VERSION ""

NS_ :

BS_:

BU_: TestTool_HS BCP_HS ECM_HS TCM_HS CGM_HS BCM_HS EBCM_OBD_HS ACCM_HS EBCM_HS TCCM_HS SAS_HS ICCM_OBD_HS ICCM_HS EPS_HS EPB_HS HMIM_HS ONSTAR_HS

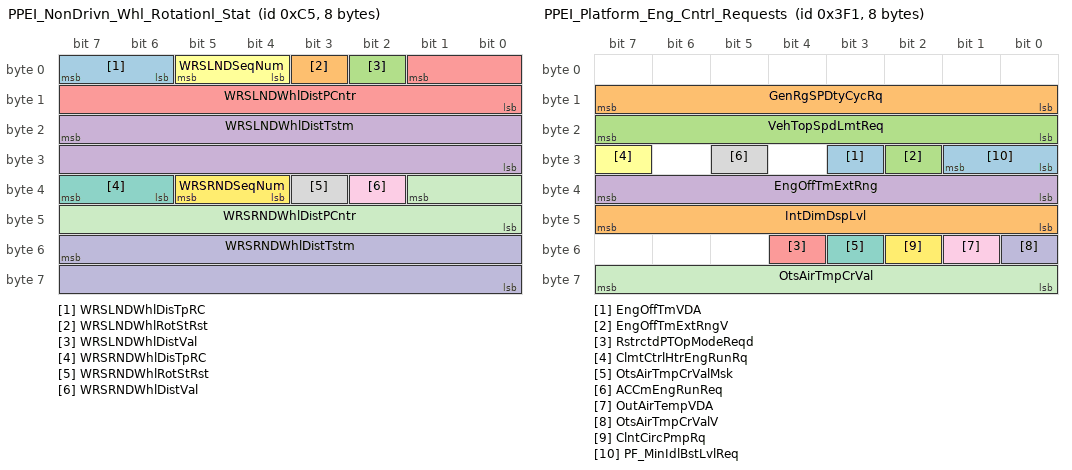
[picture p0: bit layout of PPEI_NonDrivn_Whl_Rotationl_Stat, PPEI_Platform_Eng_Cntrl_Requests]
BO_ 197 PPEI_NonDrivn_Whl_Rotationl_Stat: 8 EBCM_HS
 SG_ WRSLNDWhlDisTpRC : 7|2@0+ (1,0) [0|3] "counts"  CGM_HS,ICCM_OBD_HS,ICCM_HS,HMIM_HS,EPS_HS,BCP_HS,ONSTAR_HS,EPB_HS,TCCM_HS,BCM_HS,TCM_HS,ECM_HS
 SG_ WRSLNDWhlRotStRst : 3|1@0+ (1,0) [0|1] ""  CGM_HS,ICCM_OBD_HS,ICCM_HS,HMIM_HS,EPS_HS,BCP_HS,ONSTAR_HS,EPB_HS,TCCM_HS,BCM_HS,TCM_HS,ECM_HS
 SG_ WRSLNDWhlDistVal : 2|1@0+ (1,0) [0|1] ""  CGM_HS,ICCM_OBD_HS,ICCM_HS,HMIM_HS,EPS_HS,BCP_HS,ONSTAR_HS,EPB_HS,TCCM_HS,BCM_HS,TCM_HS,ECM_HS
 SG_ WRSLNDWhlDistTstm : 23|16@0+ (1,0) [0|65535] "counts"  CGM_HS,ICCM_OBD_HS,ICCM_HS,HMIM_HS,EPS_HS,BCP_HS,ONSTAR_HS,EPB_HS,TCCM_HS,BCM_HS,TCM_HS,ECM_HS
 SG_ WRSLNDWhlDistPCntr : 1|10@0+ (1,0) [0|1023] "counts"  CGM_HS,ICCM_OBD_HS,ICCM_HS,HMIM_HS,EPS_HS,BCP_HS,ONSTAR_HS,EPB_HS,TCCM_HS,BCM_HS,TCM_HS,ECM_HS
 SG_ WRSLNDSeqNum : 5|2@0+ (1,0) [0|3] "counts"  CGM_HS,ICCM_OBD_HS,ICCM_HS,HMIM_HS,EPS_HS,BCP_HS,ONSTAR_HS,EPB_HS,TCCM_HS,BCM_HS,TCM_HS,ECM_HS
 SG_ WRSRNDWhlDisTpRC : 39|2@0+ (1,0) [0|3] "counts"  CGM_HS,ICCM_OBD_HS,ICCM_HS,HMIM_HS,EPS_HS,BCP_HS,ONSTAR_HS,EPB_HS,TCCM_HS,BCM_HS,TCM_HS,ECM_HS
 SG_ WRSRNDWhlRotStRst : 35|1@0+ (1,0) [0|1] ""  CGM_HS,ICCM_OBD_HS,ICCM_HS,HMIM_HS,EPS_HS,BCP_HS,ONSTAR_HS,EPB_HS,TCCM_HS,BCM_HS,TCM_HS,ECM_HS
 SG_ WRSRNDWhlDistVal : 34|1@0+ (1,0) [0|1] ""  CGM_HS,ICCM_OBD_HS,ICCM_HS,HMIM_HS,EPS_HS,BCP_HS,ONSTAR_HS,EPB_HS,TCCM_HS,BCM_HS,TCM_HS,ECM_HS
 SG_ WRSRNDWhlDistTstm : 55|16@0+ (1,0) [0|65535] "counts"  CGM_HS,ICCM_OBD_HS,ICCM_HS,HMIM_HS,EPS_HS,BCP_HS,ONSTAR_HS,EPB_HS,TCCM_HS,BCM_HS,TCM_HS,ECM_HS
 SG_ WRSRNDWhlDistPCntr : 33|10@0+ (1,0) [0|1023] "counts"  CGM_HS,ICCM_OBD_HS,ICCM_HS,HMIM_HS,EPS_HS,BCP_HS,ONSTAR_HS,EPB_HS,TCCM_HS,BCM_HS,TCM_HS,ECM_HS
 SG_ WRSRNDSeqNum : 37|2@0+ (1,0) [0|3] "counts"  CGM_HS,ICCM_OBD_HS,ICCM_HS,HMIM_HS,EPS_HS,BCP_HS,ONSTAR_HS,EPB_HS,TCCM_HS,BCM_HS,TCM_HS,ECM_HS

BO_ 1009 PPEI_Platform_Eng_Cntrl_Requests: 8 BCM_HS
 SG_ EngOffTmVDA : 27|1@0+ (1,0) [0|1] ""  ICCM_OBD_HS,ICCM_HS,EPS_HS,EBCM_OBD_HS,EPB_HS,TCCM_HS,EBCM_HS
 SG_ IntDimDspLvl : 47|8@0+ (0.392157,0) [0|100.000035] "%"  TCCM_HS
 SG_ EngOffTmExtRngV : 26|1@0+ (1,0) [0|1] ""  ICCM_OBD_HS,ICCM_HS,EPS_HS,EBCM_OBD_HS,EPB_HS,TCCM_HS,EBCM_HS
 SG_ EngOffTmExtRng : 39|8@0+ (4,0) [0|1020] "min"  ICCM_OBD_HS,ICCM_HS,EPS_HS,EBCM_OBD_HS,EPB_HS,TCCM_HS,EBCM_HS
 SG_ RstrctdPTOpModeReqd : 52|1@0+ (1,0) [0|1] ""  ECM_HS
 SG_ ClmtCtrlHtrEngRunRq : 31|1@0+ (1,0) [0|1] ""  ECM_HS
 SG_ OtsAirTmpCrValMsk : 51|1@0+ (1,0) [0|1] ""  ICCM_OBD_HS,ICCM_HS,EPS_HS,ECM_HS
 SG_ ACCmEngRunReq : 29|1@0+ (1,0) [0|1] ""  BCP_HS,ECM_HS
 SG_ OutAirTempVDA : 49|1@0+ (1,0) [0|1] ""  ICCM_OBD_HS,ICCM_HS,ECM_HS
 SG_ OtsAirTmpCrValV : 48|1@0+ (1,0) [0|1] ""  ICCM_OBD_HS,ICCM_HS,EPS_HS,EBCM_OBD_HS,EBCM_HS,ECM_HS
 SG_ OtsAirTmpCrVal : 63|8@0+ (0.5,-40) [-40|87.5] "deg C"  ICCM_OBD_HS,ICCM_HS,EPS_HS,EBCM_OBD_HS,EBCM_HS,ECM_HS
 SG_ ClntCircPmpRq : 50|1@0+ (1,0) [0|1] ""  ECM_HS
 SG_ PF_MinIdlBstLvlReq : 25|2@0+ (1,0) [0|3] ""  ECM_HS
 SG_ GenRgSPDtyCycRq : 15|8@0+ (0.392157,0) [0|100.000035] "%"  ECM_HS
 SG_ VehTopSpdLmtReq : 23|8@0+ (2,0) [0|510] "km / h"  ECM_HS

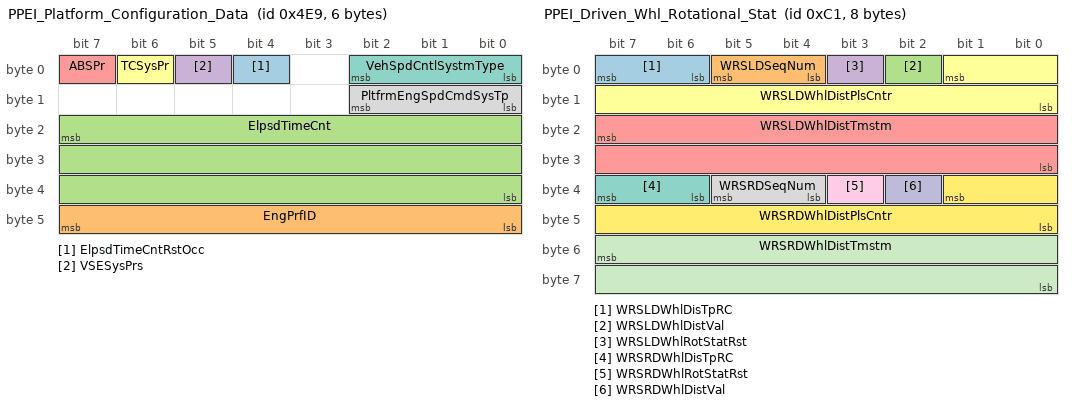
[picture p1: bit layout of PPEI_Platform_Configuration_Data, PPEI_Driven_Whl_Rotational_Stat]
BO_ 1257 PPEI_Platform_Configuration_Data: 6 BCM_HS
 SG_ ElpsdTimeCntRstOcc : 4|1@0+ (1,0) [0|1] "" Vector__XXX
 SG_ EngPrfID : 47|8@0+ (2,0) [0|510] "kW"  ECM_HS
 SG_ ElpsdTimeCnt : 23|24@0+ (1,0) [0|16777215] "min"  ECM_HS
 SG_ VSESysPrs : 5|1@0+ (1,0) [0|1] ""  TCCM_HS,TCM_HS,ECM_HS
 SG_ ABSPr : 7|1@0+ (1,0) [0|1] ""  TCCM_HS,TCM_HS,ECM_HS
 SG_ TCSysPr : 6|1@0+ (1,0) [0|1] ""  TCCM_HS,TCM_HS,ECM_HS
 SG_ VehSpdCntlSystmType : 2|3@0+ (1,0) [0|7] ""  ECM_HS
 SG_ PltfrmEngSpdCmdSysTp : 10|3@0+ (1,0) [0|7] ""  TCM_HS,ECM_HS

BO_ 505 PPEI_PTO_Command_Data: 8 BCM_HS
 SG_ AllNodesVNA_1F9 : 43|1@0+ (1,0) [0|1] ""  CGM_HS,BCM_HS
 SG_ PTOVehTopSpdLimVal : 63|8@0+ (2,0) [0|510] "km / h"  CGM_HS,BCM_HS
 SG_ PTORmtEngStrtReq : 44|1@0+ (1,0) [0|1] ""  CGM_HS,BCM_HS
 SG_ PTOTGRReqdGear : 35|4@0+ (1,0) [0|15] ""  CGM_HS,TCM_HS
 SG_ PTOTGRReqType : 37|2@0+ (1,0) [0|3] ""  CGM_HS,TCM_HS
 SG_ TrnsPTOCltchRelRqd : 38|1@0+ (1,0) [0|1] ""  CGM_HS,TCM_HS
 SG_ AccPdlPwrTkOffOvrAct : 4|1@0+ (1,0) [0|1] ""  CGM_HS,ECM_HS
 SG_ FstIdlMdAct : 47|1@0+ (1,0) [0|1] ""  CGM_HS,BCM_HS,ECM_HS
 SG_ PTOMdAct : 46|1@0+ (1,0) [0|1] ""  CGM_HS,EBCM_OBD_HS,EBCM_HS,ECM_HS
 SG_ PTOEngTrqLmtRchd : 45|1@0+ (1,0) [0|1] ""  CGM_HS,ECM_HS
 SG_ PTOEngTrqLmtValER : 55|8@0+ (8,0) [0|2040] "Nm"  CGM_HS,ECM_HS
 SG_ PltfrmEngSpdCmdMdAct : 3|1@0+ (1,0) [0|1] ""  CGM_HS,EBCM_OBD_HS,TCM_HS,EBCM_HS,ECM_HS
 SG_ PltfrmEngSpdReq : 2|11@0+ (4,0) [0|8188] "rpm"  CGM_HS,EBCM_OBD_HS,TCM_HS,EBCM_HS,ECM_HS
 SG_ PFESpdCmdOnSwAct : 7|1@0+ (1,0) [0|1] ""  CGM_HS,ECM_HS
 SG_ PFESpdCmdDeSwAct : 5|1@0+ (1,0) [0|1] ""  CGM_HS,ECM_HS
 SG_ PFESpdCmdInSwAct : 6|1@0+ (1,0) [0|1] ""  CGM_HS,ECM_HS
 SG_ PFESpdCmdSwDIntg : 21|2@0+ (1,0) [0|3] ""  CGM_HS,ECM_HS
 SG_ PFEngSpdCmdAlvRlgCnt : 23|2@0+ (1,0) [0|3] ""  CGM_HS,EBCM_OBD_HS,TCM_HS,EBCM_HS,ECM_HS
 SG_ PltfrmEngSpdCmdProtVal : 19|12@0+ (1,0) [0|4095] ""  CGM_HS,EBCM_OBD_HS,EBCM_HS,ECM_HS
 SG_ PTORmtEngShtdwnReqd : 39|1@0+ (1,0) [0|1] ""  CGM_HS,BCM_HS,ECM_HS

BO_ 497 PPEI_Platform_General_Status: 8 BCM_HS
 SG_ BkupPwrModeMstrVDA : 7|1@0+ (1,0) [0|1] ""  CGM_HS,HMIM_HS,EBCM_OBD_HS,TCCM_HS,EBCM_HS
 SG_ PrkBrkVDA : 35|1@0+ (1,0) [0|1] ""  CGM_HS,TCCM_HS
 SG_ PrkBrkVDM : 62|1@0+ (1,0) [0|1] ""  CGM_HS
 SG_ BkupPwrModeMstrVDM : 61|1@0+ (1,0) [0|1] ""  CGM_HS
 SG_ ACCompSysVDM : 60|1@0+ (1,0) [0|1] ""  CGM_HS
 SG_ ElvtdIdlCstStReq : 33|2@0+ (1,0) [0|3] ""  CGM_HS,ECM_HS
 SG_ FuelFltLfRstRqd : 56|1@0+ (1,0) [0|1] ""  CGM_HS,TCCM_HS,ECM_HS
 SG_ ACCompSysVDA : 9|1@0+ (1,0) [0|1] ""  CGM_HS,BCP_HS,ECM_HS
 SG_ AirbgVDA : 57|1@0+ (1,0) [0|1] ""  CGM_HS,ICCM_OBD_HS,ICCM_HS,HMIM_HS,BCP_HS,TCCM_HS,ECM_HS
 SG_ SysBkupPwrMdEn : 6|1@0+ (1,0) [0|1] ""  CGM_HS,ICCM_OBD_HS,SAS_HS,ICCM_HS,HMIM_HS,EPS_HS,BCP_HS,EBCM_OBD_HS,EPB_HS,TCCM_HS,TCM_HS,EBCM_HS,ECM_HS
 SG_ SysBkUpPwrMd : 5|2@0+ (1,0) [0|3] ""  CGM_HS,ICCM_OBD_HS,SAS_HS,ICCM_HS,HMIM_HS,EPS_HS,BCP_HS,EBCM_OBD_HS,EPB_HS,TCCM_HS,TCM_HS,EBCM_HS,ECM_HS
 SG_ SysPwrMd : 1|2@0+ (1,0) [0|3] ""  CGM_HS,ICCM_OBD_HS,SAS_HS,ICCM_HS,HMIM_HS,EPS_HS,BCP_HS,EBCM_OBD_HS,EPB_HS,TCCM_HS,TCM_HS,EBCM_HS,ECM_HS
 SG_ TrStLgMdAtv : 34|1@0+ (1,0) [0|1] ""  CGM_HS,ICCM_OBD_HS,SAS_HS,ACCM_HS,ICCM_HS,HMIM_HS,EPS_HS,EBCM_OBD_HS,EPB_HS,TCCM_HS,TCM_HS,EBCM_HS,ECM_HS
 SG_ DispMeasSys : 59|1@0+ (1,0) [0|1] ""  CGM_HS,TCCM_HS,ECM_HS
 SG_ ACCmpsrFldOn : 63|1@0+ (1,0) [0|1] ""  CGM_HS,TCCM_HS,ECM_HS
 SG_ ACCompModReq : 12|2@0+ (1,0) [0|3] ""  CGM_HS,TCCM_HS,ECM_HS
 SG_ ACCompNormLd : 55|8@0+ (0.1,0) [0|25.5] "l/min"  CGM_HS,BCP_HS,TCCM_HS,ECM_HS
 SG_ ACCompNormLdV : 10|1@0+ (1,0) [0|1] ""  CGM_HS,BCP_HS,TCCM_HS,ECM_HS
 SG_ PTORSMstrEngShtReq : 13|1@0+ (1,0) [0|1] ""  CGM_HS,TCCM_HS,ECM_HS
 SG_ EngOilLfRstRq : 37|1@0+ (1,0) [0|1] ""  CGM_HS,TCCM_HS,ECM_HS
 SG_ SIRDpl : 58|1@0+ (1,0) [0|1] ""  CGM_HS,ICCM_OBD_HS,ICCM_HS,HMIM_HS,BCP_HS,TCCM_HS,ECM_HS
 SG_ PTORmStMsEngStRq : 14|1@0+ (1,0) [0|1] ""  CGM_HS,TCCM_HS,TCM_HS,ECM_HS
 SG_ RmVehStrRq : 15|1@0+ (1,0) [0|1] ""  CGM_HS,BCP_HS,TCCM_HS,EPB_HS,ECM_HS
 SG_ ThrtlPrgrsnReq : 39|2@0+ (1,0) [0|3] ""  CGM_HS,TCCM_HS,ECM_HS
 SG_ PrkBrkSwAtv : 36|1@0+ (1,0) [0|1] ""  CGM_HS,ICCM_OBD_HS,ICCM_HS,EBCM_OBD_HS,TCCM_HS,EBCM_HS,ECM_HS
 SG_ PMMAccTrmSt : 2|1@0+ (1,0) [0|1] ""  CGM_HS,TCCM_HS,TCM_HS,ECM_HS
 SG_ PMMRunCrkTrmSt : 3|1@0+ (1,0) [0|1] ""  CGM_HS,TCCM_HS,TCM_HS,ECM_HS
 SG_ ImmblzrPreRelPswdStat : 8|1@0+ (1,0) [0|1] ""  CGM_HS,TCCM_HS,ECM_HS
 SG_ ImmblzrPreRelPswrd : 23|16@0+ (1,0) [0|65535] "passwrd"  CGM_HS,TCCM_HS,ECM_HS

BO_ 969 PPEI_Platform_Immobilizer_Data: 8 BCM_HS
 SG_ ImoInf : 7|64@0+ (1,0) [0|1.84467440737096E+019] ""  ECM_HS

BO_ 1249 PPEI_VIN_Digits_10_to_17: 8 BCM_HS
 SG_ VehIdNmDig10_17 : 7|64@0+ (1,0) [0|1] ""  CGM_HS,EPS_HS,BCP_HS,EBCM_OBD_HS,TCCM_HS,EPB_HS,TCM_HS,EBCM_HS,ECM_HS

BO_ 193 PPEI_Driven_Whl_Rotational_Stat: 8 EBCM_HS
 SG_ WRSLDWhlDisTpRC : 7|2@0+ (1,0) [0|3] "counts"  CGM_HS,ICCM_OBD_HS,ICCM_HS,HMIM_HS,EPS_HS,BCP_HS,ONSTAR_HS,TCCM_HS,EPB_HS,BCM_HS,TCM_HS,ECM_HS
 SG_ WRSLDSeqNum : 5|2@0+ (1,0) [0|3] "counts"  CGM_HS,ICCM_OBD_HS,ICCM_HS,HMIM_HS,EPS_HS,BCP_HS,ONSTAR_HS,TCCM_HS,EPB_HS,BCM_HS,TCM_HS,ECM_HS
 SG_ WRSLDWhlDistVal : 2|1@0+ (1,0) [0|1] ""  CGM_HS,ICCM_OBD_HS,ICCM_HS,HMIM_HS,EPS_HS,BCP_HS,ONSTAR_HS,TCCM_HS,EPB_HS,BCM_HS,TCM_HS,ECM_HS
 SG_ WRSLDWhlRotStatRst : 3|1@0+ (1,0) [0|1] ""  CGM_HS,ICCM_OBD_HS,ICCM_HS,HMIM_HS,EPS_HS,BCP_HS,ONSTAR_HS,TCCM_HS,EPB_HS,BCM_HS,TCM_HS,ECM_HS
 SG_ WRSLDWhlDistTmstm : 23|16@0+ (1,0) [0|65535] "counts"  CGM_HS,ICCM_OBD_HS,ICCM_HS,HMIM_HS,EPS_HS,BCP_HS,ONSTAR_HS,TCCM_HS,EPB_HS,BCM_HS,TCM_HS,ECM_HS
 SG_ WRSLDWhlDistPlsCntr : 1|10@0+ (1,0) [0|1023] "counts"  CGM_HS,ICCM_OBD_HS,ICCM_HS,HMIM_HS,EPS_HS,BCP_HS,ONSTAR_HS,TCCM_HS,EPB_HS,BCM_HS,TCM_HS,ECM_HS
 SG_ WRSRDWhlDisTpRC : 39|2@0+ (1,0) [0|3] "counts"  CGM_HS,ICCM_OBD_HS,ICCM_HS,HMIM_HS,EPS_HS,BCP_HS,ONSTAR_HS,TCCM_HS,EPB_HS,BCM_HS,TCM_HS,ECM_HS
 SG_ WRSRDSeqNum : 37|2@0+ (1,0) [0|3] "counts"  CGM_HS,ICCM_OBD_HS,ICCM_HS,HMIM_HS,EPS_HS,BCP_HS,ONSTAR_HS,TCCM_HS,EPB_HS,BCM_HS,TCM_HS,ECM_HS
 SG_ WRSRDWhlRotStatRst : 35|1@0+ (1,0) [0|1] ""  CGM_HS,ICCM_OBD_HS,ICCM_HS,HMIM_HS,EPS_HS,BCP_HS,ONSTAR_HS,TCCM_HS,EPB_HS,BCM_HS,TCM_HS,ECM_HS
 SG_ WRSRDWhlDistVal : 34|1@0+ (1,0) [0|1] ""  CGM_HS,ICCM_OBD_HS,ICCM_HS,HMIM_HS,EPS_HS,BCP_HS,ONSTAR_HS,TCCM_HS,EPB_HS,BCM_HS,TCM_HS,ECM_HS
 SG_ WRSRDWhlDistTmstm : 55|16@0+ (1,0) [0|65535] "counts"  CGM_HS,ICCM_OBD_HS,ICCM_HS,HMIM_HS,EPS_HS,ONSTAR_HS,BCP_HS,TCCM_HS,EPB_HS,BCM_HS,TCM_HS,ECM_HS
 SG_ WRSRDWhlDistPlsCntr : 33|10@0+ (1,0) [0|1023] "counts"  CGM_HS,ICCM_OBD_HS,ICCM_HS,HMIM_HS,EPS_HS,ONSTAR_HS,BCP_HS,TCCM_HS,EPB_HS,BCM_HS,TCM_HS,ECM_HS

BO_ 481 PPEI_Cruise_Control_Sw_Status: 7 BCM_HS
 SG_ AdptCrsGapSwAct : 23|2@0+ (1,0) [0|3] ""  CGM_HS
 SG_ CrsSecSwStat : 27|4@0+ (1,0) [0|15] ""  CGM_HS,ECM_HS
 SG_ DrvSelMdSw3Sta : 37|1@0+ (1,0) [0|1] ""  CGM_HS,ECM_HS
 SG_ DrvSelMdSw2Sta : 38|1@0+ (1,0) [0|1] ""  CGM_HS,ECM_HS
 SG_ AuxHtrRq : 31|1@0+ (1,0) [0|1] ""  CGM_HS,ECM_HS
 SG_ AuxHtrAtv : 30|1@0+ (1,0) [0|1] ""  CGM_HS,ECM_HS
 SG_ DrvSelMdSwStaARC : 33|2@0+ (1,0) [0|3] ""  CGM_HS,ECM_HS
 SG_ DrvSelMdSw1Sta : 39|1@0+ (1,0) [0|1] ""  CGM_HS,ECM_HS
 SG_ CrsSpdLmtrSwStatPVal : 55|4@0+ (1,0) [0|15] ""  CGM_HS,ECM_HS
 SG_ CrsSpdLmtrSwStatARC : 43|2@0+ (1,0) [0|3] ""  CGM_HS,ECM_HS
 SG_ FuelMdSwActV : 29|1@0+ (1,0) [0|1] ""  CGM_HS,ECM_HS
 SG_ FuelMdSwAct : 28|1@0+ (1,0) [0|1] ""  CGM_HS,ECM_HS
 SG_ CrsSpdLmtrSwStat : 47|4@0+ (1,0) [0|15] ""  CGM_HS,ECM_HS
 SG_ CrsCntrlSwStCanSwAct : 7|1@0+ (1,0) [0|1] ""  CGM_HS,ECM_HS
 SG_ CrsCntrlSwStSwDataIntgty : 1|2@0+ (1,0) [0|3] ""  CGM_HS,ECM_HS
 SG_ CrsCntrlSwStSpdInSwAct : 3|1@0+ (1,0) [0|1] ""  CGM_HS,ECM_HS
 SG_ CrsCntrlSwStSpDcSwAct : 2|1@0+ (1,0) [0|1] ""  CGM_HS,ECM_HS
 SG_ CrsCntrlSwStSetSwAct : 4|1@0+ (1,0) [0|1] ""  CGM_HS,ECM_HS
 SG_ CrsCntrlSwStResSwAct : 5|1@0+ (1,0) [0|1] ""  CGM_HS,ECM_HS
 SG_ CrsCntrlSwStOnSwAct : 6|1@0+ (1,0) [0|1] ""  CGM_HS,ECM_HS
 SG_ CrsCntrlSwStatProtValue : 15|8@0+ (1,0) [0|255] ""  CGM_HS,ECM_HS
 SG_ CrsCntrlSwStAlvRollCnt : 17|2@0+ (1,0) [0|3] ""  CGM_HS,ECM_HS
 SG_ CrsCntCncRq : 18|1@0+ (1,0) [0|1] ""  CGM_HS,ECM_HS
 SG_ CrsSecSwStatPVal : 51|4@0+ (1,0) [0|15] ""  CGM_HS,ECM_HS
 SG_ CrsSecSwStatARC : 41|2@0+ (1,0) [0|3] ""  CGM_HS,ECM_HS

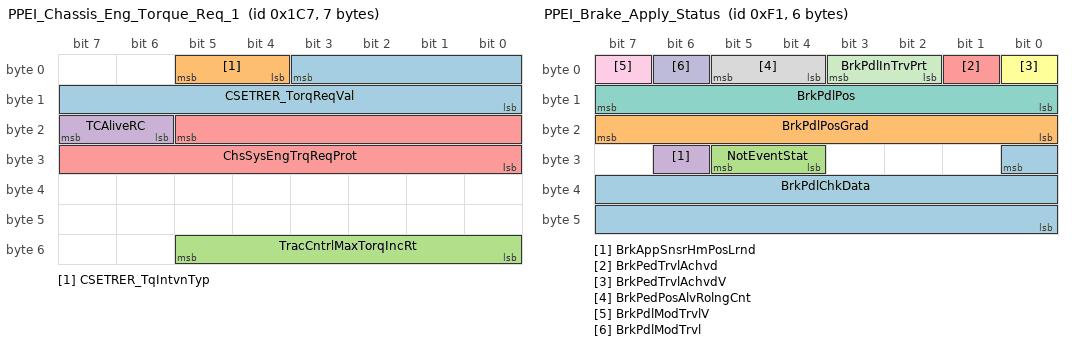
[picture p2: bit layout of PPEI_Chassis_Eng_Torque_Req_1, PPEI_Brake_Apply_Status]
BO_ 455 PPEI_Chassis_Eng_Torque_Req_1: 7 EBCM_HS
 SG_ CSETRER_TorqReqVal : 3|12@0+ (0.5,-848) [-848|1199.5] "Nm"  CGM_HS,ICCM_OBD_HS,ICCM_HS,ECM_HS
 SG_ CSETRER_TqIntvnTyp : 5|2@0+ (1,0) [0|3] ""  CGM_HS,ICCM_OBD_HS,ICCM_HS,ECM_HS
 SG_ TracCntrlMaxTorqIncRt : 53|6@0+ (16,0) [0|1008] "Nm/s"  CGM_HS,ECM_HS
 SG_ TCAliveRC : 23|2@0+ (1,0) [0|3] ""  CGM_HS,ECM_HS
 SG_ ChsSysEngTrqReqProt : 21|14@0+ (1,0) [0|16383] ""  CGM_HS,ECM_HS

BO_ 761 PPEI_Chassis_General_Status_2: 7 EBCM_HS
 SG_ SprTireSt : 10|3@0+ (1,0) [0|7] ""  CGM_HS,ICCM_OBD_HS,ICCM_HS,EPS_HS,TCCM_HS,BCM_HS
 SG_ BrkSysHRBkCtrlAvail : 24|1@0+ (1,0) [0|1] ""  CGM_HS,TCM_HS
 SG_ BrkSysHRBkCtrlStat : 26|2@0+ (1,0) [0|3] ""  CGM_HS,TCM_HS
 SG_ BrkSysHSAAval : 27|1@0+ (1,0) [0|1] ""  CGM_HS,TCM_HS
 SG_ BrkSysHSAStat : 30|3@0+ (1,0) [0|7] ""  CGM_HS,TCM_HS
 SG_ HillDscntCtrlStatPVal : 17|2@0+ (1,0) [0|3] ""  CGM_HS,ECM_HS
 SG_ HillDscntCtrlStatARC : 19|2@0+ (1,0) [0|3] ""  CGM_HS,ECM_HS
 SG_ HillDscntCtrlStat : 21|2@0+ (1,0) [0|3] ""  CGM_HS,ECM_HS
 SG_ AutoBrkFeatInhbtPVal : 49|2@0+ (1,0) [0|3] ""  CGM_HS,ECM_HS
 SG_ AutoBrkFeatInhbtARC : 51|2@0+ (1,0) [0|3] ""  CGM_HS,ECM_HS
 SG_ ABFI_CollPrepSysInhbt : 52|1@0+ (1,0) [0|1] ""  CGM_HS,ECM_HS
 SG_ ABFI_RrVirtlBmprInh : 53|1@0+ (1,0) [0|1] ""  CGM_HS,ECM_HS
 SG_ BrkPdlDrvApplPresV : 12|1@0+ (1,0) [0|1] ""  CGM_HS,ICCM_OBD_HS,ICCM_HS,EPS_HS,BCP_HS,TCCM_HS,TCM_HS,ECM_HS
 SG_ BrkPdlDrvApplPres : 47|8@0+ (75,0) [0|19125] "kPa"  CGM_HS,ICCM_OBD_HS,ICCM_HS,EPS_HS,BCP_HS,TCCM_HS,TCM_HS,ECM_HS
 SG_ AutoBrkPTReqStat : 15|3@0+ (1,0) [0|7] ""  CGM_HS,ECM_HS
 SG_ WhlSpdSnsgDTCIndex : 7|5@0+ (1,0) [0|31] ""  CGM_HS,ECM_HS
 SG_ WhlSpdSnsgDTCStat : 2|3@0+ (1,0) [0|7] ""  CGM_HS,ECM_HS

BO_ 489 PPEI_Chassis_General_Status_1: 8 EBCM_HS
 SG_ VehDynYawRateV : 36|1@0+ (1,0) [0|1] ""  CGM_HS,ICCM_OBD_HS,ICCM_HS,HMIM_HS,EPS_HS,ONSTAR_HS,TCCM_HS,BCM_HS
 SG_ VehDynYawRate : 35|12@0- (0.0625,0) [-128|127.9375] "deg/sec"  CGM_HS,ICCM_OBD_HS,ICCM_HS,HMIM_HS,EPS_HS,ONSTAR_HS,TCCM_HS,BCM_HS
 SG_ BSTGRReqdGear : 19|4@0+ (1,0) [0|15] ""  CGM_HS,TCM_HS
 SG_ BSTGRReqType : 21|2@0+ (1,0) [0|3] ""  CGM_HS,TCM_HS
 SG_ TrnsBrkSysCltchRelRqd : 5|1@0+ (1,0) [0|1] ""  CGM_HS,TCCM_HS,TCM_HS
 SG_ EnhDrvMdSwChUseRq : 53|1@0+ (1,0) [0|1] ""  CGM_HS,ECM_HS
 SG_ DrvIndpntBrkAppAct : 55|1@0+ (1,0) [0|1] ""  CGM_HS,TCM_HS,ECM_HS
 SG_ WhlSlpSt : 52|2@0+ (1,0) [0|3] ""  CGM_HS,TCM_HS,ECM_HS
 SG_ VSELatAccV : 4|1@0+ (1,0) [0|1] ""  CGM_HS,ICCM_OBD_HS,ICCM_HS,EPS_HS,TCCM_HS,EPB_HS,BCM_HS,TCM_HS,ECM_HS
 SG_ VSELatAcc : 3|12@0- (0.015625,0) [-32|31.984375] "m/s^2"  CGM_HS,ICCM_OBD_HS,ICCM_HS,EPS_HS,TCCM_HS,EPB_HS,BCM_HS,TCM_HS,ECM_HS
 SG_ VSEAct : 24|1@0+ (1,0) [0|1] ""  CGM_HS,ICCM_OBD_HS,ICCM_HS,EPS_HS,TCCM_HS,EPB_HS,BCM_HS,ECM_HS
 SG_ VhDynCntlSysSt : 39|3@0+ (1,0) [0|7] ""  CGM_HS,HMIM_HS,EPS_HS,TCCM_HS,EPB_HS,ECM_HS
 SG_ TracCntrlSysDrIntnt : 26|1@0+ (1,0) [0|1] ""  CGM_HS,EPS_HS,ECM_HS
 SG_ TCSysEnbld : 27|1@0+ (1,0) [0|1] ""  CGM_HS,EPS_HS,BCP_HS,TCM_HS,ECM_HS
 SG_ TCSysAtv : 28|1@0+ (1,0) [0|1] ""  CGM_HS,EPS_HS,TCCM_HS,EPB_HS,BCM_HS,TCM_HS,ECM_HS
 SG_ BrkPdlDrvAppPrsDetcdV : 7|1@0+ (1,0) [0|1] ""  CGM_HS,EPS_HS,TCCM_HS,TCM_HS,ECM_HS
 SG_ BrkPdlDrvAppPrsDetcd : 6|1@0+ (1,0) [0|1] ""  CGM_HS,EPS_HS,TCCM_HS,TCM_HS,ECM_HS
 SG_ ACCBrkngAct : 31|1@0+ (1,0) [0|1] ""  CGM_HS,TCM_HS,ECM_HS
 SG_ ABSFld : 29|1@0+ (1,0) [0|1] ""  CGM_HS,ICCM_OBD_HS,ICCM_HS,EPS_HS,EPB_HS,TCM_HS,ECM_HS
 SG_ ABSAtv : 30|1@0+ (1,0) [0|1] ""  CGM_HS,ICCM_OBD_HS,ICCM_HS,EPS_HS,TCCM_HS,EPB_HS,BCM_HS,TCM_HS,ECM_HS
 SG_ IMUDataMsk : 25|1@0+ (1,0) [0|1] ""  CGM_HS,ONSTAR_HS
 SG_ VehDynOvrUndrStr : 49|10@0- (0.5,0) [-256|255.5] "%"  CGM_HS,EPS_HS,TCCM_HS
 SG_ VehDynOvrUndrStrV : 50|1@0+ (1,0) [0|1] ""  CGM_HS,EPS_HS,TCCM_HS

BO_ 381 Antilock_Brake_and_TC_Status_HS: 6 EBCM_HS
 SG_ HillDesCtrlRedVehSpIO : 39|1@0+ (1,0) [0|1] ""  CGM_HS,BCM_HS
 SG_ EBDFailed : 23|1@0+ (1,0) [0|1] ""  CGM_HS,BCM_HS
 SG_ StWhAnVDA : 17|1@0+ (1,0) [0|1] ""  CGM_HS,HMIM_HS,ONSTAR_HS,EPB_HS,BCM_HS
 SG_ TirePrsLowIO : 9|1@0+ (1,0) [0|1] ""  CGM_HS,BCM_HS
 SG_ VaccBoostFailure : 16|1@0+ (1,0) [0|1] ""  CGM_HS,BCM_HS
 SG_ VSESysPrs : 1|1@0+ (1,0) [0|1] ""  CGM_HS,EPB_HS,BCM_HS
 SG_ HalfSysFail : 18|1@0+ (1,0) [0|1] ""  CGM_HS,BCM_HS
 SG_ BksOvht : 8|1@0+ (1,0) [0|1] ""  CGM_HS,BCM_HS
 SG_ TCSysPr : 10|1@0+ (1,0) [0|1] ""  CGM_HS,EPB_HS,BCM_HS
 SG_ ABSPr : 22|1@0+ (1,0) [0|1] ""  CGM_HS,BCP_HS,EPB_HS,BCM_HS
 SG_ TreInfMonSysRstPrfmd : 11|1@0+ (1,0) [0|1] ""  CGM_HS,BCM_HS
 SG_ ABSIO : 12|1@0+ (1,0) [0|1] ""  CGM_HS,BCM_HS
 SG_ BrkPadWrnIO : 0|1@0+ (1,0) [0|1] ""  CGM_HS,BCM_HS
 SG_ VehStabEnhmntMd : 15|3@0+ (1,0) [0|7] ""  CGM_HS,ICCM_OBD_HS,ICCM_HS,TCCM_HS,BCM_HS
 SG_ VehStabEnhmntStat : 4|3@0+ (1,0) [0|7] ""  CGM_HS,EPS_HS,ONSTAR_HS,EPB_HS,BCM_HS
 SG_ TCSysOpMd : 7|3@0+ (1,0) [0|7] ""  CGM_HS,EPS_HS,TCCM_HS,BCM_HS
 SG_ TCSysOpStat : 38|3@0+ (1,0) [0|7] ""  CGM_HS,ONSTAR_HS,EPB_HS,BCM_HS
 SG_ BrkSysVTopSpdLimVal : 31|8@0+ (2,0) [0|510] "km / h"  CGM_HS,BCM_HS
 SG_ BrkSysRedBrkTlltlReq : 19|1@0+ (1,0) [0|1] ""  CGM_HS,ONSTAR_HS,BCM_HS
 SG_ BrkSysBrkLtsReqd : 21|1@0+ (1,0) [0|1] ""  CGM_HS,BCM_HS
 SG_ ActVehAccel : 35|12@0- (0.01,0) [-20.48|20.47] "m/s^2"  CGM_HS,BCP_HS,EPB_HS,BCM_HS,ECM_HS
 SG_ ActVehAccelV : 20|1@0+ (1,0) [0|1] ""  CGM_HS,BCP_HS,EPB_HS,BCM_HS,ECM_HS

BO_ 241 PPEI_Brake_Apply_Status: 6 BCM_HS
 SG_ BrkPdlChkData : 24|17@0+ (1,0) [0|131071] ""  CGM_HS
 SG_ BrkPdlPosGrad : 23|8@0- (40,0) [-5120|5080] "%/s"  CGM_HS,EPS_HS,EBCM_OBD_HS,EBCM_HS
 SG_ NotEventStat : 29|2@0+ (1,0) [0|3] ""  CGM_HS,EPS_HS,EBCM_OBD_HS,EBCM_HS,ECM_HS
 SG_ BrkAppSnsrHmPosLrnd : 30|1@0+ (1,0) [0|1] ""  CGM_HS,EPS_HS,EBCM_OBD_HS,EBCM_HS,ECM_HS
 SG_ BrkPedTrvlAchvd : 1|1@0+ (1,0) [0|1] ""  CGM_HS,ICCM_OBD_HS,ICCM_HS,EPS_HS,EBCM_OBD_HS,BCP_HS,TCCM_HS,EPB_HS,TCM_HS,EBCM_HS,ECM_HS
 SG_ BrkPedTrvlAchvdV : 0|1@0+ (1,0) [0|1] ""  CGM_HS,ICCM_OBD_HS,ICCM_HS,EPS_HS,EBCM_OBD_HS,BCP_HS,TCCM_HS,EPB_HS,TCM_HS,EBCM_HS,ECM_HS
 SG_ BrkPdlPos : 15|8@0+ (0.392157,0) [0|100.000035] "% full"  CGM_HS,EPS_HS,EBCM_OBD_HS,TCCM_HS,EPB_HS,TCM_HS,EBCM_HS,ECM_HS
 SG_ BrkPedPosAlvRolngCnt : 5|2@0+ (1,0) [0|3] ""  CGM_HS,ICCM_OBD_HS,ICCM_HS,EPS_HS,EBCM_OBD_HS,TCCM_HS,EPB_HS,TCM_HS,EBCM_HS,ECM_HS
 SG_ BrkPdlModTrvlV : 7|1@0+ (1,0) [0|1] ""  CGM_HS,EPS_HS,EBCM_OBD_HS,TCCM_HS,EPB_HS,TCM_HS,EBCM_HS,ECM_HS
 SG_ BrkPdlModTrvl : 6|1@0+ (1,0) [0|1] ""  CGM_HS,EPS_HS,EBCM_OBD_HS,TCCM_HS,EPB_HS,TCM_HS,EBCM_HS,ECM_HS
 SG_ BrkPdlInTrvPrt : 3|2@0+ (1,0) [0|3] ""  CGM_HS,ICCM_OBD_HS,ICCM_HS,EPS_HS,EBCM_OBD_HS,TCCM_HS,EPB_HS,EBCM_HS,TCM_HS,ECM_HS

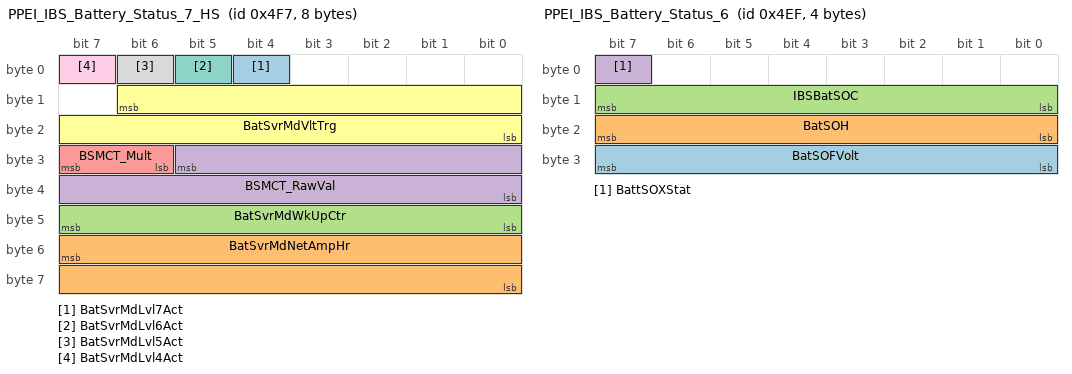
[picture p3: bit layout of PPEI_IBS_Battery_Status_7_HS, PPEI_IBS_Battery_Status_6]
BO_ 1271 PPEI_IBS_Battery_Status_7_HS: 8 ECM_HS
 SG_ BatSvrMdLvl7Act : 4|1@0+ (1,0) [0|1] ""  BCM_HS
 SG_ BatSvrMdNetAmpHr : 55|16@0+ (0.01,-327.67) [-327.67|327.68] "AmpHours"  BCM_HS
 SG_ BatSvrMdWkUpCtr : 47|8@0+ (1,0) [0|255] ""  BCM_HS
 SG_ BSMCT_RawVal : 29|14@0+ (0.001,-8.192) [-8.192|8.191] "A"  BCM_HS
 SG_ BSMCT_Mult : 31|2@0+ (1,0) [0|3] ""  BCM_HS
 SG_ BatSvrMdVltTrg : 14|15@0+ (0.001,0) [0|32.767] "V"  BCM_HS
 SG_ BatSvrMdLvl6Act : 5|1@0+ (1,0) [0|1] ""  BCM_HS
 SG_ BatSvrMdLvl5Act : 6|1@0+ (1,0) [0|1] ""  BCM_HS
 SG_ BatSvrMdLvl4Act : 7|1@0+ (1,0) [0|1] ""  BCM_HS

BO_ 1263 PPEI_IBS_Battery_Status_6: 4 ECM_HS
 SG_ BatSOFVolt : 31|8@0+ (0.05,0) [0|12.75] "volts"  BCM_HS
 SG_ BatSOH : 23|8@0+ (0.392157,0) [0|100.000035] "%"  BCM_HS
 SG_ IBSBatSOC : 15|8@0+ (0.392157,0) [0|100.000035] "%"  BCM_HS
 SG_ BattSOXStat : 7|1@0+ (1,0) [0|1] ""  BCM_HS

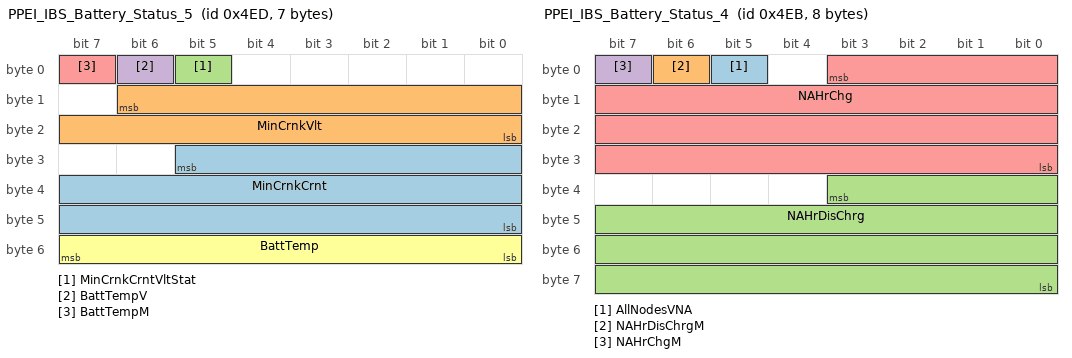
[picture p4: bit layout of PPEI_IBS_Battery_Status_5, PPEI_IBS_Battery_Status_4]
BO_ 1261 PPEI_IBS_Battery_Status_5: 7 ECM_HS
 SG_ MinCrnkCrnt : 29|22@0+ (0.001,-2097.152) [-2097.152|2097.151] "amps"  BCM_HS
 SG_ MinCrnkVlt : 14|15@0+ (0.001,0) [0|32.767] "volts"  BCM_HS
 SG_ MinCrnkCrntVltStat : 5|1@0+ (1,0) [0|1] ""  BCM_HS
 SG_ BattTempV : 6|1@0+ (1,0) [0|1] ""  BCM_HS
 SG_ BattTempM : 7|1@0+ (1,0) [0|1] ""  BCM_HS
 SG_ BattTemp : 55|8@0+ (1,-40) [-40|215] "deg C"  BCM_HS

BO_ 1259 PPEI_IBS_Battery_Status_4: 8 ECM_HS
 SG_ AllNodesVNA : 5|1@0+ (1,0) [0|1] ""  BCM_HS
 SG_ NAHrDisChrgM : 6|1@0+ (1,0) [0|1] ""  BCM_HS
 SG_ NAHrDisChrg : 35|28@0+ (0.001,0) [0|268435.455] "AmpHours"  BCM_HS
 SG_ NAHrChgM : 7|1@0+ (1,0) [0|1] ""  BCM_HS
 SG_ NAHrChg : 3|28@0+ (0.001,0) [0|268435.455] "AmpHours"  BCM_HS

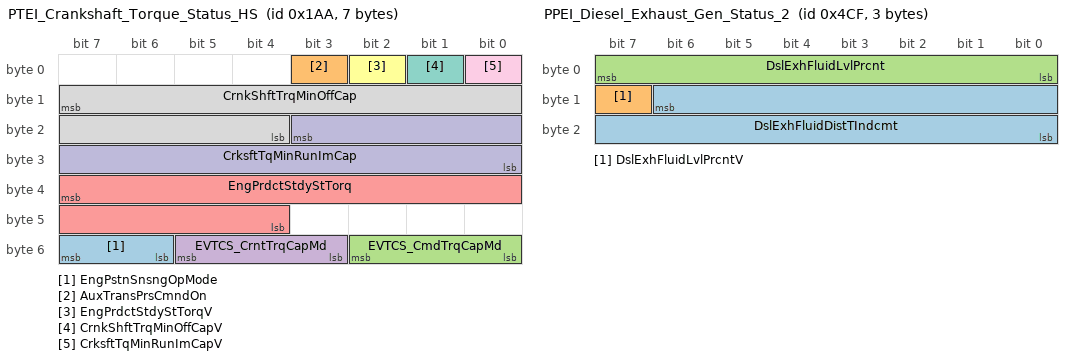
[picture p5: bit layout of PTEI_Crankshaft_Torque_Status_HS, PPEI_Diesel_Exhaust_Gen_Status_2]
BO_ 426 PTEI_Crankshaft_Torque_Status_HS: 7 ECM_HS
 SG_ EngPstnSnsngOpMode : 55|2@0+ (1,0) [0|3] "" Vector__XXX
 SG_ AuxTransPrsCmndOn : 3|1@0+ (1,0) [0|1] ""  TCM_HS
 SG_ EVTCS_CmdTrqCapMd : 50|3@0+ (1,0) [0|7] ""  TCM_HS
 SG_ EVTCS_CrntTrqCapMd : 53|3@0+ (1,0) [0|7] ""  TCM_HS
 SG_ EngPrdctStdyStTorq : 39|12@0+ (0.5,-848) [-848|1199.5] "Nm"  TCM_HS
 SG_ EngPrdctStdyStTorqV : 2|1@0+ (1,0) [0|1] ""  TCM_HS
 SG_ CrnkShftTrqMinOffCapV : 1|1@0+ (1,0) [0|1] ""  TCM_HS
 SG_ CrnkShftTrqMinOffCap : 15|12@0+ (0.5,-848) [-848|1199.5] "Nm"  TCM_HS
 SG_ CrksftTqMinRunImCapV : 0|1@0+ (1,0) [0|1] ""  TCM_HS
 SG_ CrksftTqMinRunImCap : 19|12@0+ (0.5,-848) [-848|1199.5] "Nm"  TCM_HS

BO_ 1231 PPEI_Diesel_Exhaust_Gen_Status_2: 3 ECM_HS
 SG_ DslExhFluidDistTIndcmt : 14|15@0+ (2,0) [0|65534] "km"  BCM_HS
 SG_ DslExhFluidLvlPrcntV : 15|1@0+ (1,0) [0|1] ""  BCM_HS
 SG_ DslExhFluidLvlPrcnt : 7|8@0+ (0.392157,0) [0|100.000035] "%"  BCM_HS

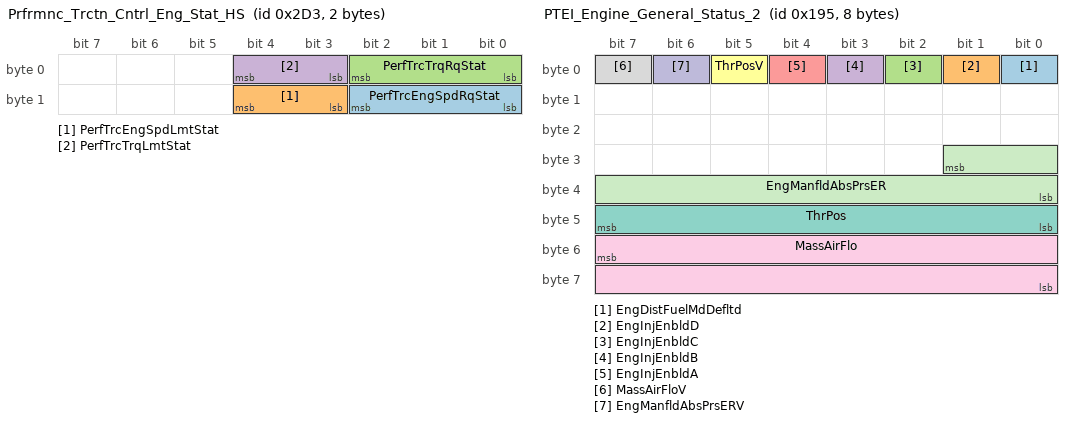
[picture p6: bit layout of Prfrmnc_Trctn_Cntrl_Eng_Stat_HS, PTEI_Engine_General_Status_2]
BO_ 723 Prfrmnc_Trctn_Cntrl_Eng_Stat_HS: 2 ECM_HS
 SG_ PerfTrcEngSpdRqStat : 10|3@0+ (1,0) [0|7] ""  EBCM_OBD_HS,EBCM_HS
 SG_ PerfTrcEngSpdLmtStat : 12|2@0+ (1,0) [0|3] ""  EBCM_OBD_HS,EBCM_HS
 SG_ PerfTrcTrqRqStat : 2|3@0+ (1,0) [0|7] ""  EBCM_OBD_HS,EBCM_HS
 SG_ PerfTrcTrqLmtStat : 4|2@0+ (1,0) [0|3] ""  EBCM_OBD_HS,EBCM_HS

BO_ 405 PTEI_Engine_General_Status_2: 8 ECM_HS
 SG_ EngDistFuelMdDefltd : 0|1@0+ (1,0) [0|1] "" Vector__XXX
 SG_ EngInjEnbldD : 1|1@0+ (1,0) [0|1] "" Vector__XXX
 SG_ EngInjEnbldC : 2|1@0+ (1,0) [0|1] "" Vector__XXX
 SG_ EngInjEnbldB : 3|1@0+ (1,0) [0|1] "" Vector__XXX
 SG_ EngInjEnbldA : 4|1@0+ (1,0) [0|1] "" Vector__XXX
 SG_ ThrPosV : 5|1@0+ (1,0) [0|1] "" Vector__XXX
 SG_ ThrPos : 47|8@0+ (0.392157,0) [0|100.000035] "%" Vector__XXX
 SG_ MassAirFloV : 7|1@0+ (1,0) [0|1] "" Vector__XXX
 SG_ MassAirFlo : 55|16@0+ (0.01,0) [0|655.35] "grams/s" Vector__XXX
 SG_ EngManfldAbsPrsERV : 6|1@0+ (1,0) [0|1] "" Vector__XXX
 SG_ EngManfldAbsPrsER : 25|10@0+ (0.5,0) [0|511.5] "kPa" Vector__XXX

BO_ 419 PTEI_Engine_Common_Use_1: 1 ECM_HS
 SG_ EngRunng : 7|1@0+ (1,0) [0|1] ""  EBCM_OBD_HS,BCP_HS,TCCM_HS,EBCM_HS,TCM_HS,BCM_HS

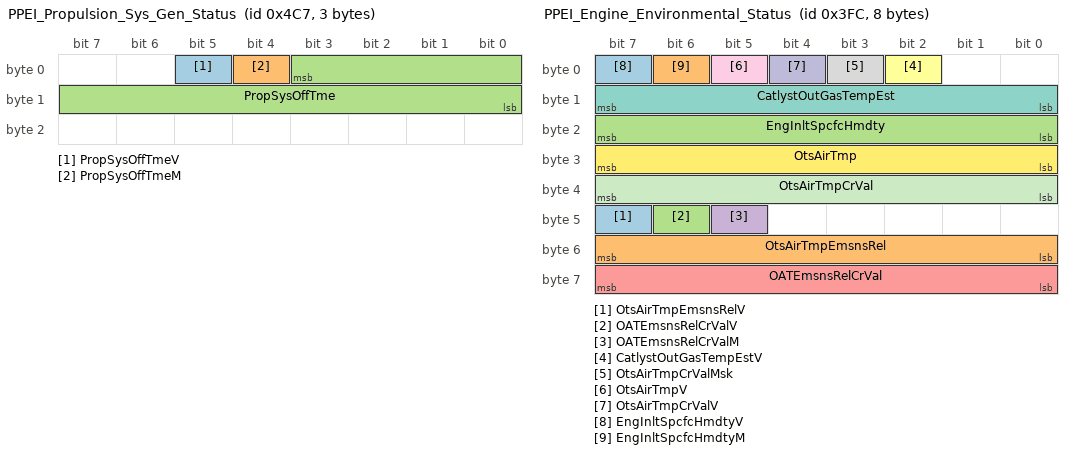
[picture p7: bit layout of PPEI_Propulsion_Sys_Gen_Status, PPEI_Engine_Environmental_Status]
BO_ 1223 PPEI_Propulsion_Sys_Gen_Status: 3 ECM_HS
 SG_ PropSysOffTmeV : 5|1@0+ (1,0) [0|1] ""  EBCM_OBD_HS,BCP_HS,EBCM_HS,TCM_HS
 SG_ PropSysOffTmeM : 4|1@0+ (1,0) [0|1] ""  EBCM_OBD_HS,BCP_HS,EBCM_HS,TCM_HS
 SG_ PropSysOffTme : 3|12@0+ (0.5,0) [0|2047.5] "min"  EBCM_OBD_HS,BCP_HS,EBCM_HS,TCM_HS

BO_ 479 PPEI_Propulsion_Gen_Stat_1_HS: 4 ECM_HS
 SG_ EngAutoStpNotProb : 2|1@0+ (1,0) [0|1] ""  TCM_HS,BCM_HS,ECM_HS
 SG_ EASSI_UnsdRsrvd2 : 8|1@0+ (1,0) [0|1] ""  EBCM_OBD_HS,TCCM_HS,EBCM_HS,TCM_HS,BCM_HS,ECM_HS
 SG_ EASSI_StlDetd : 10|1@0+ (1,0) [0|1] ""  EBCM_OBD_HS,TCCM_HS,EBCM_HS,TCM_HS,BCM_HS,ECM_HS
 SG_ EASSI_TrqDetd : 11|1@0+ (1,0) [0|1] ""  EBCM_OBD_HS,TCCM_HS,EBCM_HS,TCM_HS,BCM_HS,ECM_HS
 SG_ EASSI_FuelReqOn : 12|1@0+ (1,0) [0|1] ""  EBCM_OBD_HS,TCCM_HS,EBCM_HS,TCM_HS,BCM_HS,ECM_HS
 SG_ EASSI_StrtTyp : 15|3@0+ (1,0) [0|7] ""  EBCM_OBD_HS,TCCM_HS,EBCM_HS,TCM_HS,BCM_HS,ECM_HS
 SG_ EASSI_StrtStpSt : 1|2@0+ (1,0) [0|3] ""  EBCM_OBD_HS,TCCM_HS,EBCM_HS,TCM_HS,BCM_HS,ECM_HS
 SG_ EASSI_TorqDetdIndet : 9|1@0+ (1,0) [0|1] ""  EBCM_OBD_HS,TCCM_HS,EBCM_HS,TCM_HS,BCM_HS,ECM_HS
 SG_ ASIRI_Indication08 : 16|1@0+ (1,0) [0|1] ""  BCM_HS
 SG_ ASIRI_Indication07 : 17|1@0+ (1,0) [0|1] ""  BCM_HS
 SG_ ASIRI_Indication06 : 18|1@0+ (1,0) [0|1] ""  BCM_HS
 SG_ ASIRI_Indication05 : 19|1@0+ (1,0) [0|1] ""  BCM_HS
 SG_ ASIRI_Indication04 : 20|1@0+ (1,0) [0|1] ""  BCM_HS
 SG_ ASIRI_Indication03 : 21|1@0+ (1,0) [0|1] ""  BCM_HS
 SG_ ASIRI_Indication02 : 22|1@0+ (1,0) [0|1] ""  BCM_HS
 SG_ ASIRI_Indication01 : 23|1@0+ (1,0) [0|1] ""  BCM_HS
 SG_ PTWrmgWtToShftIO : 5|1@0+ (1,0) [0|1] ""  BCM_HS
 SG_ PrplsnSysAtv : 7|1@0+ (1,0) [0|1] ""  ICCM_OBD_HS,EBCM_OBD_HS,ICCM_HS,EPB_HS,TCCM_HS,EBCM_HS,TCM_HS,ECM_HS
 SG_ PTShftLvrLckRqd : 6|1@0+ (1,0) [0|1] ""  BCM_HS

BO_ 211 PPEI_Hybrid_General_Status_3_HS: 2 ECM_HS
 SG_ ActAxleTrqV : 7|1@0+ (1,0) [0|1] ""  CGM_HS,ICCM_OBD_HS,EBCM_OBD_HS,EPS_HS,BCP_HS,ICCM_HS,TCCM_HS,EBCM_HS,TCM_HS,ECM_HS
 SG_ ActAxleTrq : 6|15@0+ (2,-22534) [-22534|43000] "Nm"  CGM_HS,ICCM_OBD_HS,EBCM_OBD_HS,EPS_HS,BCP_HS,ICCM_HS,TCCM_HS,EBCM_HS,TCM_HS,ECM_HS

BO_ 1020 PPEI_Engine_Environmental_Status: 8 ECM_HS
 SG_ OtsAirTmpEmsnsRelV : 47|1@0+ (1,0) [0|1] ""  CGM_HS
 SG_ OtsAirTmpEmsnsRel : 55|8@0+ (0.5,-40) [-40|87.5] "deg C"  CGM_HS
 SG_ OATEmsnsRelCrValV : 46|1@0+ (1,0) [0|1] ""  CGM_HS
 SG_ OATEmsnsRelCrValM : 45|1@0+ (1,0) [0|1] ""  CGM_HS
 SG_ OATEmsnsRelCrVal : 63|8@0+ (0.5,-40) [-40|87.5] "deg C"  CGM_HS
 SG_ CatlystOutGasTempEstV : 2|1@0+ (1,0) [0|1] ""  CGM_HS
 SG_ CatlystOutGasTempEst : 15|8@0+ (5,-40) [-40|1235] "deg C"  CGM_HS
 SG_ OtsAirTmpCrValMsk : 3|1@0+ (1,0) [0|1] ""  EPB_HS,TCM_HS,BCM_HS
 SG_ OtsAirTmpV : 5|1@0+ (1,0) [0|1] ""  CGM_HS,EPB_HS,BCM_HS
 SG_ OtsAirTmpCrValV : 4|1@0+ (1,0) [0|1] ""  EPB_HS,TCM_HS,BCM_HS
 SG_ OtsAirTmpCrVal : 39|8@0+ (0.5,-40) [-40|87.5] "deg C"  EPB_HS,TCM_HS,BCM_HS
 SG_ OtsAirTmp : 31|8@0+ (0.5,-40) [-40|87.5] "deg C"  CGM_HS,EPB_HS,BCM_HS
 SG_ EngInltSpcfcHmdtyV : 7|1@0+ (1,0) [0|1] ""  CGM_HS,EBCM_OBD_HS,EBCM_HS,BCM_HS
 SG_ EngInltSpcfcHmdtyM : 6|1@0+ (1,0) [0|1] ""  CGM_HS,EBCM_OBD_HS,EBCM_HS,BCM_HS
 SG_ EngInltSpcfcHmdty : 23|8@0+ (0.0196078,0) [0|4.999989] "% water"  CGM_HS,EBCM_OBD_HS,EBCM_HS,BCM_HS

BO_TX_BU_ 197 : EBCM_OBD_HS,EBCM_HS;
BO_TX_BU_ 193 : EBCM_OBD_HS,EBCM_HS;
BO_TX_BU_ 455 : EBCM_OBD_HS,EBCM_HS;
BO_TX_BU_ 761 : EBCM_OBD_HS,EBCM_HS;
BO_TX_BU_ 489 : EBCM_OBD_HS,EBCM_HS;
BO_TX_BU_ 381 : EBCM_OBD_HS,EBCM_HS;
BO_TX_BU_ 479 : BCP_HS,ECM_HS;
CM_ SG_ 1249 VehIdNmDig10_17 "Desc: 8 ASCII Characters";
CM_ SG_ 481 AuxHtrRq "Auxiliary Heater shall be used to denote a heater function that uses some kind of power, electrical or mechanical,  that was generated by the engine.";
CM_ SG_ 481 AuxHtrAtv "Auxiliary Heater shall be used to denote a heater function that uses some kind of power, electrical or mechanical,  that was generated by the engine.";
CM_ BO_ 489 "Changed for PPEI 3.6";
CM_ SG_ 381 BrkSysRedBrkTlltlReq "Added acc to Björn 0410";
CM_ SG_ 241 BrkPdlModTrvlV "Indicates that the brake pedal position has passed a threshold for brake torque management and some 2 channel Vehicle Dynamics Control systems.";
CM_ SG_ 241 BrkPdlModTrvl "Indicates that the brake pedal position has passed a threshold for brake torque management and some 2 channel Vehicle Dynamics Control systems.";
CM_ SG_ 1263 BatSOH "State of Health = the aging state of the Battery";
BA_DEF_ SG_  "VNSigSLHSSharedDiagnostic" ENUM  "No","Yes";
BA_DEF_ SG_  "VNSigSLHS_VNReq" ENUM  "No","Yes";
BA_DEF_ SG_  "GenSigSendOnInit" ENUM  "Not Initialized","Application","Handler";
BA_DEF_ SG_  "GenSigSendType" ENUM  "not used","not used","not used","not used","not used","not used","not used","NoSigSendType","not used","not used","OnAnyChange","OnChangeIfActive","OnDelta";
BA_DEF_ SG_  "GenSigDeltaValue" INT 0 0;
BA_DEF_ SG_  "VNSigAllNodes" ENUM  "No","Yes";
BA_DEF_ SG_  "SignalType" STRING ;
BA_DEF_ SG_  "PacketOrder" INT 0 65535;
BA_DEF_ SG_  "SignalLongName" STRING ;
BA_DEF_ SG_  "GenSigStartValue" INT 0 65535;
BA_DEF_ SG_  "TxSignalSendOnInit" ENUM  "Not Initialized","Application","Handler";
BA_DEF_ BO_  "GenMsgILSupport" ENUM  "No","Yes";
BA_DEF_ BO_  "AppGenMsgCycleTime" INT 0 0;
BA_DEF_ BO_  "TpApplType" STRING ;
BA_DEF_ BO_  "Prio" INT 0 7;
BA_DEF_ BO_  "MessageSubnet" ENUM  "LS","MS","HS","CE","PE","HV","FO","S1","HE","LE","HE2","vector_leerstring";
BA_DEF_ BO_  "DiagState" ENUM  "No","Yes";
BA_DEF_ BO_  "GenMsgIlSupport" ENUM  "No","Yes";
BA_DEF_ BO_  "GenMsgStartDelayTime" INT 0 100000;
BA_DEF_ BO_  "GenMsgDelayTime" INT 0 100000;
BA_DEF_ BO_  "GenMsgCycleTime" INT 0 100000;
BA_DEF_ BO_  "GenMsgSendType" ENUM  "cyclicX","spontanX","cyclicIfActiveX","spontanWithDelay","cyclicAndSpontanX","cyclicAndSpontanWithDelay","spontanWithRepitition","cyclicIfActiveAndSpontanWD";
BA_DEF_ BO_  "DiagResponse" ENUM  "No","Yes";
BA_DEF_ BO_  "DiagRequest" ENUM  "No","Yes";
BA_DEF_ BO_  "NmMessage" ENUM  "No","Yes";
BA_DEF_REL_ BU_SG_REL_  "GenSigSuprvResp" ENUM  "None","Notify App","Substitute Default";
BA_DEF_REL_ BU_SG_REL_  "GenSigSuprvRespSubValue" INT 0 65535;
BA_DEF_REL_ BU_SG_REL_  "GenSigRxStartValue" STRING ;
BA_DEF_REL_ BU_SG_REL_  "GenSigVDAFailResp" ENUM  "No","Yes";
BA_DEF_REL_ BU_SG_REL_  "GenSigVDAFailComment" STRING ;
BA_DEF_REL_ BU_SG_REL_  "GenSigVBitRespComment" STRING ;
BA_DEF_REL_ BU_SG_REL_  "GenSigVBitResp" ENUM  "No","Yes";
BA_DEF_REL_ BU_SG_REL_  "GenSigSuprvRespComment" STRING ;
BA_DEF_REL_ BU_SG_REL_  "GenSigTimeoutMsg" HEX 0 268435455;
BA_DEF_REL_ BU_SG_REL_  "GenSigTimeoutTime" INT 0 5000;
BA_DEF_DEF_  "VNSigSLHSSharedDiagnostic" "No";
BA_DEF_DEF_  "VNSigSLHS_VNReq" "No";
BA_DEF_DEF_  "GenSigSendOnInit" "Not Initialized";
BA_DEF_DEF_  "GenSigSendType" "NoSigSendType";
BA_DEF_DEF_  "GenSigDeltaValue" 0;
BA_DEF_DEF_  "VNSigAllNodes" "No";
BA_DEF_DEF_  "SignalType" "";
BA_DEF_DEF_  "PacketOrder" 0;
BA_DEF_DEF_  "SignalLongName" "";
BA_DEF_DEF_  "GenSigStartValue" 0;
BA_DEF_DEF_  "TxSignalSendOnInit" "Not Initialized";
BA_DEF_DEF_  "GenMsgILSupport" "Yes";
BA_DEF_DEF_  "AppGenMsgCycleTime" 0;
BA_DEF_DEF_  "TpApplType" "";
BA_DEF_DEF_  "Prio" 0;
BA_DEF_DEF_  "MessageSubnet" "LS";
BA_DEF_DEF_  "DiagState" "No";
BA_DEF_DEF_  "GenMsgIlSupport" "Yes";
BA_DEF_DEF_  "GenMsgStartDelayTime" 0;
BA_DEF_DEF_  "GenMsgDelayTime" 0;
BA_DEF_DEF_  "GenMsgCycleTime" 0;
BA_DEF_DEF_  "GenMsgSendType" "spontanX";
BA_DEF_DEF_  "DiagResponse" "No";
BA_DEF_DEF_  "DiagRequest" "No";
BA_DEF_DEF_  "NmMessage" "No";
BA_DEF_DEF_REL_ "GenSigSuprvResp" "None";
BA_DEF_DEF_REL_ "GenSigSuprvRespSubValue" 0;
BA_DEF_DEF_REL_ "GenSigRxStartValue" "";
BA_DEF_DEF_REL_ "GenSigVDAFailResp" "No";
BA_DEF_DEF_REL_ "GenSigVDAFailComment" "";
BA_DEF_DEF_REL_ "GenSigVBitRespComment" "";
BA_DEF_DEF_REL_ "GenSigVBitResp" "No";
BA_DEF_DEF_REL_ "GenSigSuprvRespComment" "";
BA_DEF_DEF_REL_ "GenSigTimeoutMsg" 0;
BA_DEF_DEF_REL_ "GenSigTimeoutTime" 0;
BA_ "GenMsgSendType" BO_ 197 0;
BA_ "GenMsgCycleTime" BO_ 197 10;
BA_ "MessageSubnet" BO_ 197 2;
BA_ "GenMsgSendType" BO_ 1009 0;
BA_ "GenMsgCycleTime" BO_ 1009 250;
BA_ "GenMsgStartDelayTime" BO_ 1009 10;
BA_ "MessageSubnet" BO_ 1009 2;
BA_ "GenMsgSendType" BO_ 1257 0;
BA_ "GenMsgCycleTime" BO_ 1257 1000;
BA_ "GenMsgStartDelayTime" BO_ 1257 10;
BA_ "MessageSubnet" BO_ 1257 2;
BA_ "GenMsgSendType" BO_ 505 0;
BA_ "GenMsgCycleTime" BO_ 505 30;
BA_ "GenMsgStartDelayTime" BO_ 505 20;
BA_ "MessageSubnet" BO_ 505 2;
BA_ "GenMsgSendType" BO_ 497 0;
BA_ "GenMsgCycleTime" BO_ 497 100;
BA_ "GenMsgDelayTime" BO_ 497 30;
BA_ "GenMsgStartDelayTime" BO_ 497 10;
BA_ "MessageSubnet" BO_ 497 2;
BA_ "GenMsgSendType" BO_ 969 0;
BA_ "GenMsgCycleTime" BO_ 969 100;
BA_ "GenMsgStartDelayTime" BO_ 969 20;
BA_ "MessageSubnet" BO_ 969 2;
BA_ "GenMsgSendType" BO_ 1249 0;
BA_ "GenMsgCycleTime" BO_ 1249 1000;
BA_ "GenMsgStartDelayTime" BO_ 1249 60;
BA_ "MessageSubnet" BO_ 1249 2;
BA_ "GenMsgSendType" BO_ 193 0;
BA_ "GenMsgCycleTime" BO_ 193 10;
BA_ "MessageSubnet" BO_ 193 2;
BA_ "GenMsgSendType" BO_ 481 0;
BA_ "GenMsgCycleTime" BO_ 481 30;
BA_ "GenMsgStartDelayTime" BO_ 481 10;
BA_ "MessageSubnet" BO_ 481 2;
BA_ "GenMsgSendType" BO_ 455 0;
BA_ "GenMsgCycleTime" BO_ 455 20;
BA_ "MessageSubnet" BO_ 455 2;
BA_ "GenMsgSendType" BO_ 761 0;
BA_ "GenMsgCycleTime" BO_ 761 50;
BA_ "MessageSubnet" BO_ 761 2;
BA_ "GenMsgSendType" BO_ 489 0;
BA_ "GenMsgCycleTime" BO_ 489 20;
BA_ "MessageSubnet" BO_ 489 2;
BA_ "GenMsgSendType" BO_ 381 0;
BA_ "GenMsgCycleTime" BO_ 381 100;
BA_ "MessageSubnet" BO_ 381 2;
BA_ "GenMsgSendType" BO_ 241 0;
BA_ "GenMsgCycleTime" BO_ 241 10;
BA_ "MessageSubnet" BO_ 241 2;
BA_ "GenMsgSendType" BO_ 1271 0;
BA_ "GenMsgCycleTime" BO_ 1271 5000;
BA_ "MessageSubnet" BO_ 1271 2;
BA_ "GenMsgSendType" BO_ 1263 0;
BA_ "GenMsgCycleTime" BO_ 1263 1000;
BA_ "MessageSubnet" BO_ 1263 2;
BA_ "GenMsgSendType" BO_ 1261 0;
BA_ "GenMsgCycleTime" BO_ 1261 1000;
BA_ "MessageSubnet" BO_ 1261 2;
BA_ "GenMsgSendType" BO_ 1259 0;
BA_ "GenMsgCycleTime" BO_ 1259 500;
BA_ "MessageSubnet" BO_ 1259 2;
BA_ "GenMsgSendType" BO_ 426 0;
BA_ "GenMsgCycleTime" BO_ 426 25;
BA_ "MessageSubnet" BO_ 426 2;
BA_ "GenMsgSendType" BO_ 1231 0;
BA_ "GenMsgCycleTime" BO_ 1231 1000;
BA_ "MessageSubnet" BO_ 1231 2;
BA_ "GenMsgSendType" BO_ 723 0;
BA_ "GenMsgCycleTime" BO_ 723 50;
BA_ "MessageSubnet" BO_ 723 2;
BA_ "GenMsgSendType" BO_ 405 0;
BA_ "GenMsgCycleTime" BO_ 405 12;
BA_ "MessageSubnet" BO_ 405 2;
BA_ "GenMsgSendType" BO_ 419 0;
BA_ "GenMsgCycleTime" BO_ 419 25;
BA_ "MessageSubnet" BO_ 419 2;
BA_ "GenMsgSendType" BO_ 1223 0;
BA_ "GenMsgCycleTime" BO_ 1223 500;
BA_ "MessageSubnet" BO_ 1223 2;
BA_ "GenMsgSendType" BO_ 479 0;
BA_ "GenMsgCycleTime" BO_ 479 25;
BA_ "MessageSubnet" BO_ 479 2;
BA_ "GenMsgSendType" BO_ 211 0;
BA_ "GenMsgCycleTime" BO_ 211 12;
BA_ "MessageSubnet" BO_ 211 2;
BA_ "GenMsgSendType" BO_ 1020 0;
BA_ "GenMsgCycleTime" BO_ 1020 250;
BA_ "MessageSubnet" BO_ 1020 2;
BA_ "SignalLongName" SG_ 197 WRSLNDWhlDisTpRC "Wheel Rotational Status Left Non Driven : Wheel Distance Timestamp Rollover Counter";
BA_ "PacketOrder" SG_ 197 WRSLNDWhlDisTpRC 1;
BA_ "SignalType" SG_ 197 WRSLNDWhlDisTpRC "UNM";
BA_ "VNSigAllNodes" SG_ 197 WRSLNDWhlDisTpRC 1;
BA_ "SignalLongName" SG_ 197 WRSLNDWhlRotStRst "Wheel Rotational Status Left Non Driven : Wheel Rotational Status Reset Occurred";
BA_ "PacketOrder" SG_ 197 WRSLNDWhlRotStRst 3;
BA_ "SignalType" SG_ 197 WRSLNDWhlRotStRst "BLN";
BA_ "VNSigAllNodes" SG_ 197 WRSLNDWhlRotStRst 1;
BA_ "SignalLongName" SG_ 197 WRSLNDWhlDistVal "Wheel Rotational Status Left Non Driven : Wheel Distance Validity";
BA_ "PacketOrder" SG_ 197 WRSLNDWhlDistVal 4;
BA_ "SignalType" SG_ 197 WRSLNDWhlDistVal "ENM";
BA_ "VNSigAllNodes" SG_ 197 WRSLNDWhlDistVal 1;
BA_ "SignalLongName" SG_ 197 WRSLNDWhlDistTstm "Wheel Rotational Status Left Non Driven : Wheel Distance Timestamp";
BA_ "PacketOrder" SG_ 197 WRSLNDWhlDistTstm 6;
BA_ "SignalType" SG_ 197 WRSLNDWhlDistTstm "UNM";
BA_ "VNSigAllNodes" SG_ 197 WRSLNDWhlDistTstm 1;
BA_ "SignalLongName" SG_ 197 WRSLNDWhlDistPCntr "Wheel Rotational Status Left Non Driven : Wheel Distance Pulse Counter";
BA_ "PacketOrder" SG_ 197 WRSLNDWhlDistPCntr 5;
BA_ "SignalType" SG_ 197 WRSLNDWhlDistPCntr "UNM";
BA_ "VNSigAllNodes" SG_ 197 WRSLNDWhlDistPCntr 1;
BA_ "SignalLongName" SG_ 197 WRSLNDSeqNum "Wheel Rotational Status Left Non Driven : Sequence Number";
BA_ "PacketOrder" SG_ 197 WRSLNDSeqNum 2;
BA_ "SignalType" SG_ 197 WRSLNDSeqNum "UNM";
BA_ "VNSigAllNodes" SG_ 197 WRSLNDSeqNum 1;
BA_ "SignalLongName" SG_ 197 WRSRNDWhlDisTpRC "Wheel Rotational Status Right Non Driven : Wheel Distance Timestamp Rollover Counter";
BA_ "PacketOrder" SG_ 197 WRSRNDWhlDisTpRC 1;
BA_ "SignalType" SG_ 197 WRSRNDWhlDisTpRC "UNM";
BA_ "VNSigAllNodes" SG_ 197 WRSRNDWhlDisTpRC 1;
BA_ "SignalLongName" SG_ 197 WRSRNDWhlRotStRst "Wheel Rotational Status Right Non Driven : Wheel Rotational Status Reset Occurred";
BA_ "PacketOrder" SG_ 197 WRSRNDWhlRotStRst 3;
BA_ "SignalType" SG_ 197 WRSRNDWhlRotStRst "BLN";
BA_ "VNSigAllNodes" SG_ 197 WRSRNDWhlRotStRst 1;
BA_ "SignalLongName" SG_ 197 WRSRNDWhlDistVal "Wheel Rotational Status Right Non Driven : Wheel Distance Validity";
BA_ "PacketOrder" SG_ 197 WRSRNDWhlDistVal 4;
BA_ "SignalType" SG_ 197 WRSRNDWhlDistVal "ENM";
BA_ "VNSigAllNodes" SG_ 197 WRSRNDWhlDistVal 1;
BA_ "SignalLongName" SG_ 197 WRSRNDWhlDistTstm "Wheel Rotational Status Right Non Driven : Wheel Distance Timestamp";
BA_ "PacketOrder" SG_ 197 WRSRNDWhlDistTstm 6;
BA_ "SignalType" SG_ 197 WRSRNDWhlDistTstm "UNM";
BA_ "VNSigAllNodes" SG_ 197 WRSRNDWhlDistTstm 1;
BA_ "SignalLongName" SG_ 197 WRSRNDWhlDistPCntr "Wheel Rotational Status Right Non Driven : Wheel Distance Pulse Counter";
BA_ "PacketOrder" SG_ 197 WRSRNDWhlDistPCntr 5;
BA_ "SignalType" SG_ 197 WRSRNDWhlDistPCntr "UNM";
BA_ "VNSigAllNodes" SG_ 197 WRSRNDWhlDistPCntr 1;
BA_ "SignalLongName" SG_ 197 WRSRNDSeqNum "Wheel Rotational Status Right Non Driven : Sequence Number";
BA_ "PacketOrder" SG_ 197 WRSRNDSeqNum 2;
BA_ "SignalType" SG_ 197 WRSRNDSeqNum "UNM";
BA_ "VNSigAllNodes" SG_ 197 WRSRNDSeqNum 1;
BA_ "GenSigStartValue" SG_ 1009 EngOffTmVDA 1;
BA_ "SignalLongName" SG_ 1009 EngOffTmVDA "Engine Off Time Virtual Device Availability";
BA_ "SignalType" SG_ 1009 EngOffTmVDA "ENM";
BA_ "VNSigAllNodes" SG_ 1009 EngOffTmVDA 1;
BA_ "SignalLongName" SG_ 1009 IntDimDspLvl "Interior Dimming Display Level";
BA_ "SignalType" SG_ 1009 IntDimDspLvl "UNM";
BA_ "VNSigAllNodes" SG_ 1009 IntDimDspLvl 1;
BA_ "GenSigDeltaValue" SG_ 1009 IntDimDspLvl 1;
BA_ "GenSigSendType" SG_ 1009 IntDimDspLvl 12;
BA_ "GenSigSendOnInit" SG_ 1009 IntDimDspLvl 2;
BA_ "SignalLongName" SG_ 1009 EngOffTmExtRngV "Engine Off Time Extended Range Validity";
BA_ "SignalType" SG_ 1009 EngOffTmExtRngV "ENM";
BA_ "VNSigAllNodes" SG_ 1009 EngOffTmExtRngV 1;
BA_ "GenSigSendType" SG_ 1009 EngOffTmExtRngV 10;
BA_ "SignalLongName" SG_ 1009 EngOffTmExtRng "Engine Off Time Extended Range";
BA_ "SignalType" SG_ 1009 EngOffTmExtRng "UNM";
BA_ "VNSigAllNodes" SG_ 1009 EngOffTmExtRng 1;
BA_ "GenSigDeltaValue" SG_ 1009 EngOffTmExtRng 1;
BA_ "GenSigSendType" SG_ 1009 EngOffTmExtRng 12;
BA_ "GenSigSendOnInit" SG_ 1009 EngOffTmExtRng 2;
BA_ "SignalLongName" SG_ 1009 RstrctdPTOpModeReqd "Restricted Powertrain Operation Mode Requested";
BA_ "SignalType" SG_ 1009 RstrctdPTOpModeReqd "BLN";
BA_ "VNSigAllNodes" SG_ 1009 RstrctdPTOpModeReqd 1;
BA_ "SignalLongName" SG_ 1009 ClmtCtrlHtrEngRunRq "Climate Control Heater Engine Run Request";
BA_ "SignalType" SG_ 1009 ClmtCtrlHtrEngRunRq "ENM";
BA_ "VNSigAllNodes" SG_ 1009 ClmtCtrlHtrEngRunRq 1;
BA_ "GenSigSendType" SG_ 1009 ClmtCtrlHtrEngRunRq 10;
BA_ "SignalLongName" SG_ 1009 OtsAirTmpCrValMsk "Outside Air Temperature Corrected Value Mask";
BA_ "SignalType" SG_ 1009 OtsAirTmpCrValMsk "ENM";
BA_ "VNSigAllNodes" SG_ 1009 OtsAirTmpCrValMsk 1;
BA_ "GenSigSendType" SG_ 1009 OtsAirTmpCrValMsk 10;
BA_ "SignalLongName" SG_ 1009 ACCmEngRunReq "Air Conditioning Compressor Engine Run Request";
BA_ "SignalType" SG_ 1009 ACCmEngRunReq "ENM";
BA_ "VNSigAllNodes" SG_ 1009 ACCmEngRunReq 1;
BA_ "GenSigSendType" SG_ 1009 ACCmEngRunReq 10;
BA_ "GenSigStartValue" SG_ 1009 OutAirTempVDA 1;
BA_ "SignalLongName" SG_ 1009 OutAirTempVDA "Outside Air Temperature Virtual Device Availability";
BA_ "SignalType" SG_ 1009 OutAirTempVDA "ENM";
BA_ "VNSigAllNodes" SG_ 1009 OutAirTempVDA 1;
BA_ "SignalLongName" SG_ 1009 OtsAirTmpCrValV "Outside Air Temperature Corrected Value Validity";
BA_ "SignalType" SG_ 1009 OtsAirTmpCrValV "ENM";
BA_ "VNSigAllNodes" SG_ 1009 OtsAirTmpCrValV 1;
BA_ "GenSigSendType" SG_ 1009 OtsAirTmpCrValV 10;
BA_ "SignalLongName" SG_ 1009 OtsAirTmpCrVal "Outside Air Temperature Corrected Value";
BA_ "SignalType" SG_ 1009 OtsAirTmpCrVal "UNM";
BA_ "VNSigAllNodes" SG_ 1009 OtsAirTmpCrVal 1;
BA_ "GenSigDeltaValue" SG_ 1009 OtsAirTmpCrVal 1;
BA_ "GenSigSendType" SG_ 1009 OtsAirTmpCrVal 12;
BA_ "GenSigSendOnInit" SG_ 1009 OtsAirTmpCrVal 1;
BA_ "SignalLongName" SG_ 1009 ClntCircPmpRq "Coolant Circulation Pump Request";
BA_ "SignalType" SG_ 1009 ClntCircPmpRq "ENM";
BA_ "VNSigAllNodes" SG_ 1009 ClntCircPmpRq 1;
BA_ "GenSigSendType" SG_ 1009 ClntCircPmpRq 10;
BA_ "GenSigSendOnInit" SG_ 1009 ClntCircPmpRq 2;
BA_ "SignalLongName" SG_ 1009 PF_MinIdlBstLvlReq "Platform Minimum Idle Boost Level Request";
BA_ "SignalType" SG_ 1009 PF_MinIdlBstLvlReq "ENM";
BA_ "VNSigAllNodes" SG_ 1009 PF_MinIdlBstLvlReq 1;
BA_ "SignalLongName" SG_ 1009 GenRgSPDtyCycRq "Generator Regulator Setpoint Duty Cycle Request";
BA_ "SignalType" SG_ 1009 GenRgSPDtyCycRq "UNM";
BA_ "VNSigAllNodes" SG_ 1009 GenRgSPDtyCycRq 1;
BA_ "SignalLongName" SG_ 1009 VehTopSpdLmtReq "Vehicle Top Speed Limit Request";
BA_ "SignalType" SG_ 1009 VehTopSpdLmtReq "UNM";
BA_ "VNSigAllNodes" SG_ 1009 VehTopSpdLmtReq 1;
BA_ "SignalLongName" SG_ 1257 ElpsdTimeCntRstOcc "Elapsed Time Count Reset Occurred";
BA_ "SignalType" SG_ 1257 ElpsdTimeCntRstOcc "BLN";
BA_ "VNSigAllNodes" SG_ 1257 ElpsdTimeCntRstOcc 1;
BA_ "GenSigSendType" SG_ 1257 ElpsdTimeCntRstOcc 10;
BA_ "SignalLongName" SG_ 1257 EngPrfID "Engine Performance Identifier";
BA_ "SignalType" SG_ 1257 EngPrfID "UNM";
BA_ "VNSigAllNodes" SG_ 1257 EngPrfID 1;
BA_ "SignalLongName" SG_ 1257 ElpsdTimeCnt "Elapsed Time Count";
BA_ "SignalType" SG_ 1257 ElpsdTimeCnt "UNM";
BA_ "VNSigAllNodes" SG_ 1257 ElpsdTimeCnt 1;
BA_ "GenSigDeltaValue" SG_ 1257 ElpsdTimeCnt 1;
BA_ "GenSigSendType" SG_ 1257 ElpsdTimeCnt 12;
BA_ "SignalLongName" SG_ 1257 VSESysPrs "Vehicle Stability Enhancement System Present";
BA_ "SignalType" SG_ 1257 VSESysPrs "BLN";
BA_ "VNSigAllNodes" SG_ 1257 VSESysPrs 1;
BA_ "SignalLongName" SG_ 1257 ABSPr "Antilock Brake System Present";
BA_ "SignalType" SG_ 1257 ABSPr "BLN";
BA_ "VNSigAllNodes" SG_ 1257 ABSPr 1;
BA_ "SignalLongName" SG_ 1257 TCSysPr "Traction Control System Present";
BA_ "SignalType" SG_ 1257 TCSysPr "BLN";
BA_ "VNSigAllNodes" SG_ 1257 TCSysPr 1;
BA_ "SignalLongName" SG_ 1257 VehSpdCntlSystmType "Vehicle Speed Control System Type";
BA_ "SignalType" SG_ 1257 VehSpdCntlSystmType "ENM";
BA_ "VNSigAllNodes" SG_ 1257 VehSpdCntlSystmType 1;
BA_ "SignalLongName" SG_ 1257 PltfrmEngSpdCmdSysTp "Platform Engine Speed Command System Type";
BA_ "SignalType" SG_ 1257 PltfrmEngSpdCmdSysTp "ENM";
BA_ "VNSigAllNodes" SG_ 1257 PltfrmEngSpdCmdSysTp 1;
BA_ "SignalLongName" SG_ 505 AllNodesVNA_1F9 "All Nodes Virtual Network Activation";
BA_ "SignalType" SG_ 505 AllNodesVNA_1F9 "ENM";
BA_ "VNSigAllNodes" SG_ 505 AllNodesVNA_1F9 1;
BA_ "VNSigSLHS_VNReq" SG_ 505 AllNodesVNA_1F9 1;
BA_ "SignalLongName" SG_ 505 PTOVehTopSpdLimVal "Power Take Off Vehicle Top Speed Limit Value";
BA_ "SignalType" SG_ 505 PTOVehTopSpdLimVal "UNM";
BA_ "VNSigAllNodes" SG_ 505 PTOVehTopSpdLimVal 1;
BA_ "SignalLongName" SG_ 505 PTORmtEngStrtReq "Power Take Off Remote Engine Start Request";
BA_ "SignalType" SG_ 505 PTORmtEngStrtReq "ENM";
BA_ "VNSigAllNodes" SG_ 505 PTORmtEngStrtReq 1;
BA_ "SignalLongName" SG_ 505 PTOTGRReqdGear "Power Take Off Transmission Gear Request : Requested Gear";
BA_ "PacketOrder" SG_ 505 PTOTGRReqdGear 2;
BA_ "SignalType" SG_ 505 PTOTGRReqdGear "ENM";
BA_ "VNSigAllNodes" SG_ 505 PTOTGRReqdGear 1;
BA_ "SignalLongName" SG_ 505 PTOTGRReqType "Power Take Off Transmission Gear Request : Request Type";
BA_ "PacketOrder" SG_ 505 PTOTGRReqType 1;
BA_ "SignalType" SG_ 505 PTOTGRReqType "ENM";
BA_ "VNSigAllNodes" SG_ 505 PTOTGRReqType 1;
BA_ "SignalLongName" SG_ 505 TrnsPTOCltchRelRqd "Transmission Power Take Off Clutch state0800 Requested";
BA_ "SignalType" SG_ 505 TrnsPTOCltchRelRqd "BLN";
BA_ "VNSigAllNodes" SG_ 505 TrnsPTOCltchRelRqd 1;
BA_ "SignalLongName" SG_ 505 AccPdlPwrTkOffOvrAct "Accelerator Pedal Power Take Off Override Active";
BA_ "SignalType" SG_ 505 AccPdlPwrTkOffOvrAct "BLN";
BA_ "VNSigAllNodes" SG_ 505 AccPdlPwrTkOffOvrAct 1;
BA_ "SignalLongName" SG_ 505 FstIdlMdAct "Fast Idle Mode Active";
BA_ "SignalType" SG_ 505 FstIdlMdAct "BLN";
BA_ "VNSigAllNodes" SG_ 505 FstIdlMdAct 1;
BA_ "GenSigSendType" SG_ 505 FstIdlMdAct 10;
BA_ "SignalLongName" SG_ 505 PTOMdAct "Power Take Off Mode Active";
BA_ "SignalType" SG_ 505 PTOMdAct "BLN";
BA_ "VNSigAllNodes" SG_ 505 PTOMdAct 1;
BA_ "SignalLongName" SG_ 505 PTOEngTrqLmtRchd "Power Take Off Engine Torque Limit Requested";
BA_ "SignalType" SG_ 505 PTOEngTrqLmtRchd "BLN";
BA_ "VNSigAllNodes" SG_ 505 PTOEngTrqLmtRchd 1;
BA_ "SignalLongName" SG_ 505 PTOEngTrqLmtValER "Power Take Off Engine Torque Limit Value Extended Range";
BA_ "SignalType" SG_ 505 PTOEngTrqLmtValER "UNM";
BA_ "VNSigAllNodes" SG_ 505 PTOEngTrqLmtValER 1;
BA_ "SignalLongName" SG_ 505 PltfrmEngSpdCmdMdAct "Platform Engine Speed Command : Platform Engine Speed Command Mode Active";
BA_ "PacketOrder" SG_ 505 PltfrmEngSpdCmdMdAct 1;
BA_ "SignalType" SG_ 505 PltfrmEngSpdCmdMdAct "BLN";
BA_ "VNSigAllNodes" SG_ 505 PltfrmEngSpdCmdMdAct 1;
BA_ "SignalLongName" SG_ 505 PltfrmEngSpdReq "Platform Engine Speed Command : Platform Engine Speed Request";
BA_ "PacketOrder" SG_ 505 PltfrmEngSpdReq 2;
BA_ "SignalType" SG_ 505 PltfrmEngSpdReq "UNM";
BA_ "VNSigAllNodes" SG_ 505 PltfrmEngSpdReq 1;
BA_ "SignalLongName" SG_ 505 PFESpdCmdOnSwAct "Platform Engine Speed Command On Switch Active";
BA_ "SignalType" SG_ 505 PFESpdCmdOnSwAct "BLN";
BA_ "VNSigAllNodes" SG_ 505 PFESpdCmdOnSwAct 1;
BA_ "SignalLongName" SG_ 505 PFESpdCmdDeSwAct "Platform Engine Speed Command Speed Decrease Switch Active";
BA_ "SignalType" SG_ 505 PFESpdCmdDeSwAct "BLN";
BA_ "VNSigAllNodes" SG_ 505 PFESpdCmdDeSwAct 1;
BA_ "SignalLongName" SG_ 505 PFESpdCmdInSwAct "Platform Engine Speed Command Speed Increase Switch Active";
BA_ "SignalType" SG_ 505 PFESpdCmdInSwAct "BLN";
BA_ "VNSigAllNodes" SG_ 505 PFESpdCmdInSwAct 1;
BA_ "SignalLongName" SG_ 505 PFESpdCmdSwDIntg "Platform Engine Speed Command Switch Data Integrity";
BA_ "SignalType" SG_ 505 PFESpdCmdSwDIntg "ENM";
BA_ "VNSigAllNodes" SG_ 505 PFESpdCmdSwDIntg 1;
BA_ "SignalLongName" SG_ 505 PFEngSpdCmdAlvRlgCnt "Platform Engine Speed Command Alive Rolling Count";
BA_ "SignalType" SG_ 505 PFEngSpdCmdAlvRlgCnt "UNM";
BA_ "VNSigAllNodes" SG_ 505 PFEngSpdCmdAlvRlgCnt 1;
BA_ "SignalLongName" SG_ 505 PltfrmEngSpdCmdProtVal "Platform Engine Speed Command Protection Value";
BA_ "SignalType" SG_ 505 PltfrmEngSpdCmdProtVal "UNM";
BA_ "VNSigAllNodes" SG_ 505 PltfrmEngSpdCmdProtVal 1;
BA_ "SignalLongName" SG_ 505 PTORmtEngShtdwnReqd "Power Take Off Remote Engine Shutdown Requested";
BA_ "SignalType" SG_ 505 PTORmtEngShtdwnReqd "BLN";
BA_ "VNSigAllNodes" SG_ 505 PTORmtEngShtdwnReqd 1;
BA_ "GenSigStartValue" SG_ 497 BkupPwrModeMstrVDA 1;
BA_ "SignalLongName" SG_ 497 BkupPwrModeMstrVDA "Backup Power Mode Master Virtual Device Availability";
BA_ "SignalType" SG_ 497 BkupPwrModeMstrVDA "ENM";
BA_ "VNSigAllNodes" SG_ 497 BkupPwrModeMstrVDA 1;
BA_ "GenSigSendType" SG_ 497 BkupPwrModeMstrVDA 10;
BA_ "GenSigStartValue" SG_ 497 PrkBrkVDA 1;
BA_ "SignalLongName" SG_ 497 PrkBrkVDA "Park Brake Virtual Device Availability";
BA_ "SignalType" SG_ 497 PrkBrkVDA "ENM";
BA_ "VNSigAllNodes" SG_ 497 PrkBrkVDA 1;
BA_ "GenSigSendType" SG_ 497 PrkBrkVDA 10;
BA_ "GenSigStartValue" SG_ 497 PrkBrkVDM 1;
BA_ "SignalLongName" SG_ 497 PrkBrkVDM "Park Brake Virtual Device Mask";
BA_ "SignalType" SG_ 497 PrkBrkVDM "ENM";
BA_ "VNSigAllNodes" SG_ 497 PrkBrkVDM 1;
BA_ "GenSigSendType" SG_ 497 PrkBrkVDM 10;
BA_ "SignalLongName" SG_ 497 BkupPwrModeMstrVDM "Backup Power Mode Master Virtual Device Mask";
BA_ "SignalType" SG_ 497 BkupPwrModeMstrVDM "ENM";
BA_ "VNSigAllNodes" SG_ 497 BkupPwrModeMstrVDM 1;
BA_ "GenSigSendType" SG_ 497 BkupPwrModeMstrVDM 10;
BA_ "SignalLongName" SG_ 497 ACCompSysVDM "Air Conditioning Compressor System Virtual Device Mask";
BA_ "SignalType" SG_ 497 ACCompSysVDM "ENM";
BA_ "VNSigAllNodes" SG_ 497 ACCompSysVDM 1;
BA_ "GenSigSendType" SG_ 497 ACCompSysVDM 10;
BA_ "SignalLongName" SG_ 497 ElvtdIdlCstStReq "Elevated Idle Customization Setting Request";
BA_ "SignalType" SG_ 497 ElvtdIdlCstStReq "ENM";
BA_ "VNSigAllNodes" SG_ 497 ElvtdIdlCstStReq 1;
BA_ "GenSigSendType" SG_ 497 ElvtdIdlCstStReq 10;
BA_ "SignalLongName" SG_ 497 FuelFltLfRstRqd "Fuel Filter Life Reset Requested";
BA_ "SignalType" SG_ 497 FuelFltLfRstRqd "BLN";
BA_ "VNSigAllNodes" SG_ 497 FuelFltLfRstRqd 1;
BA_ "GenSigSendType" SG_ 497 FuelFltLfRstRqd 10;
BA_ "GenSigSendOnInit" SG_ 497 FuelFltLfRstRqd 1;
BA_ "GenSigStartValue" SG_ 497 ACCompSysVDA 1;
BA_ "SignalLongName" SG_ 497 ACCompSysVDA "Air Conditioning Compressor System Virtual Device Availability";
BA_ "SignalType" SG_ 497 ACCompSysVDA "ENM";
BA_ "VNSigAllNodes" SG_ 497 ACCompSysVDA 1;
BA_ "GenSigSendType" SG_ 497 ACCompSysVDA 10;
BA_ "GenSigStartValue" SG_ 497 AirbgVDA 1;
BA_ "SignalLongName" SG_ 497 AirbgVDA "Airbag Virtual Device Availability";
BA_ "SignalType" SG_ 497 AirbgVDA "ENM";
BA_ "VNSigAllNodes" SG_ 497 AirbgVDA 1;
BA_ "GenSigSendType" SG_ 497 AirbgVDA 10;
BA_ "SignalLongName" SG_ 497 SysBkupPwrMdEn "System Backup Power Mode Enabled";
BA_ "SignalType" SG_ 497 SysBkupPwrMdEn "BLN";
BA_ "VNSigAllNodes" SG_ 497 SysBkupPwrMdEn 1;
BA_ "GenSigSendType" SG_ 497 SysBkupPwrMdEn 10;
BA_ "GenSigSendOnInit" SG_ 497 SysBkupPwrMdEn 1;
BA_ "SignalLongName" SG_ 497 SysBkUpPwrMd "System Backup Power Mode";
BA_ "SignalType" SG_ 497 SysBkUpPwrMd "ENM";
BA_ "VNSigAllNodes" SG_ 497 SysBkUpPwrMd 1;
BA_ "GenSigSendType" SG_ 497 SysBkUpPwrMd 10;
BA_ "GenSigSendOnInit" SG_ 497 SysBkUpPwrMd 1;
BA_ "SignalLongName" SG_ 497 SysPwrMd "System Power Mode";
BA_ "SignalType" SG_ 497 SysPwrMd "ENM";
BA_ "VNSigAllNodes" SG_ 497 SysPwrMd 1;
BA_ "GenSigSendType" SG_ 497 SysPwrMd 10;
BA_ "GenSigSendOnInit" SG_ 497 SysPwrMd 2;
BA_ "SignalLongName" SG_ 497 TrStLgMdAtv "Transport Storage Logistic Mode Active";
BA_ "SignalType" SG_ 497 TrStLgMdAtv "BLN";
BA_ "VNSigAllNodes" SG_ 497 TrStLgMdAtv 1;
BA_ "GenSigSendType" SG_ 497 TrStLgMdAtv 10;
BA_ "GenSigSendOnInit" SG_ 497 TrStLgMdAtv 1;
BA_ "SignalLongName" SG_ 497 DispMeasSys "Display Measurement System";
BA_ "SignalType" SG_ 497 DispMeasSys "ENM";
BA_ "VNSigAllNodes" SG_ 497 DispMeasSys 1;
BA_ "GenSigSendType" SG_ 497 DispMeasSys 10;
BA_ "GenSigSendOnInit" SG_ 497 DispMeasSys 1;
BA_ "SignalLongName" SG_ 497 ACCmpsrFldOn "Air Conditioning Compressor Failed On";
BA_ "SignalType" SG_ 497 ACCmpsrFldOn "BLN";
BA_ "VNSigAllNodes" SG_ 497 ACCmpsrFldOn 1;
BA_ "GenSigSendType" SG_ 497 ACCmpsrFldOn 10;
BA_ "SignalLongName" SG_ 497 ACCompModReq "Air Conditioning Compressor Mode Request";
BA_ "SignalType" SG_ 497 ACCompModReq "ENM";
BA_ "VNSigAllNodes" SG_ 497 ACCompModReq 1;
BA_ "GenSigSendType" SG_ 497 ACCompModReq 10;
BA_ "GenSigSendOnInit" SG_ 497 ACCompModReq 2;
BA_ "SignalLongName" SG_ 497 ACCompNormLd "Air Conditioning Compressor Normalized Load";
BA_ "SignalType" SG_ 497 ACCompNormLd "UNM";
BA_ "VNSigAllNodes" SG_ 497 ACCompNormLd 1;
BA_ "GenSigDeltaValue" SG_ 497 ACCompNormLd 1;
BA_ "GenSigSendType" SG_ 497 ACCompNormLd 12;
BA_ "GenSigSendOnInit" SG_ 497 ACCompNormLd 1;
BA_ "SignalLongName" SG_ 497 ACCompNormLdV "Air Conditioning Compressor Normalized Load Validity";
BA_ "SignalType" SG_ 497 ACCompNormLdV "ENM";
BA_ "VNSigAllNodes" SG_ 497 ACCompNormLdV 1;
BA_ "GenSigSendType" SG_ 497 ACCompNormLdV 10;
BA_ "GenSigSendOnInit" SG_ 497 ACCompNormLdV 1;
BA_ "SignalLongName" SG_ 497 PTORSMstrEngShtReq "Power Take Off Remote Start Master Engine Shutdown Requested";
BA_ "SignalType" SG_ 497 PTORSMstrEngShtReq "BLN";
BA_ "VNSigAllNodes" SG_ 497 PTORSMstrEngShtReq 1;
BA_ "GenSigSendType" SG_ 497 PTORSMstrEngShtReq 10;
BA_ "SignalLongName" SG_ 497 EngOilLfRstRq "Engine Oil Life Reset Request";
BA_ "SignalType" SG_ 497 EngOilLfRstRq "BLN";
BA_ "VNSigAllNodes" SG_ 497 EngOilLfRstRq 1;
BA_ "GenSigSendType" SG_ 497 EngOilLfRstRq 10;
BA_ "SignalLongName" SG_ 497 SIRDpl "Airbag Deployed";
BA_ "SignalType" SG_ 497 SIRDpl "BLN";
BA_ "VNSigAllNodes" SG_ 497 SIRDpl 1;
BA_ "GenSigSendType" SG_ 497 SIRDpl 10;
BA_ "GenSigSendOnInit" SG_ 497 SIRDpl 2;
BA_ "SignalLongName" SG_ 497 PTORmStMsEngStRq "Power Take Off Remote Start Master Engine Start Request";
BA_ "SignalType" SG_ 497 PTORmStMsEngStRq "ENM";
BA_ "VNSigAllNodes" SG_ 497 PTORmStMsEngStRq 1;
BA_ "GenSigSendType" SG_ 497 PTORmStMsEngStRq 10;
BA_ "SignalLongName" SG_ 497 RmVehStrRq "Remote Vehicle Start Request";
BA_ "SignalType" SG_ 497 RmVehStrRq "ENM";
BA_ "VNSigAllNodes" SG_ 497 RmVehStrRq 1;
BA_ "GenSigSendType" SG_ 497 RmVehStrRq 10;
BA_ "SignalLongName" SG_ 497 ThrtlPrgrsnReq "Throttle Progression Request";
BA_ "SignalType" SG_ 497 ThrtlPrgrsnReq "ENM";
BA_ "VNSigAllNodes" SG_ 497 ThrtlPrgrsnReq 1;
BA_ "GenSigSendType" SG_ 497 ThrtlPrgrsnReq 10;
BA_ "SignalLongName" SG_ 497 PrkBrkSwAtv "Park Brake Switch Active";
BA_ "SignalType" SG_ 497 PrkBrkSwAtv "BLN";
BA_ "VNSigAllNodes" SG_ 497 PrkBrkSwAtv 1;
BA_ "GenSigSendType" SG_ 497 PrkBrkSwAtv 10;
BA_ "GenSigSendOnInit" SG_ 497 PrkBrkSwAtv 1;
BA_ "SignalLongName" SG_ 497 PMMAccTrmSt "Power Mode Master Accessory Terminal Status";
BA_ "SignalType" SG_ 497 PMMAccTrmSt "ENM";
BA_ "VNSigAllNodes" SG_ 497 PMMAccTrmSt 1;
BA_ "GenSigSendType" SG_ 497 PMMAccTrmSt 10;
BA_ "SignalLongName" SG_ 497 PMMRunCrkTrmSt "Power Mode Master Run Crank Terminal Status";
BA_ "SignalType" SG_ 497 PMMRunCrkTrmSt "ENM";
BA_ "VNSigAllNodes" SG_ 497 PMMRunCrkTrmSt 1;
BA_ "GenSigSendType" SG_ 497 PMMRunCrkTrmSt 10;
BA_ "SignalLongName" SG_ 497 ImmblzrPreRelPswdStat "Immobilizer Pre state0800 Password Status";
BA_ "SignalType" SG_ 497 ImmblzrPreRelPswdStat "ENM";
BA_ "VNSigAllNodes" SG_ 497 ImmblzrPreRelPswdStat 1;
BA_ "GenSigSendType" SG_ 497 ImmblzrPreRelPswdStat 10;
BA_ "SignalLongName" SG_ 497 ImmblzrPreRelPswrd "Immobilizer Pre state0800 Password";
BA_ "SignalType" SG_ 497 ImmblzrPreRelPswrd "UNM";
BA_ "VNSigAllNodes" SG_ 497 ImmblzrPreRelPswrd 1;
BA_ "GenSigDeltaValue" SG_ 497 ImmblzrPreRelPswrd 1;
BA_ "GenSigSendType" SG_ 497 ImmblzrPreRelPswrd 12;
BA_ "SignalLongName" SG_ 969 ImoInf "Immobilizer Information";
BA_ "SignalType" SG_ 969 ImoInf "UNM";
BA_ "VNSigAllNodes" SG_ 969 ImoInf 1;
BA_ "SignalLongName" SG_ 1249 VehIdNmDig10_17 "Vehicle Identification Number Digits 10-17";
BA_ "SignalType" SG_ 1249 VehIdNmDig10_17 "ASC";
BA_ "VNSigAllNodes" SG_ 1249 VehIdNmDig10_17 1;
BA_ "GenSigSendOnInit" SG_ 1249 VehIdNmDig10_17 2;
BA_ "SignalLongName" SG_ 193 WRSLDWhlDisTpRC "Wheel Rotational Status Left Driven : Wheel Distance Timestamp Rollover Counter";
BA_ "PacketOrder" SG_ 193 WRSLDWhlDisTpRC 1;
BA_ "SignalType" SG_ 193 WRSLDWhlDisTpRC "UNM";
BA_ "VNSigAllNodes" SG_ 193 WRSLDWhlDisTpRC 1;
BA_ "SignalLongName" SG_ 193 WRSLDSeqNum "Wheel Rotational Status Left Driven : Sequence Number";
BA_ "PacketOrder" SG_ 193 WRSLDSeqNum 2;
BA_ "SignalType" SG_ 193 WRSLDSeqNum "UNM";
BA_ "VNSigAllNodes" SG_ 193 WRSLDSeqNum 1;
BA_ "SignalLongName" SG_ 193 WRSLDWhlDistVal "Wheel Rotational Status Left Driven : Wheel Distance Validity";
BA_ "PacketOrder" SG_ 193 WRSLDWhlDistVal 4;
BA_ "SignalType" SG_ 193 WRSLDWhlDistVal "ENM";
BA_ "VNSigAllNodes" SG_ 193 WRSLDWhlDistVal 1;
BA_ "SignalLongName" SG_ 193 WRSLDWhlRotStatRst "Wheel Rotational Status Left Driven : Wheel Rotational Status Reset Occurred";
BA_ "PacketOrder" SG_ 193 WRSLDWhlRotStatRst 3;
BA_ "SignalType" SG_ 193 WRSLDWhlRotStatRst "BLN";
BA_ "VNSigAllNodes" SG_ 193 WRSLDWhlRotStatRst 1;
BA_ "SignalLongName" SG_ 193 WRSLDWhlDistTmstm "Wheel Rotational Status Left Driven : Wheel Distance Timestamp";
BA_ "PacketOrder" SG_ 193 WRSLDWhlDistTmstm 6;
BA_ "SignalType" SG_ 193 WRSLDWhlDistTmstm "UNM";
BA_ "VNSigAllNodes" SG_ 193 WRSLDWhlDistTmstm 1;
BA_ "SignalLongName" SG_ 193 WRSLDWhlDistPlsCntr "Wheel Rotational Status Left Driven : Wheel Distance Pulse Counter";
BA_ "PacketOrder" SG_ 193 WRSLDWhlDistPlsCntr 5;
BA_ "SignalType" SG_ 193 WRSLDWhlDistPlsCntr "UNM";
BA_ "VNSigAllNodes" SG_ 193 WRSLDWhlDistPlsCntr 1;
BA_ "SignalLongName" SG_ 193 WRSRDWhlDisTpRC "Wheel Rotational Status Right Driven : Wheel Distance Timestamp Rollover Counter";
BA_ "PacketOrder" SG_ 193 WRSRDWhlDisTpRC 1;
BA_ "SignalType" SG_ 193 WRSRDWhlDisTpRC "UNM";
BA_ "VNSigAllNodes" SG_ 193 WRSRDWhlDisTpRC 1;
BA_ "SignalLongName" SG_ 193 WRSRDSeqNum "Wheel Rotational Status Right Driven : Sequence Number";
BA_ "PacketOrder" SG_ 193 WRSRDSeqNum 2;
BA_ "SignalType" SG_ 193 WRSRDSeqNum "UNM";
BA_ "VNSigAllNodes" SG_ 193 WRSRDSeqNum 1;
BA_ "SignalLongName" SG_ 193 WRSRDWhlRotStatRst "Wheel Rotational Status Right Driven : Wheel Rotational Status Reset Occurred";
BA_ "PacketOrder" SG_ 193 WRSRDWhlRotStatRst 3;
BA_ "SignalType" SG_ 193 WRSRDWhlRotStatRst "BLN";
BA_ "VNSigAllNodes" SG_ 193 WRSRDWhlRotStatRst 1;
BA_ "SignalLongName" SG_ 193 WRSRDWhlDistVal "Wheel Rotational Status Right Driven : Wheel Distance Validity";
BA_ "PacketOrder" SG_ 193 WRSRDWhlDistVal 4;
BA_ "SignalType" SG_ 193 WRSRDWhlDistVal "ENM";
BA_ "VNSigAllNodes" SG_ 193 WRSRDWhlDistVal 1;
BA_ "SignalLongName" SG_ 193 WRSRDWhlDistTmstm "Wheel Rotational Status Right Driven : Wheel Distance Timestamp";
BA_ "PacketOrder" SG_ 193 WRSRDWhlDistTmstm 6;
BA_ "SignalType" SG_ 193 WRSRDWhlDistTmstm "UNM";
BA_ "VNSigAllNodes" SG_ 193 WRSRDWhlDistTmstm 1;
BA_ "SignalLongName" SG_ 193 WRSRDWhlDistPlsCntr "Wheel Rotational Status Right Driven : Wheel Distance Pulse Counter";
BA_ "PacketOrder" SG_ 193 WRSRDWhlDistPlsCntr 5;
BA_ "SignalType" SG_ 193 WRSRDWhlDistPlsCntr "UNM";
BA_ "VNSigAllNodes" SG_ 193 WRSRDWhlDistPlsCntr 1;
BA_ "SignalLongName" SG_ 481 AdptCrsGapSwAct "Adaptive Cruise Control Gap Switch Activation";
BA_ "SignalType" SG_ 481 AdptCrsGapSwAct "ENM";
BA_ "VNSigAllNodes" SG_ 481 AdptCrsGapSwAct 1;
BA_ "GenSigSendType" SG_ 481 AdptCrsGapSwAct 10;
BA_ "SignalLongName" SG_ 481 CrsSecSwStat "Cruise Secondary Switch Status";
BA_ "SignalType" SG_ 481 CrsSecSwStat "ENM";
BA_ "VNSigAllNodes" SG_ 481 CrsSecSwStat 1;
BA_ "SignalLongName" SG_ 481 DrvSelMdSw3Sta "Driver Selected Mode Switch 3 State";
BA_ "SignalType" SG_ 481 DrvSelMdSw3Sta "ENM";
BA_ "VNSigAllNodes" SG_ 481 DrvSelMdSw3Sta 1;
BA_ "SignalLongName" SG_ 481 DrvSelMdSw2Sta "Driver Selected Mode Switch 2 State";
BA_ "SignalType" SG_ 481 DrvSelMdSw2Sta "ENM";
BA_ "VNSigAllNodes" SG_ 481 DrvSelMdSw2Sta 1;
BA_ "SignalLongName" SG_ 481 AuxHtrRq "Auxiliary Heater Request";
BA_ "SignalType" SG_ 481 AuxHtrRq "ENM";
BA_ "VNSigAllNodes" SG_ 481 AuxHtrRq 1;
BA_ "GenSigSendType" SG_ 481 AuxHtrRq 10;
BA_ "SignalLongName" SG_ 481 AuxHtrAtv "Auxiliary Heater Active";
BA_ "SignalType" SG_ 481 AuxHtrAtv "BLN";
BA_ "VNSigAllNodes" SG_ 481 AuxHtrAtv 1;
BA_ "GenSigSendType" SG_ 481 AuxHtrAtv 10;
BA_ "SignalLongName" SG_ 481 DrvSelMdSwStaARC "Driver Selected Mode Switch State Alive Rolling Count";
BA_ "SignalType" SG_ 481 DrvSelMdSwStaARC "UNM";
BA_ "VNSigAllNodes" SG_ 481 DrvSelMdSwStaARC 1;
BA_ "SignalLongName" SG_ 481 DrvSelMdSw1Sta "Driver Selected Mode Switch 1 State";
BA_ "SignalType" SG_ 481 DrvSelMdSw1Sta "ENM";
BA_ "VNSigAllNodes" SG_ 481 DrvSelMdSw1Sta 1;
BA_ "SignalLongName" SG_ 481 CrsSpdLmtrSwStatPVal "Cruise and Speed Limiter Switch Status Protection Value";
BA_ "SignalType" SG_ 481 CrsSpdLmtrSwStatPVal "UNM";
BA_ "VNSigAllNodes" SG_ 481 CrsSpdLmtrSwStatPVal 1;
BA_ "SignalLongName" SG_ 481 CrsSpdLmtrSwStatARC "Cruise and Speed Limiter Switch Status Alive Rolling Count";
BA_ "SignalType" SG_ 481 CrsSpdLmtrSwStatARC "UNM";
BA_ "VNSigAllNodes" SG_ 481 CrsSpdLmtrSwStatARC 1;
BA_ "SignalLongName" SG_ 481 FuelMdSwActV "Fuel Mode Switch Active Validity";
BA_ "SignalType" SG_ 481 FuelMdSwActV "ENM";
BA_ "VNSigAllNodes" SG_ 481 FuelMdSwActV 1;
BA_ "SignalLongName" SG_ 481 FuelMdSwAct "Fuel Mode Switch Active";
BA_ "SignalType" SG_ 481 FuelMdSwAct "ENM";
BA_ "VNSigAllNodes" SG_ 481 FuelMdSwAct 1;
BA_ "SignalLongName" SG_ 481 CrsSpdLmtrSwStat "Cruise and Speed Limiter Switch Status";
BA_ "SignalType" SG_ 481 CrsSpdLmtrSwStat "ENM";
BA_ "VNSigAllNodes" SG_ 481 CrsSpdLmtrSwStat 1;
BA_ "GenSigSendType" SG_ 481 CrsSpdLmtrSwStat 10;
BA_ "SignalLongName" SG_ 481 CrsCntrlSwStCanSwAct "Cruise Control Switch Status : Cancel Switch Active";
BA_ "PacketOrder" SG_ 481 CrsCntrlSwStCanSwAct 1;
BA_ "SignalType" SG_ 481 CrsCntrlSwStCanSwAct "BLN";
BA_ "VNSigAllNodes" SG_ 481 CrsCntrlSwStCanSwAct 1;
BA_ "GenSigSendType" SG_ 481 CrsCntrlSwStCanSwAct 10;
BA_ "GenSigSendOnInit" SG_ 481 CrsCntrlSwStCanSwAct 2;
BA_ "SignalLongName" SG_ 481 CrsCntrlSwStSwDataIntgty "Cruise Control Switch Status : Switch Data Integrity";
BA_ "PacketOrder" SG_ 481 CrsCntrlSwStSwDataIntgty 7;
BA_ "SignalType" SG_ 481 CrsCntrlSwStSwDataIntgty "ENM";
BA_ "VNSigAllNodes" SG_ 481 CrsCntrlSwStSwDataIntgty 1;
BA_ "GenSigSendType" SG_ 481 CrsCntrlSwStSwDataIntgty 10;
BA_ "GenSigSendOnInit" SG_ 481 CrsCntrlSwStSwDataIntgty 2;
BA_ "SignalLongName" SG_ 481 CrsCntrlSwStSpdInSwAct "Cruise Control Switch Status : Speed Increase Switch Active";
BA_ "PacketOrder" SG_ 481 CrsCntrlSwStSpdInSwAct 5;
BA_ "SignalType" SG_ 481 CrsCntrlSwStSpdInSwAct "BLN";
BA_ "VNSigAllNodes" SG_ 481 CrsCntrlSwStSpdInSwAct 1;
BA_ "GenSigSendType" SG_ 481 CrsCntrlSwStSpdInSwAct 10;
BA_ "GenSigSendOnInit" SG_ 481 CrsCntrlSwStSpdInSwAct 2;
BA_ "SignalLongName" SG_ 481 CrsCntrlSwStSpDcSwAct "Cruise Control Switch Status : Speed Decrease Switch Active";
BA_ "PacketOrder" SG_ 481 CrsCntrlSwStSpDcSwAct 6;
BA_ "SignalType" SG_ 481 CrsCntrlSwStSpDcSwAct "BLN";
BA_ "VNSigAllNodes" SG_ 481 CrsCntrlSwStSpDcSwAct 1;
BA_ "GenSigSendType" SG_ 481 CrsCntrlSwStSpDcSwAct 10;
BA_ "GenSigSendOnInit" SG_ 481 CrsCntrlSwStSpDcSwAct 2;
BA_ "SignalLongName" SG_ 481 CrsCntrlSwStSetSwAct "Cruise Control Switch Status : Set Switch Active";
BA_ "PacketOrder" SG_ 481 CrsCntrlSwStSetSwAct 4;
BA_ "SignalType" SG_ 481 CrsCntrlSwStSetSwAct "BLN";
BA_ "VNSigAllNodes" SG_ 481 CrsCntrlSwStSetSwAct 1;
BA_ "GenSigSendType" SG_ 481 CrsCntrlSwStSetSwAct 10;
BA_ "GenSigSendOnInit" SG_ 481 CrsCntrlSwStSetSwAct 2;
BA_ "SignalLongName" SG_ 481 CrsCntrlSwStResSwAct "Cruise Control Switch Status : Resume Switch Active";
BA_ "PacketOrder" SG_ 481 CrsCntrlSwStResSwAct 3;
BA_ "SignalType" SG_ 481 CrsCntrlSwStResSwAct "BLN";
BA_ "VNSigAllNodes" SG_ 481 CrsCntrlSwStResSwAct 1;
BA_ "GenSigSendType" SG_ 481 CrsCntrlSwStResSwAct 10;
BA_ "GenSigSendOnInit" SG_ 481 CrsCntrlSwStResSwAct 2;
BA_ "SignalLongName" SG_ 481 CrsCntrlSwStOnSwAct "Cruise Control Switch Status : On Switch Active";
BA_ "PacketOrder" SG_ 481 CrsCntrlSwStOnSwAct 2;
BA_ "SignalType" SG_ 481 CrsCntrlSwStOnSwAct "BLN";
BA_ "VNSigAllNodes" SG_ 481 CrsCntrlSwStOnSwAct 1;
BA_ "GenSigSendType" SG_ 481 CrsCntrlSwStOnSwAct 10;
BA_ "GenSigSendOnInit" SG_ 481 CrsCntrlSwStOnSwAct 2;
BA_ "SignalLongName" SG_ 481 CrsCntrlSwStatProtValue "Cruise Control Switch Status Protection Value";
BA_ "SignalType" SG_ 481 CrsCntrlSwStatProtValue "UNM";
BA_ "VNSigAllNodes" SG_ 481 CrsCntrlSwStatProtValue 1;
BA_ "SignalLongName" SG_ 481 CrsCntrlSwStAlvRollCnt "Cruise Control Switch Status Alive Rolling Count";
BA_ "SignalType" SG_ 481 CrsCntrlSwStAlvRollCnt "UNM";
BA_ "VNSigAllNodes" SG_ 481 CrsCntrlSwStAlvRollCnt 1;
BA_ "SignalLongName" SG_ 481 CrsCntCncRq "Cruise Control Cancel Request";
BA_ "SignalType" SG_ 481 CrsCntCncRq "ENM";
BA_ "VNSigAllNodes" SG_ 481 CrsCntCncRq 1;
BA_ "SignalLongName" SG_ 481 CrsSecSwStatPVal "Cruise Secondary Switch Status Protection Value";
BA_ "SignalType" SG_ 481 CrsSecSwStatPVal "UNM";
BA_ "VNSigAllNodes" SG_ 481 CrsSecSwStatPVal 1;
BA_ "SignalLongName" SG_ 481 CrsSecSwStatARC "Cruise Secondary Switch Status Alive Rolling Count";
BA_ "SignalType" SG_ 481 CrsSecSwStatARC "UNM";
BA_ "VNSigAllNodes" SG_ 481 CrsSecSwStatARC 1;
BA_ "SignalLongName" SG_ 455 CSETRER_TorqReqVal "Chassis System Engine Torque Request Extended Range : Torque Request Value";
BA_ "PacketOrder" SG_ 455 CSETRER_TorqReqVal 2;
BA_ "SignalType" SG_ 455 CSETRER_TorqReqVal "UNM";
BA_ "VNSigAllNodes" SG_ 455 CSETRER_TorqReqVal 1;
BA_ "SignalLongName" SG_ 455 CSETRER_TqIntvnTyp "Chassis System Engine Torque Request Extended Range : Torque Intervention Type";
BA_ "PacketOrder" SG_ 455 CSETRER_TqIntvnTyp 1;
BA_ "SignalType" SG_ 455 CSETRER_TqIntvnTyp "ENM";
BA_ "VNSigAllNodes" SG_ 455 CSETRER_TqIntvnTyp 1;
BA_ "SignalLongName" SG_ 455 TracCntrlMaxTorqIncRt "Traction Control Maximum Torque Increase Rate";
BA_ "SignalType" SG_ 455 TracCntrlMaxTorqIncRt "UNM";
BA_ "VNSigAllNodes" SG_ 455 TracCntrlMaxTorqIncRt 1;
BA_ "SignalLongName" SG_ 455 TCAliveRC "Traction Control Alive Rolling Count";
BA_ "SignalType" SG_ 455 TCAliveRC "UNM";
BA_ "VNSigAllNodes" SG_ 455 TCAliveRC 1;
BA_ "SignalLongName" SG_ 455 ChsSysEngTrqReqProt "Chassis System Engine Torque Request Protection";
BA_ "SignalType" SG_ 455 ChsSysEngTrqReqProt "UNM";
BA_ "VNSigAllNodes" SG_ 455 ChsSysEngTrqReqProt 1;
BA_ "SignalLongName" SG_ 761 SprTireSt "Spare Tire Status";
BA_ "SignalType" SG_ 761 SprTireSt "ENM";
BA_ "VNSigAllNodes" SG_ 761 SprTireSt 1;
BA_ "SignalLongName" SG_ 761 BrkSysHRBkCtrlAvail "Brake System Hill Rollback Control Available";
BA_ "SignalType" SG_ 761 BrkSysHRBkCtrlAvail "BLN";
BA_ "VNSigAllNodes" SG_ 761 BrkSysHRBkCtrlAvail 1;
BA_ "SignalLongName" SG_ 761 BrkSysHRBkCtrlStat "Brake System Hill Rollback Control Status";
BA_ "SignalType" SG_ 761 BrkSysHRBkCtrlStat "ENM";
BA_ "VNSigAllNodes" SG_ 761 BrkSysHRBkCtrlStat 1;
BA_ "SignalLongName" SG_ 761 BrkSysHSAAval "Brake System Hill Start Assist Available";
BA_ "SignalType" SG_ 761 BrkSysHSAAval "BLN";
BA_ "VNSigAllNodes" SG_ 761 BrkSysHSAAval 1;
BA_ "SignalLongName" SG_ 761 BrkSysHSAStat "Brake System Hill Start Assist Status";
BA_ "SignalType" SG_ 761 BrkSysHSAStat "ENM";
BA_ "VNSigAllNodes" SG_ 761 BrkSysHSAStat 1;
BA_ "SignalLongName" SG_ 761 HillDscntCtrlStatPVal "Hill Descent Control Status Protection Value";
BA_ "SignalType" SG_ 761 HillDscntCtrlStatPVal "UNM";
BA_ "VNSigAllNodes" SG_ 761 HillDscntCtrlStatPVal 1;
BA_ "SignalLongName" SG_ 761 HillDscntCtrlStatARC "Hill Descent Control Status Alive Rolling Count";
BA_ "SignalType" SG_ 761 HillDscntCtrlStatARC "UNM";
BA_ "VNSigAllNodes" SG_ 761 HillDscntCtrlStatARC 1;
BA_ "SignalLongName" SG_ 761 HillDscntCtrlStat "Hill Descent Control Status";
BA_ "SignalType" SG_ 761 HillDscntCtrlStat "ENM";
BA_ "VNSigAllNodes" SG_ 761 HillDscntCtrlStat 1;
BA_ "SignalLongName" SG_ 761 AutoBrkFeatInhbtPVal "Automatic Braking Feature Inhibit Protection Value";
BA_ "SignalType" SG_ 761 AutoBrkFeatInhbtPVal "UNM";
BA_ "VNSigAllNodes" SG_ 761 AutoBrkFeatInhbtPVal 1;
BA_ "SignalLongName" SG_ 761 AutoBrkFeatInhbtARC "Automatic Braking Feature Inhibit Alive Rolling Count";
BA_ "SignalType" SG_ 761 AutoBrkFeatInhbtARC "UNM";
BA_ "VNSigAllNodes" SG_ 761 AutoBrkFeatInhbtARC 1;
BA_ "SignalLongName" SG_ 761 ABFI_CollPrepSysInhbt "Automatic Braking Feature Inhibit : Collision Preparation System Inhibit";
BA_ "PacketOrder" SG_ 761 ABFI_CollPrepSysInhbt 2;
BA_ "SignalType" SG_ 761 ABFI_CollPrepSysInhbt "BLN";
BA_ "VNSigAllNodes" SG_ 761 ABFI_CollPrepSysInhbt 1;
BA_ "SignalLongName" SG_ 761 ABFI_RrVirtlBmprInh "Automatic Braking Feature Inhibit : Rear Virtual Bumper Inhibit";
BA_ "PacketOrder" SG_ 761 ABFI_RrVirtlBmprInh 1;
BA_ "SignalType" SG_ 761 ABFI_RrVirtlBmprInh "BLN";
BA_ "VNSigAllNodes" SG_ 761 ABFI_RrVirtlBmprInh 1;
BA_ "SignalLongName" SG_ 761 BrkPdlDrvApplPresV "Brake Pedal Driver Applied Pressure Validity";
BA_ "SignalType" SG_ 761 BrkPdlDrvApplPresV "ENM";
BA_ "VNSigAllNodes" SG_ 761 BrkPdlDrvApplPresV 1;
BA_ "SignalLongName" SG_ 761 BrkPdlDrvApplPres "Brake Pedal Driver Applied Pressure";
BA_ "SignalType" SG_ 761 BrkPdlDrvApplPres "UNM";
BA_ "VNSigAllNodes" SG_ 761 BrkPdlDrvApplPres 1;
BA_ "SignalLongName" SG_ 761 AutoBrkPTReqStat "Automatic Braking Powertrain Request Status";
BA_ "SignalType" SG_ 761 AutoBrkPTReqStat "ENM";
BA_ "VNSigAllNodes" SG_ 761 AutoBrkPTReqStat 1;
BA_ "SignalLongName" SG_ 761 WhlSpdSnsgDTCIndex "Wheel Speed Sensing Legislated Diagnostic Status : Diagnostic Trouble Code Index";
BA_ "PacketOrder" SG_ 761 WhlSpdSnsgDTCIndex 1;
BA_ "SignalType" SG_ 761 WhlSpdSnsgDTCIndex "UNM";
BA_ "VNSigAllNodes" SG_ 761 WhlSpdSnsgDTCIndex 1;
BA_ "SignalLongName" SG_ 761 WhlSpdSnsgDTCStat "Wheel Speed Sensing Legislated Diagnostic Status : Diagnostic Trouble Code Status";
BA_ "PacketOrder" SG_ 761 WhlSpdSnsgDTCStat 2;
BA_ "SignalType" SG_ 761 WhlSpdSnsgDTCStat "ENM";
BA_ "VNSigAllNodes" SG_ 761 WhlSpdSnsgDTCStat 1;
BA_ "SignalLongName" SG_ 489 VehDynYawRateV "Vehicle Dynamics Yaw Rate Validity";
BA_ "SignalType" SG_ 489 VehDynYawRateV "ENM";
BA_ "VNSigAllNodes" SG_ 489 VehDynYawRateV 1;
BA_ "SignalLongName" SG_ 489 VehDynYawRate "Vehicle Dynamics Yaw Rate";
BA_ "SignalType" SG_ 489 VehDynYawRate "SNM";
BA_ "VNSigAllNodes" SG_ 489 VehDynYawRate 1;
BA_ "SignalLongName" SG_ 489 BSTGRReqdGear "Brake System Transmission Gear Request : Requested Gear";
BA_ "PacketOrder" SG_ 489 BSTGRReqdGear 2;
BA_ "SignalType" SG_ 489 BSTGRReqdGear "ENM";
BA_ "VNSigAllNodes" SG_ 489 BSTGRReqdGear 1;
BA_ "SignalLongName" SG_ 489 BSTGRReqType "Brake System Transmission Gear Request : Request Type";
BA_ "PacketOrder" SG_ 489 BSTGRReqType 1;
BA_ "SignalType" SG_ 489 BSTGRReqType "ENM";
BA_ "VNSigAllNodes" SG_ 489 BSTGRReqType 1;
BA_ "SignalLongName" SG_ 489 TrnsBrkSysCltchRelRqd "Transmission Brake System Clutch state0800 Requested";
BA_ "SignalType" SG_ 489 TrnsBrkSysCltchRelRqd "BLN";
BA_ "VNSigAllNodes" SG_ 489 TrnsBrkSysCltchRelRqd 1;
BA_ "SignalLongName" SG_ 489 EnhDrvMdSwChUseRq "Enhanced Driver Selected Mode Switch Chassis Use Requested";
BA_ "SignalType" SG_ 489 EnhDrvMdSwChUseRq "BLN";
BA_ "VNSigAllNodes" SG_ 489 EnhDrvMdSwChUseRq 1;
BA_ "SignalLongName" SG_ 489 DrvIndpntBrkAppAct "Driver Independent Brake Apply Active";
BA_ "SignalType" SG_ 489 DrvIndpntBrkAppAct "BLN";
BA_ "VNSigAllNodes" SG_ 489 DrvIndpntBrkAppAct 1;
BA_ "SignalLongName" SG_ 489 WhlSlpSt "Wheel Slip Status";
BA_ "SignalType" SG_ 489 WhlSlpSt "ENM";
BA_ "VNSigAllNodes" SG_ 489 WhlSlpSt 1;
BA_ "SignalLongName" SG_ 489 VSELatAccV "Vehicle Stability Enhancement Lateral Acceleration Validity";
BA_ "SignalType" SG_ 489 VSELatAccV "ENM";
BA_ "VNSigAllNodes" SG_ 489 VSELatAccV 1;
BA_ "SignalLongName" SG_ 489 VSELatAcc "Vehicle Stability Enhancement Lateral Acceleration";
BA_ "SignalType" SG_ 489 VSELatAcc "SNM";
BA_ "VNSigAllNodes" SG_ 489 VSELatAcc 1;
BA_ "SignalLongName" SG_ 489 VSEAct "Vehicle Stability Enhancement System Active";
BA_ "SignalType" SG_ 489 VSEAct "BLN";
BA_ "VNSigAllNodes" SG_ 489 VSEAct 1;
BA_ "SignalLongName" SG_ 489 VhDynCntlSysSt "Vehicle Dynamics Control System Status";
BA_ "SignalType" SG_ 489 VhDynCntlSysSt "ENM";
BA_ "VNSigAllNodes" SG_ 489 VhDynCntlSysSt 1;
BA_ "SignalLongName" SG_ 489 TracCntrlSysDrIntnt "Traction Control System Driver Intent";
BA_ "SignalType" SG_ 489 TracCntrlSysDrIntnt "ENM";
BA_ "VNSigAllNodes" SG_ 489 TracCntrlSysDrIntnt 1;
BA_ "SignalLongName" SG_ 489 TCSysEnbld "Traction Control System Enabled";
BA_ "SignalType" SG_ 489 TCSysEnbld "BLN";
BA_ "VNSigAllNodes" SG_ 489 TCSysEnbld 1;
BA_ "SignalLongName" SG_ 489 TCSysAtv "Traction Control System Active";
BA_ "SignalType" SG_ 489 TCSysAtv "BLN";
BA_ "VNSigAllNodes" SG_ 489 TCSysAtv 1;
BA_ "SignalLongName" SG_ 489 BrkPdlDrvAppPrsDetcdV "Brake Pedal Driver Applied Pressure Detected Validity";
BA_ "SignalType" SG_ 489 BrkPdlDrvAppPrsDetcdV "ENM";
BA_ "VNSigAllNodes" SG_ 489 BrkPdlDrvAppPrsDetcdV 1;
BA_ "GenSigStartValue" SG_ 489 BrkPdlDrvAppPrsDetcd 1;
BA_ "SignalLongName" SG_ 489 BrkPdlDrvAppPrsDetcd "Brake Pedal Driver Applied Pressure Detected";
BA_ "SignalType" SG_ 489 BrkPdlDrvAppPrsDetcd "BLN";
BA_ "VNSigAllNodes" SG_ 489 BrkPdlDrvAppPrsDetcd 1;
BA_ "SignalLongName" SG_ 489 ACCBrkngAct "Adaptive Cruise Control Braking Active";
BA_ "SignalType" SG_ 489 ACCBrkngAct "BLN";
BA_ "VNSigAllNodes" SG_ 489 ACCBrkngAct 1;
BA_ "SignalLongName" SG_ 489 ABSFld "Antilock Brake System Failed";
BA_ "SignalType" SG_ 489 ABSFld "BLN";
BA_ "VNSigAllNodes" SG_ 489 ABSFld 1;
BA_ "SignalLongName" SG_ 489 ABSAtv "Antilock Brake System Active";
BA_ "SignalType" SG_ 489 ABSAtv "BLN";
BA_ "VNSigAllNodes" SG_ 489 ABSAtv 1;
BA_ "SignalLongName" SG_ 489 IMUDataMsk "Inertial Measurement Unit Data Mask";
BA_ "SignalType" SG_ 489 IMUDataMsk "BLN";
BA_ "VNSigAllNodes" SG_ 489 IMUDataMsk 1;
BA_ "SignalLongName" SG_ 489 VehDynOvrUndrStr "Vehicle Dynamics Over Under Steer";
BA_ "SignalType" SG_ 489 VehDynOvrUndrStr "SNM";
BA_ "VNSigAllNodes" SG_ 489 VehDynOvrUndrStr 1;
BA_ "SignalLongName" SG_ 489 VehDynOvrUndrStrV "Vehicle Dynamics Over Under Steer Validity";
BA_ "SignalType" SG_ 489 VehDynOvrUndrStrV "ENM";
BA_ "VNSigAllNodes" SG_ 489 VehDynOvrUndrStrV 1;
BA_ "SignalLongName" SG_ 381 HillDesCtrlRedVehSpIO "Hill Descent Control Reduce Vehicle Speed Indication On";
BA_ "SignalType" SG_ 381 HillDesCtrlRedVehSpIO "BLN";
BA_ "VNSigAllNodes" SG_ 381 HillDesCtrlRedVehSpIO 1;
BA_ "SignalLongName" SG_ 381 EBDFailed "Electronic Brake Distribution Failed";
BA_ "SignalType" SG_ 381 EBDFailed "BLN";
BA_ "VNSigAllNodes" SG_ 381 EBDFailed 1;
BA_ "GenSigStartValue" SG_ 381 StWhAnVDA 1;
BA_ "SignalLongName" SG_ 381 StWhAnVDA "Steering Wheel Angle Virtual Device Availability";
BA_ "SignalType" SG_ 381 StWhAnVDA "ENM";
BA_ "VNSigAllNodes" SG_ 381 StWhAnVDA 1;
BA_ "SignalLongName" SG_ 381 TirePrsLowIO "Tire Pressure Low Indication On";
BA_ "SignalType" SG_ 381 TirePrsLowIO "BLN";
BA_ "VNSigAllNodes" SG_ 381 TirePrsLowIO 1;
BA_ "SignalLongName" SG_ 381 VaccBoostFailure "Vaccum Boost Failure";
BA_ "SignalType" SG_ 381 VaccBoostFailure "BLN";
BA_ "VNSigAllNodes" SG_ 381 VaccBoostFailure 1;
BA_ "SignalLongName" SG_ 381 VSESysPrs "Vehicle Stability Enhancement System Present";
BA_ "SignalType" SG_ 381 VSESysPrs "BLN";
BA_ "VNSigAllNodes" SG_ 381 VSESysPrs 1;
BA_ "SignalLongName" SG_ 381 HalfSysFail "Half System Failure";
BA_ "SignalType" SG_ 381 HalfSysFail "BLN";
BA_ "VNSigAllNodes" SG_ 381 HalfSysFail 1;
BA_ "SignalLongName" SG_ 381 BksOvht "Brakes Overheated";
BA_ "SignalType" SG_ 381 BksOvht "BLN";
BA_ "VNSigAllNodes" SG_ 381 BksOvht 1;
BA_ "SignalLongName" SG_ 381 TCSysPr "Traction Control System Present";
BA_ "SignalType" SG_ 381 TCSysPr "BLN";
BA_ "VNSigAllNodes" SG_ 381 TCSysPr 1;
BA_ "SignalLongName" SG_ 381 ABSPr "Antilock Brake System Present";
BA_ "SignalType" SG_ 381 ABSPr "BLN";
BA_ "VNSigAllNodes" SG_ 381 ABSPr 1;
BA_ "SignalLongName" SG_ 381 TreInfMonSysRstPrfmd "Tire Inflation Monitoring System Reset Performed";
BA_ "SignalType" SG_ 381 TreInfMonSysRstPrfmd "BLN";
BA_ "VNSigAllNodes" SG_ 381 TreInfMonSysRstPrfmd 1;
BA_ "SignalLongName" SG_ 381 ABSIO "Antilock Brake System Indication On";
BA_ "SignalType" SG_ 381 ABSIO "BLN";
BA_ "VNSigAllNodes" SG_ 381 ABSIO 1;
BA_ "SignalLongName" SG_ 381 BrkPadWrnIO "Brake Pad Worn Indication On";
BA_ "SignalType" SG_ 381 BrkPadWrnIO "BLN";
BA_ "VNSigAllNodes" SG_ 381 BrkPadWrnIO 1;
BA_ "SignalLongName" SG_ 381 VehStabEnhmntMd "Vehicle Stability Enhancement Mode";
BA_ "SignalType" SG_ 381 VehStabEnhmntMd "ENM";
BA_ "VNSigAllNodes" SG_ 381 VehStabEnhmntMd 1;
BA_ "SignalLongName" SG_ 381 VehStabEnhmntStat "Vehicle Stability Enhancement Status";
BA_ "SignalType" SG_ 381 VehStabEnhmntStat "ENM";
BA_ "VNSigAllNodes" SG_ 381 VehStabEnhmntStat 1;
BA_ "SignalLongName" SG_ 381 TCSysOpMd "Traction Control System Operating Mode";
BA_ "SignalType" SG_ 381 TCSysOpMd "ENM";
BA_ "VNSigAllNodes" SG_ 381 TCSysOpMd 1;
BA_ "SignalLongName" SG_ 381 TCSysOpStat "Traction Control System Operating Status";
BA_ "SignalType" SG_ 381 TCSysOpStat "ENM";
BA_ "VNSigAllNodes" SG_ 381 TCSysOpStat 1;
BA_ "GenSigStartValue" SG_ 381 BrkSysVTopSpdLimVal 255;
BA_ "SignalLongName" SG_ 381 BrkSysVTopSpdLimVal "Braking System Vehicle Top Speed Limit Value";
BA_ "SignalType" SG_ 381 BrkSysVTopSpdLimVal "UNM";
BA_ "VNSigAllNodes" SG_ 381 BrkSysVTopSpdLimVal 1;
BA_ "SignalLongName" SG_ 381 BrkSysRedBrkTlltlReq "Brake System Red Brake Telltale Request";
BA_ "SignalType" SG_ 381 BrkSysRedBrkTlltlReq "BLN";
BA_ "VNSigAllNodes" SG_ 381 BrkSysRedBrkTlltlReq 1;
BA_ "SignalLongName" SG_ 381 BrkSysBrkLtsReqd "Brake System Brake Lights Requested";
BA_ "SignalType" SG_ 381 BrkSysBrkLtsReqd "BLN";
BA_ "VNSigAllNodes" SG_ 381 BrkSysBrkLtsReqd 1;
BA_ "SignalLongName" SG_ 381 ActVehAccel "Actual Vehicle Acceleration";
BA_ "SignalType" SG_ 381 ActVehAccel "SNM";
BA_ "VNSigAllNodes" SG_ 381 ActVehAccel 1;
BA_ "SignalLongName" SG_ 381 ActVehAccelV "Actual Vehicle Acceleration Validity";
BA_ "SignalType" SG_ 381 ActVehAccelV "ENM";
BA_ "VNSigAllNodes" SG_ 381 ActVehAccelV 1;
BA_ "SignalLongName" SG_ 241 BrkPdlChkData "Brake Pedal Check Data";
BA_ "SignalType" SG_ 241 BrkPdlChkData "UNM";
BA_ "VNSigAllNodes" SG_ 241 BrkPdlChkData 1;
BA_ "SignalLongName" SG_ 241 BrkPdlPosGrad "Brake Pedal Position Gradient";
BA_ "SignalType" SG_ 241 BrkPdlPosGrad "SNM";
BA_ "VNSigAllNodes" SG_ 241 BrkPdlPosGrad 1;
BA_ "SignalLongName" SG_ 241 NotEventStat "Notification Event Status";
BA_ "SignalType" SG_ 241 NotEventStat "ENM";
BA_ "VNSigAllNodes" SG_ 241 NotEventStat 1;
BA_ "GenSigSendType" SG_ 241 NotEventStat 10;
BA_ "SignalLongName" SG_ 241 BrkAppSnsrHmPosLrnd "Brake Apply Sensor Home Position Learned";
BA_ "SignalType" SG_ 241 BrkAppSnsrHmPosLrnd "BLN";
BA_ "VNSigAllNodes" SG_ 241 BrkAppSnsrHmPosLrnd 1;
BA_ "SignalLongName" SG_ 241 BrkPedTrvlAchvd "Brake Pedal Initial Travel Achieved Status : Brake Pedal Initial Travel Achieved";
BA_ "PacketOrder" SG_ 241 BrkPedTrvlAchvd 1;
BA_ "SignalType" SG_ 241 BrkPedTrvlAchvd "BLN";
BA_ "VNSigAllNodes" SG_ 241 BrkPedTrvlAchvd 1;
BA_ "GenSigSendType" SG_ 241 BrkPedTrvlAchvd 10;
BA_ "SignalLongName" SG_ 241 BrkPedTrvlAchvdV "Brake Pedal Initial Travel Achieved Status : Brake Pedal Initial Travel Achieved Validity";
BA_ "PacketOrder" SG_ 241 BrkPedTrvlAchvdV 2;
BA_ "SignalType" SG_ 241 BrkPedTrvlAchvdV "ENM";
BA_ "VNSigAllNodes" SG_ 241 BrkPedTrvlAchvdV 1;
BA_ "GenSigSendType" SG_ 241 BrkPedTrvlAchvdV 10;
BA_ "SignalLongName" SG_ 241 BrkPdlPos "Brake Pedal Position";
BA_ "SignalType" SG_ 241 BrkPdlPos "UNM";
BA_ "VNSigAllNodes" SG_ 241 BrkPdlPos 1;
BA_ "GenSigDeltaValue" SG_ 241 BrkPdlPos 2;
BA_ "GenSigSendType" SG_ 241 BrkPdlPos 12;
BA_ "GenSigSendOnInit" SG_ 241 BrkPdlPos 1;
BA_ "SignalLongName" SG_ 241 BrkPedPosAlvRolngCnt "Brake Pedal Position Alive Rolling Count";
BA_ "SignalType" SG_ 241 BrkPedPosAlvRolngCnt "UNM";
BA_ "VNSigAllNodes" SG_ 241 BrkPedPosAlvRolngCnt 1;
BA_ "SignalLongName" SG_ 241 BrkPdlModTrvlV "Brake Pedal Moderate Travel Achieved Validity";
BA_ "SignalType" SG_ 241 BrkPdlModTrvlV "ENM";
BA_ "VNSigAllNodes" SG_ 241 BrkPdlModTrvlV 1;
BA_ "GenSigSendType" SG_ 241 BrkPdlModTrvlV 10;
BA_ "SignalLongName" SG_ 241 BrkPdlModTrvl "Brake Pedal Moderate Travel Achieved";
BA_ "SignalType" SG_ 241 BrkPdlModTrvl "BLN";
BA_ "VNSigAllNodes" SG_ 241 BrkPdlModTrvl 1;
BA_ "GenSigSendType" SG_ 241 BrkPdlModTrvl 10;
BA_ "SignalLongName" SG_ 241 BrkPdlInTrvPrt "Brake Pedal Initial Travel Achieved Protection";
BA_ "SignalType" SG_ 241 BrkPdlInTrvPrt "UNM";
BA_ "VNSigAllNodes" SG_ 241 BrkPdlInTrvPrt 1;
BA_ "SignalLongName" SG_ 1271 BatSvrMdLvl7Act "Battery Saver Mode Level 7 Active";
BA_ "SignalType" SG_ 1271 BatSvrMdLvl7Act "BLN";
BA_ "VNSigAllNodes" SG_ 1271 BatSvrMdLvl7Act 1;
BA_ "SignalLongName" SG_ 1271 BatSvrMdNetAmpHr "Battery Saver Mode Net Amp Hour";
BA_ "SignalType" SG_ 1271 BatSvrMdNetAmpHr "UNM";
BA_ "VNSigAllNodes" SG_ 1271 BatSvrMdNetAmpHr 1;
BA_ "SignalLongName" SG_ 1271 BatSvrMdWkUpCtr "Battery Saver Mode Wake Up Counter";
BA_ "SignalType" SG_ 1271 BatSvrMdWkUpCtr "UNM";
BA_ "VNSigAllNodes" SG_ 1271 BatSvrMdWkUpCtr 1;
BA_ "SignalLongName" SG_ 1271 BSMCT_RawVal "Battery Saver Mode Current Trigger : Raw Value";
BA_ "PacketOrder" SG_ 1271 BSMCT_RawVal 2;
BA_ "SignalType" SG_ 1271 BSMCT_RawVal "UNM";
BA_ "VNSigAllNodes" SG_ 1271 BSMCT_RawVal 1;
BA_ "SignalLongName" SG_ 1271 BSMCT_Mult "Battery Saver Mode Current Trigger : Multiplier";
BA_ "PacketOrder" SG_ 1271 BSMCT_Mult 1;
BA_ "SignalType" SG_ 1271 BSMCT_Mult "ENM";
BA_ "VNSigAllNodes" SG_ 1271 BSMCT_Mult 1;
BA_ "SignalLongName" SG_ 1271 BatSvrMdVltTrg "Battery Saver Mode Voltage Trigger";
BA_ "SignalType" SG_ 1271 BatSvrMdVltTrg "UNM";
BA_ "VNSigAllNodes" SG_ 1271 BatSvrMdVltTrg 1;
BA_ "SignalLongName" SG_ 1271 BatSvrMdLvl6Act "Battery Saver Mode Level 6 Active";
BA_ "SignalType" SG_ 1271 BatSvrMdLvl6Act "BLN";
BA_ "VNSigAllNodes" SG_ 1271 BatSvrMdLvl6Act 1;
BA_ "SignalLongName" SG_ 1271 BatSvrMdLvl5Act "Battery Saver Mode Level 5 Active";
BA_ "SignalType" SG_ 1271 BatSvrMdLvl5Act "BLN";
BA_ "VNSigAllNodes" SG_ 1271 BatSvrMdLvl5Act 1;
BA_ "SignalLongName" SG_ 1271 BatSvrMdLvl4Act "Battery Saver Mode Level 4 Active";
BA_ "SignalType" SG_ 1271 BatSvrMdLvl4Act "BLN";
BA_ "VNSigAllNodes" SG_ 1271 BatSvrMdLvl4Act 1;
BA_ "GenSigStartValue" SG_ 1263 BatSOFVolt 200;
BA_ "SignalLongName" SG_ 1263 BatSOFVolt "Battery State Of Function Voltage";
BA_ "SignalType" SG_ 1263 BatSOFVolt "UNM";
BA_ "VNSigAllNodes" SG_ 1263 BatSOFVolt 1;
BA_ "GenSigStartValue" SG_ 1263 BatSOH 203.999928600025;
BA_ "SignalLongName" SG_ 1263 BatSOH "Battery State Of Health";
BA_ "SignalType" SG_ 1263 BatSOH "UNM";
BA_ "VNSigAllNodes" SG_ 1263 BatSOH 1;
BA_ "GenSigStartValue" SG_ 1263 IBSBatSOC 196;
BA_ "SignalLongName" SG_ 1263 IBSBatSOC "Intelligent Battery Sensor Battery State of Charge";
BA_ "SignalType" SG_ 1263 IBSBatSOC "UNM";
BA_ "VNSigAllNodes" SG_ 1263 IBSBatSOC 1;
BA_ "SignalLongName" SG_ 1263 BattSOXStat "Battery SOX Status";
BA_ "SignalType" SG_ 1263 BattSOXStat "ENM";
BA_ "VNSigAllNodes" SG_ 1263 BattSOXStat 1;
BA_ "SignalLongName" SG_ 1261 MinCrnkCrnt "Minimum Cranking Current";
BA_ "SignalType" SG_ 1261 MinCrnkCrnt "UNM";
BA_ "VNSigAllNodes" SG_ 1261 MinCrnkCrnt 1;
BA_ "SignalLongName" SG_ 1261 MinCrnkVlt "Minimum Cranking Voltage";
BA_ "SignalType" SG_ 1261 MinCrnkVlt "UNM";
BA_ "VNSigAllNodes" SG_ 1261 MinCrnkVlt 1;
BA_ "SignalLongName" SG_ 1261 MinCrnkCrntVltStat "Minimum Cranking Voltage and Current Status";
BA_ "SignalType" SG_ 1261 MinCrnkCrntVltStat "ENM";
BA_ "VNSigAllNodes" SG_ 1261 MinCrnkCrntVltStat 1;
BA_ "SignalLongName" SG_ 1261 BattTempV "Battery Temperature Validity";
BA_ "SignalType" SG_ 1261 BattTempV "ENM";
BA_ "VNSigAllNodes" SG_ 1261 BattTempV 1;
BA_ "SignalLongName" SG_ 1261 BattTempM "Battery Temperature Mask";
BA_ "SignalType" SG_ 1261 BattTempM "ENM";
BA_ "VNSigAllNodes" SG_ 1261 BattTempM 1;
BA_ "GenSigStartValue" SG_ 1261 BattTemp 65;
BA_ "SignalLongName" SG_ 1261 BattTemp "Battery Temperature";
BA_ "SignalType" SG_ 1261 BattTemp "UNM";
BA_ "VNSigAllNodes" SG_ 1261 BattTemp 1;
BA_ "SignalLongName" SG_ 1259 AllNodesVNA "All Nodes Virtual Network Activation";
BA_ "SignalType" SG_ 1259 AllNodesVNA "ENM";
BA_ "VNSigAllNodes" SG_ 1259 AllNodesVNA 1;
BA_ "VNSigSLHS_VNReq" SG_ 1259 AllNodesVNA 1;
BA_ "SignalLongName" SG_ 1259 NAHrDisChrgM "Net Amp Hours Discharge Mask";
BA_ "SignalType" SG_ 1259 NAHrDisChrgM "ENM";
BA_ "VNSigAllNodes" SG_ 1259 NAHrDisChrgM 1;
BA_ "SignalLongName" SG_ 1259 NAHrDisChrg "Net Amp Hours Discharge";
BA_ "SignalType" SG_ 1259 NAHrDisChrg "UNM";
BA_ "VNSigAllNodes" SG_ 1259 NAHrDisChrg 1;
BA_ "SignalLongName" SG_ 1259 NAHrChgM "Net Amp Hours Charge Mask";
BA_ "SignalType" SG_ 1259 NAHrChgM "ENM";
BA_ "VNSigAllNodes" SG_ 1259 NAHrChgM 1;
BA_ "SignalLongName" SG_ 1259 NAHrChg "Net Amp Hours Charge";
BA_ "SignalType" SG_ 1259 NAHrChg "UNM";
BA_ "VNSigAllNodes" SG_ 1259 NAHrChg 1;
BA_ "SignalLongName" SG_ 426 EngPstnSnsngOpMode "Engine Position Sensing Operating Mode";
BA_ "SignalType" SG_ 426 EngPstnSnsngOpMode "ENM";
BA_ "VNSigAllNodes" SG_ 426 EngPstnSnsngOpMode 1;
BA_ "SignalLongName" SG_ 426 AuxTransPrsCmndOn "Auxiliary Transmission Pressure Commanded On";
BA_ "SignalType" SG_ 426 AuxTransPrsCmndOn "BLN";
BA_ "VNSigAllNodes" SG_ 426 AuxTransPrsCmndOn 1;
BA_ "SignalLongName" SG_ 426 EVTCS_CmdTrqCapMd "Engine Variable Torque Capacity Status : Commanded Torque Capacity Mode";
BA_ "PacketOrder" SG_ 426 EVTCS_CmdTrqCapMd 2;
BA_ "SignalType" SG_ 426 EVTCS_CmdTrqCapMd "ENM";
BA_ "VNSigAllNodes" SG_ 426 EVTCS_CmdTrqCapMd 1;
BA_ "SignalLongName" SG_ 426 EVTCS_CrntTrqCapMd "Engine Variable Torque Capacity Status : Current Torque Capacity Mode";
BA_ "PacketOrder" SG_ 426 EVTCS_CrntTrqCapMd 1;
BA_ "SignalType" SG_ 426 EVTCS_CrntTrqCapMd "ENM";
BA_ "VNSigAllNodes" SG_ 426 EVTCS_CrntTrqCapMd 1;
BA_ "SignalLongName" SG_ 426 EngPrdctStdyStTorq "Engine Predicted Steady State Torque";
BA_ "SignalType" SG_ 426 EngPrdctStdyStTorq "UNM";
BA_ "VNSigAllNodes" SG_ 426 EngPrdctStdyStTorq 1;
BA_ "SignalLongName" SG_ 426 EngPrdctStdyStTorqV "Engine Predicted Steady State Torque Validity";
BA_ "SignalType" SG_ 426 EngPrdctStdyStTorqV "ENM";
BA_ "VNSigAllNodes" SG_ 426 EngPrdctStdyStTorqV 1;
BA_ "SignalLongName" SG_ 426 CrnkShftTrqMinOffCapV "Crankshaft Torque Minimum Off Capacity Validity";
BA_ "SignalType" SG_ 426 CrnkShftTrqMinOffCapV "ENM";
BA_ "VNSigAllNodes" SG_ 426 CrnkShftTrqMinOffCapV 1;
BA_ "SignalLongName" SG_ 426 CrnkShftTrqMinOffCap "Crankshaft Torque Minimum Off Capacity";
BA_ "SignalType" SG_ 426 CrnkShftTrqMinOffCap "UNM";
BA_ "VNSigAllNodes" SG_ 426 CrnkShftTrqMinOffCap 1;
BA_ "SignalLongName" SG_ 426 CrksftTqMinRunImCapV "Crankshaft Torque Minimum Run Immediate Capacity Validity";
BA_ "SignalType" SG_ 426 CrksftTqMinRunImCapV "ENM";
BA_ "VNSigAllNodes" SG_ 426 CrksftTqMinRunImCapV 1;
BA_ "SignalLongName" SG_ 426 CrksftTqMinRunImCap "Crankshaft Torque Minimum Run Immediate Capacity";
BA_ "SignalType" SG_ 426 CrksftTqMinRunImCap "UNM";
BA_ "VNSigAllNodes" SG_ 426 CrksftTqMinRunImCap 1;
BA_ "SignalLongName" SG_ 1231 DslExhFluidDistTIndcmt "Diesel Exhaust Fluid Distance to Inducement";
BA_ "SignalType" SG_ 1231 DslExhFluidDistTIndcmt "UNM";
BA_ "VNSigAllNodes" SG_ 1231 DslExhFluidDistTIndcmt 1;
BA_ "SignalLongName" SG_ 1231 DslExhFluidLvlPrcntV "Diesel Exhaust Fluid Level Percent Validity";
BA_ "SignalType" SG_ 1231 DslExhFluidLvlPrcntV "ENM";
BA_ "VNSigAllNodes" SG_ 1231 DslExhFluidLvlPrcntV 1;
BA_ "SignalLongName" SG_ 1231 DslExhFluidLvlPrcnt "Diesel Exhaust Fluid Level Percent";
BA_ "SignalType" SG_ 1231 DslExhFluidLvlPrcnt "UNM";
BA_ "VNSigAllNodes" SG_ 1231 DslExhFluidLvlPrcnt 1;
BA_ "SignalLongName" SG_ 723 PerfTrcEngSpdRqStat "Performance Traction Engine Speed Request Status";
BA_ "SignalType" SG_ 723 PerfTrcEngSpdRqStat "ENM";
BA_ "VNSigAllNodes" SG_ 723 PerfTrcEngSpdRqStat 1;
BA_ "SignalLongName" SG_ 723 PerfTrcEngSpdLmtStat "Performance Traction Engine Speed Limiting Status";
BA_ "SignalType" SG_ 723 PerfTrcEngSpdLmtStat "ENM";
BA_ "VNSigAllNodes" SG_ 723 PerfTrcEngSpdLmtStat 1;
BA_ "SignalLongName" SG_ 723 PerfTrcTrqRqStat "Performance Traction Torque Request Status";
BA_ "SignalType" SG_ 723 PerfTrcTrqRqStat "ENM";
BA_ "VNSigAllNodes" SG_ 723 PerfTrcTrqRqStat 1;
BA_ "SignalLongName" SG_ 723 PerfTrcTrqLmtStat "Performance Traction Torque Limiting Status";
BA_ "SignalType" SG_ 723 PerfTrcTrqLmtStat "ENM";
BA_ "VNSigAllNodes" SG_ 723 PerfTrcTrqLmtStat 1;
BA_ "SignalLongName" SG_ 405 EngDistFuelMdDefltd "Engine Distributed Fuel Mode Defaulted";
BA_ "SignalType" SG_ 405 EngDistFuelMdDefltd "BLN";
BA_ "VNSigAllNodes" SG_ 405 EngDistFuelMdDefltd 1;
BA_ "SignalLongName" SG_ 405 EngInjEnbldD "Engine Injector Enabled D";
BA_ "SignalType" SG_ 405 EngInjEnbldD "BLN";
BA_ "VNSigAllNodes" SG_ 405 EngInjEnbldD 1;
BA_ "SignalLongName" SG_ 405 EngInjEnbldC "Engine Injector Enabled C";
BA_ "SignalType" SG_ 405 EngInjEnbldC "BLN";
BA_ "VNSigAllNodes" SG_ 405 EngInjEnbldC 1;
BA_ "SignalLongName" SG_ 405 EngInjEnbldB "Engine Injector Enabled B";
BA_ "SignalType" SG_ 405 EngInjEnbldB "BLN";
BA_ "VNSigAllNodes" SG_ 405 EngInjEnbldB 1;
BA_ "SignalLongName" SG_ 405 EngInjEnbldA "Engine Injector Enabled A";
BA_ "SignalType" SG_ 405 EngInjEnbldA "BLN";
BA_ "VNSigAllNodes" SG_ 405 EngInjEnbldA 1;
BA_ "SignalLongName" SG_ 405 ThrPosV "Throttle Position Validity";
BA_ "SignalType" SG_ 405 ThrPosV "ENM";
BA_ "VNSigAllNodes" SG_ 405 ThrPosV 1;
BA_ "SignalLongName" SG_ 405 ThrPos "Throttle Position";
BA_ "SignalType" SG_ 405 ThrPos "UNM";
BA_ "VNSigAllNodes" SG_ 405 ThrPos 1;
BA_ "SignalLongName" SG_ 405 MassAirFloV "Mass Air Flow Validity";
BA_ "SignalType" SG_ 405 MassAirFloV "ENM";
BA_ "VNSigAllNodes" SG_ 405 MassAirFloV 1;
BA_ "SignalLongName" SG_ 405 MassAirFlo "Mass Air Flow";
BA_ "SignalType" SG_ 405 MassAirFlo "UNM";
BA_ "VNSigAllNodes" SG_ 405 MassAirFlo 1;
BA_ "SignalLongName" SG_ 405 EngManfldAbsPrsERV "Engine Manifold Absolute Pressure Extended Range Validity";
BA_ "SignalType" SG_ 405 EngManfldAbsPrsERV "ENM";
BA_ "VNSigAllNodes" SG_ 405 EngManfldAbsPrsERV 1;
BA_ "SignalLongName" SG_ 405 EngManfldAbsPrsER "Engine Manifold Absolute Pressure Extended Range";
BA_ "SignalType" SG_ 405 EngManfldAbsPrsER "UNM";
BA_ "VNSigAllNodes" SG_ 405 EngManfldAbsPrsER 1;
BA_ "SignalLongName" SG_ 419 EngRunng "Engine Running";
BA_ "SignalType" SG_ 419 EngRunng "BLN";
BA_ "VNSigAllNodes" SG_ 419 EngRunng 1;
BA_ "SignalLongName" SG_ 1223 PropSysOffTmeV "Propulsion System Off Time Validity";
BA_ "SignalType" SG_ 1223 PropSysOffTmeV "ENM";
BA_ "VNSigAllNodes" SG_ 1223 PropSysOffTmeV 1;
BA_ "SignalLongName" SG_ 1223 PropSysOffTmeM "Propulsion System Off Time Mask";
BA_ "SignalType" SG_ 1223 PropSysOffTmeM "ENM";
BA_ "VNSigAllNodes" SG_ 1223 PropSysOffTmeM 1;
BA_ "SignalLongName" SG_ 1223 PropSysOffTme "Propulsion System Off Time";
BA_ "SignalType" SG_ 1223 PropSysOffTme "UNM";
BA_ "VNSigAllNodes" SG_ 1223 PropSysOffTme 1;
BA_ "SignalLongName" SG_ 479 EngAutoStpNotProb "Engine Auto Stop Not Probable";
BA_ "SignalType" SG_ 479 EngAutoStpNotProb "BLN";
BA_ "VNSigAllNodes" SG_ 479 EngAutoStpNotProb 1;
BA_ "GenSigSendType" SG_ 479 EngAutoStpNotProb 10;
BA_ "SignalLongName" SG_ 479 EASSI_UnsdRsrvd2 "Engine Auto Start Stop Information : Unused and Reserved 2";
BA_ "PacketOrder" SG_ 479 EASSI_UnsdRsrvd2 7;
BA_ "SignalType" SG_ 479 EASSI_UnsdRsrvd2 "BLN";
BA_ "VNSigAllNodes" SG_ 479 EASSI_UnsdRsrvd2 1;
BA_ "GenSigSendType" SG_ 479 EASSI_UnsdRsrvd2 10;
BA_ "SignalLongName" SG_ 479 EASSI_StlDetd "Engine Auto Start Stop Information : Stall Detected";
BA_ "PacketOrder" SG_ 479 EASSI_StlDetd 5;
BA_ "SignalType" SG_ 479 EASSI_StlDetd "BLN";
BA_ "VNSigAllNodes" SG_ 479 EASSI_StlDetd 1;
BA_ "GenSigSendType" SG_ 479 EASSI_StlDetd 10;
BA_ "SignalLongName" SG_ 479 EASSI_TrqDetd "Engine Auto Start Stop Information : Torque Detected";
BA_ "PacketOrder" SG_ 479 EASSI_TrqDetd 4;
BA_ "SignalType" SG_ 479 EASSI_TrqDetd "BLN";
BA_ "VNSigAllNodes" SG_ 479 EASSI_TrqDetd 1;
BA_ "GenSigSendType" SG_ 479 EASSI_TrqDetd 10;
BA_ "SignalLongName" SG_ 479 EASSI_FuelReqOn "Engine Auto Start Stop Information : Fuel Requested On";
BA_ "PacketOrder" SG_ 479 EASSI_FuelReqOn 3;
BA_ "SignalType" SG_ 479 EASSI_FuelReqOn "BLN";
BA_ "VNSigAllNodes" SG_ 479 EASSI_FuelReqOn 1;
BA_ "GenSigSendType" SG_ 479 EASSI_FuelReqOn 10;
BA_ "SignalLongName" SG_ 479 EASSI_StrtTyp "Engine Auto Start Stop Information : Start Type";
BA_ "PacketOrder" SG_ 479 EASSI_StrtTyp 2;
BA_ "SignalType" SG_ 479 EASSI_StrtTyp "ENM";
BA_ "VNSigAllNodes" SG_ 479 EASSI_StrtTyp 1;
BA_ "GenSigSendType" SG_ 479 EASSI_StrtTyp 10;
BA_ "SignalLongName" SG_ 479 EASSI_StrtStpSt "Engine Auto Start Stop Information : Start Stop State";
BA_ "PacketOrder" SG_ 479 EASSI_StrtStpSt 1;
BA_ "SignalType" SG_ 479 EASSI_StrtStpSt "ENM";
BA_ "VNSigAllNodes" SG_ 479 EASSI_StrtStpSt 1;
BA_ "GenSigSendType" SG_ 479 EASSI_StrtStpSt 10;
BA_ "SignalLongName" SG_ 479 EASSI_TorqDetdIndet "Engine Auto Start Stop Information : Torque Detected state0805";
BA_ "PacketOrder" SG_ 479 EASSI_TorqDetdIndet 6;
BA_ "SignalType" SG_ 479 EASSI_TorqDetdIndet "BLN";
BA_ "VNSigAllNodes" SG_ 479 EASSI_TorqDetdIndet 1;
BA_ "GenSigSendType" SG_ 479 EASSI_TorqDetdIndet 10;
BA_ "SignalLongName" SG_ 479 ASIRI_Indication08 "Auto Stop Inhibit Reason Indication : Indication 8";
BA_ "PacketOrder" SG_ 479 ASIRI_Indication08 8;
BA_ "SignalType" SG_ 479 ASIRI_Indication08 "BLN";
BA_ "VNSigAllNodes" SG_ 479 ASIRI_Indication08 1;
BA_ "GenSigSendType" SG_ 479 ASIRI_Indication08 10;
BA_ "SignalLongName" SG_ 479 ASIRI_Indication07 "Auto Stop Inhibit Reason Indication : Indication 7";
BA_ "PacketOrder" SG_ 479 ASIRI_Indication07 7;
BA_ "SignalType" SG_ 479 ASIRI_Indication07 "BLN";
BA_ "VNSigAllNodes" SG_ 479 ASIRI_Indication07 1;
BA_ "GenSigSendType" SG_ 479 ASIRI_Indication07 10;
BA_ "SignalLongName" SG_ 479 ASIRI_Indication06 "Auto Stop Inhibit Reason Indication : Indication 6";
BA_ "PacketOrder" SG_ 479 ASIRI_Indication06 6;
BA_ "SignalType" SG_ 479 ASIRI_Indication06 "BLN";
BA_ "VNSigAllNodes" SG_ 479 ASIRI_Indication06 1;
BA_ "GenSigSendType" SG_ 479 ASIRI_Indication06 10;
BA_ "SignalLongName" SG_ 479 ASIRI_Indication05 "Auto Stop Inhibit Reason Indication : Indication 5";
BA_ "PacketOrder" SG_ 479 ASIRI_Indication05 5;
BA_ "SignalType" SG_ 479 ASIRI_Indication05 "BLN";
BA_ "VNSigAllNodes" SG_ 479 ASIRI_Indication05 1;
BA_ "GenSigSendType" SG_ 479 ASIRI_Indication05 10;
BA_ "SignalLongName" SG_ 479 ASIRI_Indication04 "Auto Stop Inhibit Reason Indication : Indication 4";
BA_ "PacketOrder" SG_ 479 ASIRI_Indication04 4;
BA_ "SignalType" SG_ 479 ASIRI_Indication04 "BLN";
BA_ "VNSigAllNodes" SG_ 479 ASIRI_Indication04 1;
BA_ "GenSigSendType" SG_ 479 ASIRI_Indication04 10;
BA_ "SignalLongName" SG_ 479 ASIRI_Indication03 "Auto Stop Inhibit Reason Indication : Indication 3";
BA_ "PacketOrder" SG_ 479 ASIRI_Indication03 3;
BA_ "SignalType" SG_ 479 ASIRI_Indication03 "BLN";
BA_ "VNSigAllNodes" SG_ 479 ASIRI_Indication03 1;
BA_ "GenSigSendType" SG_ 479 ASIRI_Indication03 10;
BA_ "SignalLongName" SG_ 479 ASIRI_Indication02 "Auto Stop Inhibit Reason Indication : Indication 2";
BA_ "PacketOrder" SG_ 479 ASIRI_Indication02 2;
BA_ "SignalType" SG_ 479 ASIRI_Indication02 "BLN";
BA_ "VNSigAllNodes" SG_ 479 ASIRI_Indication02 1;
BA_ "GenSigSendType" SG_ 479 ASIRI_Indication02 10;
BA_ "SignalLongName" SG_ 479 ASIRI_Indication01 "Auto Stop Inhibit Reason Indication : Indication 1";
BA_ "PacketOrder" SG_ 479 ASIRI_Indication01 1;
BA_ "SignalType" SG_ 479 ASIRI_Indication01 "BLN";
BA_ "VNSigAllNodes" SG_ 479 ASIRI_Indication01 1;
BA_ "GenSigSendType" SG_ 479 ASIRI_Indication01 10;
BA_ "SignalLongName" SG_ 479 PTWrmgWtToShftIO "Powertrain Warming Wait To Shift Indication On";
BA_ "SignalType" SG_ 479 PTWrmgWtToShftIO "BLN";
BA_ "VNSigAllNodes" SG_ 479 PTWrmgWtToShftIO 1;
BA_ "SignalLongName" SG_ 479 PrplsnSysAtv "Propulsion System Active";
BA_ "SignalType" SG_ 479 PrplsnSysAtv "BLN";
BA_ "VNSigAllNodes" SG_ 479 PrplsnSysAtv 1;
BA_ "SignalLongName" SG_ 479 PTShftLvrLckRqd "Powertrain Shift Lever Lock Requested";
BA_ "SignalType" SG_ 479 PTShftLvrLckRqd "BLN";
BA_ "VNSigAllNodes" SG_ 479 PTShftLvrLckRqd 1;
BA_ "SignalLongName" SG_ 211 ActAxleTrqV "Actual Axle Torque Validity";
BA_ "SignalType" SG_ 211 ActAxleTrqV "ENM";
BA_ "VNSigAllNodes" SG_ 211 ActAxleTrqV 1;
BA_ "SignalLongName" SG_ 211 ActAxleTrq "Actual Axle Torque";
BA_ "SignalType" SG_ 211 ActAxleTrq "UNM";
BA_ "VNSigAllNodes" SG_ 211 ActAxleTrq 1;
BA_ "SignalLongName" SG_ 1020 OtsAirTmpEmsnsRelV "Outside Air Temperature Emissions Related Validity";
BA_ "SignalType" SG_ 1020 OtsAirTmpEmsnsRelV "ENM";
BA_ "VNSigAllNodes" SG_ 1020 OtsAirTmpEmsnsRelV 1;
BA_ "SignalLongName" SG_ 1020 OtsAirTmpEmsnsRel "Outside Air Temperature Emissions Related";
BA_ "SignalType" SG_ 1020 OtsAirTmpEmsnsRel "UNM";
BA_ "VNSigAllNodes" SG_ 1020 OtsAirTmpEmsnsRel 1;
BA_ "SignalLongName" SG_ 1020 OATEmsnsRelCrValV "Outside Air Temperature Emissions Related Corrected Value Validity";
BA_ "SignalType" SG_ 1020 OATEmsnsRelCrValV "ENM";
BA_ "VNSigAllNodes" SG_ 1020 OATEmsnsRelCrValV 1;
BA_ "SignalLongName" SG_ 1020 OATEmsnsRelCrValM "Outside Air Temperature Emissions Related Corrected Value Mask";
BA_ "SignalType" SG_ 1020 OATEmsnsRelCrValM "ENM";
BA_ "VNSigAllNodes" SG_ 1020 OATEmsnsRelCrValM 1;
BA_ "SignalLongName" SG_ 1020 OATEmsnsRelCrVal "Outside Air Temperature Emissions Related Corrected Value";
BA_ "SignalType" SG_ 1020 OATEmsnsRelCrVal "UNM";
BA_ "VNSigAllNodes" SG_ 1020 OATEmsnsRelCrVal 1;
BA_ "SignalLongName" SG_ 1020 CatlystOutGasTempEstV "Catalyst Outlet Gas Temperature Estimate Validity";
BA_ "SignalType" SG_ 1020 CatlystOutGasTempEstV "ENM";
BA_ "VNSigAllNodes" SG_ 1020 CatlystOutGasTempEstV 1;
BA_ "SignalLongName" SG_ 1020 CatlystOutGasTempEst "Catalyst Outlet Gas Temperature Estimate";
BA_ "SignalType" SG_ 1020 CatlystOutGasTempEst "UNM";
BA_ "VNSigAllNodes" SG_ 1020 CatlystOutGasTempEst 1;
BA_ "SignalLongName" SG_ 1020 OtsAirTmpCrValMsk "Outside Air Temperature Corrected Value Mask";
BA_ "SignalType" SG_ 1020 OtsAirTmpCrValMsk "ENM";
BA_ "VNSigAllNodes" SG_ 1020 OtsAirTmpCrValMsk 1;
BA_ "GenSigSendType" SG_ 1020 OtsAirTmpCrValMsk 10;
BA_ "SignalLongName" SG_ 1020 OtsAirTmpV "Outside Air Temperature Validity";
BA_ "SignalType" SG_ 1020 OtsAirTmpV "ENM";
BA_ "VNSigAllNodes" SG_ 1020 OtsAirTmpV 1;
BA_ "GenSigSendType" SG_ 1020 OtsAirTmpV 10;
BA_ "SignalLongName" SG_ 1020 OtsAirTmpCrValV "Outside Air Temperature Corrected Value Validity";
BA_ "SignalType" SG_ 1020 OtsAirTmpCrValV "ENM";
BA_ "VNSigAllNodes" SG_ 1020 OtsAirTmpCrValV 1;
BA_ "GenSigSendType" SG_ 1020 OtsAirTmpCrValV 10;
BA_ "SignalLongName" SG_ 1020 OtsAirTmpCrVal "Outside Air Temperature Corrected Value";
BA_ "SignalType" SG_ 1020 OtsAirTmpCrVal "UNM";
BA_ "VNSigAllNodes" SG_ 1020 OtsAirTmpCrVal 1;
BA_ "GenSigDeltaValue" SG_ 1020 OtsAirTmpCrVal 1;
BA_ "GenSigSendType" SG_ 1020 OtsAirTmpCrVal 12;
BA_ "GenSigSendOnInit" SG_ 1020 OtsAirTmpCrVal 1;
BA_ "SignalLongName" SG_ 1020 OtsAirTmp "Outside Air Temperature";
BA_ "SignalType" SG_ 1020 OtsAirTmp "UNM";
BA_ "VNSigAllNodes" SG_ 1020 OtsAirTmp 1;
BA_ "GenSigDeltaValue" SG_ 1020 OtsAirTmp 1;
BA_ "GenSigSendType" SG_ 1020 OtsAirTmp 12;
BA_ "GenSigSendOnInit" SG_ 1020 OtsAirTmp 1;
BA_ "SignalLongName" SG_ 1020 EngInltSpcfcHmdtyV "Engine Inlet Specific Humidity Validity";
BA_ "SignalType" SG_ 1020 EngInltSpcfcHmdtyV "ENM";
BA_ "VNSigAllNodes" SG_ 1020 EngInltSpcfcHmdtyV 1;
BA_ "GenSigSendType" SG_ 1020 EngInltSpcfcHmdtyV 10;
BA_ "SignalLongName" SG_ 1020 EngInltSpcfcHmdtyM "Engine Inlet Specific Humidity Mask";
BA_ "SignalType" SG_ 1020 EngInltSpcfcHmdtyM "ENM";
BA_ "VNSigAllNodes" SG_ 1020 EngInltSpcfcHmdtyM 1;
BA_ "GenSigSendType" SG_ 1020 EngInltSpcfcHmdtyM 10;
BA_ "SignalLongName" SG_ 1020 EngInltSpcfcHmdty "Engine Inlet Specific Humidity";
BA_ "SignalType" SG_ 1020 EngInltSpcfcHmdty "UNM";
BA_ "VNSigAllNodes" SG_ 1020 EngInltSpcfcHmdty 1;
BA_ "GenSigDeltaValue" SG_ 1020 EngInltSpcfcHmdty 1;
BA_ "GenSigSendType" SG_ 1020 EngInltSpcfcHmdty 12;
BA_REL_ "GenSigTimeoutTime" BU_SG_REL_ CGM_HS SG_ 197 WRSLNDWhlDisTpRC 250;
BA_REL_ "GenSigTimeoutMsg" BU_SG_REL_ CGM_HS SG_ 197 WRSLNDWhlDisTpRC 197;
BA_REL_ "GenSigSuprvResp" BU_SG_REL_ CGM_HS SG_ 197 WRSLNDWhlDisTpRC 1;
BA_REL_ "GenSigTimeoutTime" BU_SG_REL_ HMIM_HS SG_ 197 WRSLNDWhlDisTpRC 250;
BA_REL_ "GenSigTimeoutMsg" BU_SG_REL_ HMIM_HS SG_ 197 WRSLNDWhlDisTpRC 197;
BA_REL_ "GenSigSuprvResp" BU_SG_REL_ HMIM_HS SG_ 197 WRSLNDWhlDisTpRC 1;
BA_REL_ "GenSigTimeoutTime" BU_SG_REL_ TCCM_HS SG_ 197 WRSLNDWhlDisTpRC 25;
BA_REL_ "GenSigTimeoutMsg" BU_SG_REL_ TCCM_HS SG_ 197 WRSLNDWhlDisTpRC 197;
BA_REL_ "GenSigSuprvResp" BU_SG_REL_ TCCM_HS SG_ 197 WRSLNDWhlDisTpRC 1;
BA_REL_ "GenSigTimeoutTime" BU_SG_REL_ BCM_HS SG_ 197 WRSLNDWhlDisTpRC 250;
BA_REL_ "GenSigTimeoutMsg" BU_SG_REL_ BCM_HS SG_ 197 WRSLNDWhlDisTpRC 197;
BA_REL_ "GenSigSuprvResp" BU_SG_REL_ BCM_HS SG_ 197 WRSLNDWhlDisTpRC 1;
BA_REL_ "GenSigTimeoutTime" BU_SG_REL_ CGM_HS SG_ 197 WRSLNDWhlRotStRst 250;
BA_REL_ "GenSigTimeoutMsg" BU_SG_REL_ CGM_HS SG_ 197 WRSLNDWhlRotStRst 197;
BA_REL_ "GenSigSuprvResp" BU_SG_REL_ CGM_HS SG_ 197 WRSLNDWhlRotStRst 1;
BA_REL_ "GenSigTimeoutTime" BU_SG_REL_ HMIM_HS SG_ 197 WRSLNDWhlRotStRst 250;
BA_REL_ "GenSigTimeoutMsg" BU_SG_REL_ HMIM_HS SG_ 197 WRSLNDWhlRotStRst 197;
BA_REL_ "GenSigSuprvResp" BU_SG_REL_ HMIM_HS SG_ 197 WRSLNDWhlRotStRst 1;
BA_REL_ "GenSigTimeoutTime" BU_SG_REL_ TCCM_HS SG_ 197 WRSLNDWhlRotStRst 25;
BA_REL_ "GenSigTimeoutMsg" BU_SG_REL_ TCCM_HS SG_ 197 WRSLNDWhlRotStRst 197;
BA_REL_ "GenSigSuprvResp" BU_SG_REL_ TCCM_HS SG_ 197 WRSLNDWhlRotStRst 1;
BA_REL_ "GenSigTimeoutTime" BU_SG_REL_ BCM_HS SG_ 197 WRSLNDWhlRotStRst 250;
BA_REL_ "GenSigTimeoutMsg" BU_SG_REL_ BCM_HS SG_ 197 WRSLNDWhlRotStRst 197;
BA_REL_ "GenSigSuprvResp" BU_SG_REL_ BCM_HS SG_ 197 WRSLNDWhlRotStRst 1;
BA_REL_ "GenSigTimeoutTime" BU_SG_REL_ CGM_HS SG_ 197 WRSLNDWhlDistVal 250;
BA_REL_ "GenSigTimeoutMsg" BU_SG_REL_ CGM_HS SG_ 197 WRSLNDWhlDistVal 197;
BA_REL_ "GenSigSuprvResp" BU_SG_REL_ CGM_HS SG_ 197 WRSLNDWhlDistVal 1;
BA_REL_ "GenSigTimeoutTime" BU_SG_REL_ HMIM_HS SG_ 197 WRSLNDWhlDistVal 250;
BA_REL_ "GenSigTimeoutMsg" BU_SG_REL_ HMIM_HS SG_ 197 WRSLNDWhlDistVal 197;
BA_REL_ "GenSigSuprvResp" BU_SG_REL_ HMIM_HS SG_ 197 WRSLNDWhlDistVal 1;
BA_REL_ "GenSigTimeoutTime" BU_SG_REL_ TCCM_HS SG_ 197 WRSLNDWhlDistVal 25;
BA_REL_ "GenSigTimeoutMsg" BU_SG_REL_ TCCM_HS SG_ 197 WRSLNDWhlDistVal 197;
BA_REL_ "GenSigSuprvResp" BU_SG_REL_ TCCM_HS SG_ 197 WRSLNDWhlDistVal 1;
BA_REL_ "GenSigTimeoutTime" BU_SG_REL_ BCM_HS SG_ 197 WRSLNDWhlDistVal 250;
BA_REL_ "GenSigTimeoutMsg" BU_SG_REL_ BCM_HS SG_ 197 WRSLNDWhlDistVal 197;
BA_REL_ "GenSigSuprvResp" BU_SG_REL_ BCM_HS SG_ 197 WRSLNDWhlDistVal 1;
BA_REL_ "GenSigTimeoutTime" BU_SG_REL_ CGM_HS SG_ 197 WRSLNDWhlDistTstm 250;
BA_REL_ "GenSigTimeoutMsg" BU_SG_REL_ CGM_HS SG_ 197 WRSLNDWhlDistTstm 197;
BA_REL_ "GenSigSuprvResp" BU_SG_REL_ CGM_HS SG_ 197 WRSLNDWhlDistTstm 1;
BA_REL_ "GenSigTimeoutTime" BU_SG_REL_ HMIM_HS SG_ 197 WRSLNDWhlDistTstm 250;
BA_REL_ "GenSigTimeoutMsg" BU_SG_REL_ HMIM_HS SG_ 197 WRSLNDWhlDistTstm 197;
BA_REL_ "GenSigSuprvResp" BU_SG_REL_ HMIM_HS SG_ 197 WRSLNDWhlDistTstm 1;
BA_REL_ "GenSigTimeoutTime" BU_SG_REL_ TCCM_HS SG_ 197 WRSLNDWhlDistTstm 25;
BA_REL_ "GenSigTimeoutMsg" BU_SG_REL_ TCCM_HS SG_ 197 WRSLNDWhlDistTstm 197;
BA_REL_ "GenSigSuprvResp" BU_SG_REL_ TCCM_HS SG_ 197 WRSLNDWhlDistTstm 1;
BA_REL_ "GenSigTimeoutTime" BU_SG_REL_ BCM_HS SG_ 197 WRSLNDWhlDistTstm 250;
BA_REL_ "GenSigTimeoutMsg" BU_SG_REL_ BCM_HS SG_ 197 WRSLNDWhlDistTstm 197;
BA_REL_ "GenSigSuprvResp" BU_SG_REL_ BCM_HS SG_ 197 WRSLNDWhlDistTstm 1;
BA_REL_ "GenSigTimeoutTime" BU_SG_REL_ CGM_HS SG_ 197 WRSLNDWhlDistPCntr 250;
BA_REL_ "GenSigTimeoutMsg" BU_SG_REL_ CGM_HS SG_ 197 WRSLNDWhlDistPCntr 197;
BA_REL_ "GenSigSuprvResp" BU_SG_REL_ CGM_HS SG_ 197 WRSLNDWhlDistPCntr 1;
BA_REL_ "GenSigTimeoutTime" BU_SG_REL_ HMIM_HS SG_ 197 WRSLNDWhlDistPCntr 250;
BA_REL_ "GenSigTimeoutMsg" BU_SG_REL_ HMIM_HS SG_ 197 WRSLNDWhlDistPCntr 197;
BA_REL_ "GenSigSuprvResp" BU_SG_REL_ HMIM_HS SG_ 197 WRSLNDWhlDistPCntr 1;
BA_REL_ "GenSigTimeoutTime" BU_SG_REL_ TCCM_HS SG_ 197 WRSLNDWhlDistPCntr 25;
BA_REL_ "GenSigTimeoutMsg" BU_SG_REL_ TCCM_HS SG_ 197 WRSLNDWhlDistPCntr 197;
BA_REL_ "GenSigSuprvResp" BU_SG_REL_ TCCM_HS SG_ 197 WRSLNDWhlDistPCntr 1;
BA_REL_ "GenSigTimeoutTime" BU_SG_REL_ BCM_HS SG_ 197 WRSLNDWhlDistPCntr 250;
BA_REL_ "GenSigTimeoutMsg" BU_SG_REL_ BCM_HS SG_ 197 WRSLNDWhlDistPCntr 197;
BA_REL_ "GenSigSuprvResp" BU_SG_REL_ BCM_HS SG_ 197 WRSLNDWhlDistPCntr 1;
BA_REL_ "GenSigTimeoutTime" BU_SG_REL_ CGM_HS SG_ 197 WRSLNDSeqNum 250;
BA_REL_ "GenSigTimeoutMsg" BU_SG_REL_ CGM_HS SG_ 197 WRSLNDSeqNum 197;
BA_REL_ "GenSigSuprvResp" BU_SG_REL_ CGM_HS SG_ 197 WRSLNDSeqNum 1;
BA_REL_ "GenSigTimeoutTime" BU_SG_REL_ HMIM_HS SG_ 197 WRSLNDSeqNum 250;
BA_REL_ "GenSigTimeoutMsg" BU_SG_REL_ HMIM_HS SG_ 197 WRSLNDSeqNum 197;
BA_REL_ "GenSigSuprvResp" BU_SG_REL_ HMIM_HS SG_ 197 WRSLNDSeqNum 1;
BA_REL_ "GenSigTimeoutTime" BU_SG_REL_ TCCM_HS SG_ 197 WRSLNDSeqNum 25;
BA_REL_ "GenSigTimeoutMsg" BU_SG_REL_ TCCM_HS SG_ 197 WRSLNDSeqNum 197;
BA_REL_ "GenSigSuprvResp" BU_SG_REL_ TCCM_HS SG_ 197 WRSLNDSeqNum 1;
BA_REL_ "GenSigTimeoutTime" BU_SG_REL_ BCM_HS SG_ 197 WRSLNDSeqNum 250;
BA_REL_ "GenSigTimeoutMsg" BU_SG_REL_ BCM_HS SG_ 197 WRSLNDSeqNum 197;
BA_REL_ "GenSigSuprvResp" BU_SG_REL_ BCM_HS SG_ 197 WRSLNDSeqNum 1;
BA_REL_ "GenSigTimeoutTime" BU_SG_REL_ CGM_HS SG_ 197 WRSRNDWhlDisTpRC 250;
BA_REL_ "GenSigTimeoutMsg" BU_SG_REL_ CGM_HS SG_ 197 WRSRNDWhlDisTpRC 197;
BA_REL_ "GenSigSuprvResp" BU_SG_REL_ CGM_HS SG_ 197 WRSRNDWhlDisTpRC 1;
BA_REL_ "GenSigTimeoutTime" BU_SG_REL_ TCCM_HS SG_ 197 WRSRNDWhlDisTpRC 25;
BA_REL_ "GenSigTimeoutMsg" BU_SG_REL_ TCCM_HS SG_ 197 WRSRNDWhlDisTpRC 197;
BA_REL_ "GenSigSuprvResp" BU_SG_REL_ TCCM_HS SG_ 197 WRSRNDWhlDisTpRC 1;
BA_REL_ "GenSigTimeoutTime" BU_SG_REL_ BCM_HS SG_ 197 WRSRNDWhlDisTpRC 250;
BA_REL_ "GenSigTimeoutMsg" BU_SG_REL_ BCM_HS SG_ 197 WRSRNDWhlDisTpRC 197;
BA_REL_ "GenSigSuprvResp" BU_SG_REL_ BCM_HS SG_ 197 WRSRNDWhlDisTpRC 1;
BA_REL_ "GenSigTimeoutTime" BU_SG_REL_ CGM_HS SG_ 197 WRSRNDWhlRotStRst 250;
BA_REL_ "GenSigTimeoutMsg" BU_SG_REL_ CGM_HS SG_ 197 WRSRNDWhlRotStRst 197;
BA_REL_ "GenSigSuprvResp" BU_SG_REL_ CGM_HS SG_ 197 WRSRNDWhlRotStRst 1;
BA_REL_ "GenSigTimeoutTime" BU_SG_REL_ TCCM_HS SG_ 197 WRSRNDWhlRotStRst 25;
BA_REL_ "GenSigTimeoutMsg" BU_SG_REL_ TCCM_HS SG_ 197 WRSRNDWhlRotStRst 197;
BA_REL_ "GenSigSuprvResp" BU_SG_REL_ TCCM_HS SG_ 197 WRSRNDWhlRotStRst 1;
BA_REL_ "GenSigTimeoutTime" BU_SG_REL_ BCM_HS SG_ 197 WRSRNDWhlRotStRst 250;
BA_REL_ "GenSigTimeoutMsg" BU_SG_REL_ BCM_HS SG_ 197 WRSRNDWhlRotStRst 197;
BA_REL_ "GenSigSuprvResp" BU_SG_REL_ BCM_HS SG_ 197 WRSRNDWhlRotStRst 1;
BA_REL_ "GenSigTimeoutTime" BU_SG_REL_ CGM_HS SG_ 197 WRSRNDWhlDistVal 250;
BA_REL_ "GenSigTimeoutMsg" BU_SG_REL_ CGM_HS SG_ 197 WRSRNDWhlDistVal 197;
BA_REL_ "GenSigSuprvResp" BU_SG_REL_ CGM_HS SG_ 197 WRSRNDWhlDistVal 1;
BA_REL_ "GenSigTimeoutTime" BU_SG_REL_ TCCM_HS SG_ 197 WRSRNDWhlDistVal 25;
BA_REL_ "GenSigTimeoutMsg" BU_SG_REL_ TCCM_HS SG_ 197 WRSRNDWhlDistVal 197;
BA_REL_ "GenSigSuprvResp" BU_SG_REL_ TCCM_HS SG_ 197 WRSRNDWhlDistVal 1;
BA_REL_ "GenSigTimeoutTime" BU_SG_REL_ BCM_HS SG_ 197 WRSRNDWhlDistVal 250;
BA_REL_ "GenSigTimeoutMsg" BU_SG_REL_ BCM_HS SG_ 197 WRSRNDWhlDistVal 197;
BA_REL_ "GenSigSuprvResp" BU_SG_REL_ BCM_HS SG_ 197 WRSRNDWhlDistVal 1;
BA_REL_ "GenSigTimeoutTime" BU_SG_REL_ CGM_HS SG_ 197 WRSRNDWhlDistTstm 250;
BA_REL_ "GenSigTimeoutMsg" BU_SG_REL_ CGM_HS SG_ 197 WRSRNDWhlDistTstm 197;
BA_REL_ "GenSigSuprvResp" BU_SG_REL_ CGM_HS SG_ 197 WRSRNDWhlDistTstm 1;
BA_REL_ "GenSigTimeoutTime" BU_SG_REL_ TCCM_HS SG_ 197 WRSRNDWhlDistTstm 25;
BA_REL_ "GenSigTimeoutMsg" BU_SG_REL_ TCCM_HS SG_ 197 WRSRNDWhlDistTstm 197;
BA_REL_ "GenSigSuprvResp" BU_SG_REL_ TCCM_HS SG_ 197 WRSRNDWhlDistTstm 1;
BA_REL_ "GenSigTimeoutTime" BU_SG_REL_ BCM_HS SG_ 197 WRSRNDWhlDistTstm 250;
BA_REL_ "GenSigTimeoutMsg" BU_SG_REL_ BCM_HS SG_ 197 WRSRNDWhlDistTstm 197;
BA_REL_ "GenSigSuprvResp" BU_SG_REL_ BCM_HS SG_ 197 WRSRNDWhlDistTstm 1;
BA_REL_ "GenSigTimeoutTime" BU_SG_REL_ CGM_HS SG_ 197 WRSRNDWhlDistPCntr 250;
BA_REL_ "GenSigTimeoutMsg" BU_SG_REL_ CGM_HS SG_ 197 WRSRNDWhlDistPCntr 197;
BA_REL_ "GenSigSuprvResp" BU_SG_REL_ CGM_HS SG_ 197 WRSRNDWhlDistPCntr 1;
BA_REL_ "GenSigTimeoutTime" BU_SG_REL_ TCCM_HS SG_ 197 WRSRNDWhlDistPCntr 25;
BA_REL_ "GenSigTimeoutMsg" BU_SG_REL_ TCCM_HS SG_ 197 WRSRNDWhlDistPCntr 197;
BA_REL_ "GenSigSuprvResp" BU_SG_REL_ TCCM_HS SG_ 197 WRSRNDWhlDistPCntr 1;
BA_REL_ "GenSigTimeoutTime" BU_SG_REL_ BCM_HS SG_ 197 WRSRNDWhlDistPCntr 250;
BA_REL_ "GenSigTimeoutMsg" BU_SG_REL_ BCM_HS SG_ 197 WRSRNDWhlDistPCntr 197;
BA_REL_ "GenSigSuprvResp" BU_SG_REL_ BCM_HS SG_ 197 WRSRNDWhlDistPCntr 1;
BA_REL_ "GenSigTimeoutTime" BU_SG_REL_ CGM_HS SG_ 197 WRSRNDSeqNum 250;
BA_REL_ "GenSigTimeoutMsg" BU_SG_REL_ CGM_HS SG_ 197 WRSRNDSeqNum 197;
BA_REL_ "GenSigSuprvResp" BU_SG_REL_ CGM_HS SG_ 197 WRSRNDSeqNum 1;
BA_REL_ "GenSigTimeoutTime" BU_SG_REL_ TCCM_HS SG_ 197 WRSRNDSeqNum 25;
BA_REL_ "GenSigTimeoutMsg" BU_SG_REL_ TCCM_HS SG_ 197 WRSRNDSeqNum 197;
BA_REL_ "GenSigSuprvResp" BU_SG_REL_ TCCM_HS SG_ 197 WRSRNDSeqNum 1;
BA_REL_ "GenSigTimeoutTime" BU_SG_REL_ BCM_HS SG_ 197 WRSRNDSeqNum 250;
BA_REL_ "GenSigTimeoutMsg" BU_SG_REL_ BCM_HS SG_ 197 WRSRNDSeqNum 197;
BA_REL_ "GenSigSuprvResp" BU_SG_REL_ BCM_HS SG_ 197 WRSRNDSeqNum 1;
BA_REL_ "GenSigTimeoutTime" BU_SG_REL_ EBCM_OBD_HS SG_ 1009 EngOffTmVDA 625;
BA_REL_ "GenSigTimeoutMsg" BU_SG_REL_ EBCM_OBD_HS SG_ 1009 EngOffTmVDA 1009;
BA_REL_ "GenSigSuprvResp" BU_SG_REL_ EBCM_OBD_HS SG_ 1009 EngOffTmVDA 1;
BA_REL_ "GenSigTimeoutTime" BU_SG_REL_ EBCM_HS SG_ 1009 EngOffTmVDA 625;
BA_REL_ "GenSigTimeoutMsg" BU_SG_REL_ EBCM_HS SG_ 1009 EngOffTmVDA 1009;
BA_REL_ "GenSigSuprvResp" BU_SG_REL_ EBCM_HS SG_ 1009 EngOffTmVDA 1;
BA_REL_ "GenSigTimeoutTime" BU_SG_REL_ TCCM_HS SG_ 1009 IntDimDspLvl 625;
BA_REL_ "GenSigTimeoutMsg" BU_SG_REL_ TCCM_HS SG_ 1009 IntDimDspLvl 1009;
BA_REL_ "GenSigSuprvResp" BU_SG_REL_ TCCM_HS SG_ 1009 IntDimDspLvl 1;
BA_REL_ "GenSigTimeoutTime" BU_SG_REL_ ECM_HS SG_ 1009 RstrctdPTOpModeReqd 625;
BA_REL_ "GenSigTimeoutMsg" BU_SG_REL_ ECM_HS SG_ 1009 RstrctdPTOpModeReqd 1009;
BA_REL_ "GenSigSuprvResp" BU_SG_REL_ ECM_HS SG_ 1009 RstrctdPTOpModeReqd 1;
BA_REL_ "GenSigTimeoutTime" BU_SG_REL_ ECM_HS SG_ 1009 ClmtCtrlHtrEngRunRq 625;
BA_REL_ "GenSigTimeoutMsg" BU_SG_REL_ ECM_HS SG_ 1009 ClmtCtrlHtrEngRunRq 1009;
BA_REL_ "GenSigSuprvResp" BU_SG_REL_ ECM_HS SG_ 1009 ClmtCtrlHtrEngRunRq 1;
BA_REL_ "GenSigRxStartValue" BU_SG_REL_ ECM_HS SG_ 1009 OutAirTempVDA "$1 - Virtual Device Available";
BA_REL_ "GenSigTimeoutTime" BU_SG_REL_ ICCM_OBD_HS SG_ 1009 OtsAirTmpCrVal 625;
BA_REL_ "GenSigTimeoutMsg" BU_SG_REL_ ICCM_OBD_HS SG_ 1009 OtsAirTmpCrVal 1009;
BA_REL_ "GenSigVBitResp" BU_SG_REL_ ICCM_OBD_HS SG_ 1009 OtsAirTmpCrVal 1;
BA_REL_ "GenSigVDAFailComment" BU_SG_REL_ ICCM_OBD_HS SG_ 1009 OtsAirTmpCrVal "Outside Air Temperature Virtual Device Availability";
BA_REL_ "GenSigVDAFailResp" BU_SG_REL_ ICCM_OBD_HS SG_ 1009 OtsAirTmpCrVal 1;
BA_REL_ "GenSigSuprvResp" BU_SG_REL_ ICCM_OBD_HS SG_ 1009 OtsAirTmpCrVal 1;
BA_REL_ "GenSigTimeoutTime" BU_SG_REL_ ICCM_HS SG_ 1009 OtsAirTmpCrVal 625;
BA_REL_ "GenSigTimeoutMsg" BU_SG_REL_ ICCM_HS SG_ 1009 OtsAirTmpCrVal 1009;
BA_REL_ "GenSigVBitResp" BU_SG_REL_ ICCM_HS SG_ 1009 OtsAirTmpCrVal 1;
BA_REL_ "GenSigVDAFailComment" BU_SG_REL_ ICCM_HS SG_ 1009 OtsAirTmpCrVal "Outside Air Temperature Virtual Device Availability";
BA_REL_ "GenSigVDAFailResp" BU_SG_REL_ ICCM_HS SG_ 1009 OtsAirTmpCrVal 1;
BA_REL_ "GenSigSuprvResp" BU_SG_REL_ ICCM_HS SG_ 1009 OtsAirTmpCrVal 1;
BA_REL_ "GenSigTimeoutTime" BU_SG_REL_ EPS_HS SG_ 1009 OtsAirTmpCrVal 625;
BA_REL_ "GenSigTimeoutMsg" BU_SG_REL_ EPS_HS SG_ 1009 OtsAirTmpCrVal 1009;
BA_REL_ "GenSigSuprvResp" BU_SG_REL_ EPS_HS SG_ 1009 OtsAirTmpCrVal 1;
BA_REL_ "GenSigTimeoutTime" BU_SG_REL_ EBCM_OBD_HS SG_ 1009 OtsAirTmpCrVal 625;
BA_REL_ "GenSigTimeoutMsg" BU_SG_REL_ EBCM_OBD_HS SG_ 1009 OtsAirTmpCrVal 1009;
BA_REL_ "GenSigSuprvResp" BU_SG_REL_ EBCM_OBD_HS SG_ 1009 OtsAirTmpCrVal 1;
BA_REL_ "GenSigTimeoutTime" BU_SG_REL_ EBCM_HS SG_ 1009 OtsAirTmpCrVal 625;
BA_REL_ "GenSigTimeoutMsg" BU_SG_REL_ EBCM_HS SG_ 1009 OtsAirTmpCrVal 1009;
BA_REL_ "GenSigSuprvResp" BU_SG_REL_ EBCM_HS SG_ 1009 OtsAirTmpCrVal 1;
BA_REL_ "GenSigTimeoutTime" BU_SG_REL_ ECM_HS SG_ 1009 PF_MinIdlBstLvlReq 625;
BA_REL_ "GenSigTimeoutMsg" BU_SG_REL_ ECM_HS SG_ 1009 PF_MinIdlBstLvlReq 1009;
BA_REL_ "GenSigRxStartValue" BU_SG_REL_ ECM_HS SG_ 1009 PF_MinIdlBstLvlReq "$0 - No Boost Requested";
BA_REL_ "GenSigSuprvResp" BU_SG_REL_ ECM_HS SG_ 1009 PF_MinIdlBstLvlReq 1;
BA_REL_ "GenSigTimeoutTime" BU_SG_REL_ ECM_HS SG_ 1009 VehTopSpdLmtReq 625;
BA_REL_ "GenSigTimeoutMsg" BU_SG_REL_ ECM_HS SG_ 1009 VehTopSpdLmtReq 1009;
BA_REL_ "GenSigSuprvResp" BU_SG_REL_ ECM_HS SG_ 1009 VehTopSpdLmtReq 1;
BA_REL_ "GenSigTimeoutTime" BU_SG_REL_ TCCM_HS SG_ 1257 ABSPr 2500;
BA_REL_ "GenSigTimeoutMsg" BU_SG_REL_ TCCM_HS SG_ 1257 ABSPr 1257;
BA_REL_ "GenSigSuprvResp" BU_SG_REL_ TCCM_HS SG_ 1257 ABSPr 1;
BA_REL_ "GenSigTimeoutTime" BU_SG_REL_ BCM_HS SG_ 505 AllNodesVNA_1F9 250;
BA_REL_ "GenSigTimeoutMsg" BU_SG_REL_ BCM_HS SG_ 505 AllNodesVNA_1F9 505;
BA_REL_ "GenSigSuprvResp" BU_SG_REL_ BCM_HS SG_ 505 AllNodesVNA_1F9 1;
BA_REL_ "GenSigTimeoutTime" BU_SG_REL_ BCM_HS SG_ 505 PTOVehTopSpdLimVal 250;
BA_REL_ "GenSigTimeoutMsg" BU_SG_REL_ BCM_HS SG_ 505 PTOVehTopSpdLimVal 505;
BA_REL_ "GenSigSuprvResp" BU_SG_REL_ BCM_HS SG_ 505 PTOVehTopSpdLimVal 1;
BA_REL_ "GenSigTimeoutTime" BU_SG_REL_ ECM_HS SG_ 505 AccPdlPwrTkOffOvrAct 75;
BA_REL_ "GenSigTimeoutMsg" BU_SG_REL_ ECM_HS SG_ 505 AccPdlPwrTkOffOvrAct 505;
BA_REL_ "GenSigRxStartValue" BU_SG_REL_ ECM_HS SG_ 505 AccPdlPwrTkOffOvrAct "False";
BA_REL_ "GenSigSuprvResp" BU_SG_REL_ ECM_HS SG_ 505 AccPdlPwrTkOffOvrAct 1;
BA_REL_ "GenSigRxStartValue" BU_SG_REL_ ECM_HS SG_ 505 FstIdlMdAct "False";
BA_REL_ "GenSigTimeoutTime" BU_SG_REL_ EBCM_OBD_HS SG_ 505 PTOMdAct 250;
BA_REL_ "GenSigTimeoutMsg" BU_SG_REL_ EBCM_OBD_HS SG_ 505 PTOMdAct 505;
BA_REL_ "GenSigSuprvResp" BU_SG_REL_ EBCM_OBD_HS SG_ 505 PTOMdAct 1;
BA_REL_ "GenSigTimeoutTime" BU_SG_REL_ EBCM_HS SG_ 505 PTOMdAct 250;
BA_REL_ "GenSigTimeoutMsg" BU_SG_REL_ EBCM_HS SG_ 505 PTOMdAct 505;
BA_REL_ "GenSigSuprvResp" BU_SG_REL_ EBCM_HS SG_ 505 PTOMdAct 1;
BA_REL_ "GenSigRxStartValue" BU_SG_REL_ ECM_HS SG_ 505 PTOMdAct "False";
BA_REL_ "GenSigRxStartValue" BU_SG_REL_ ECM_HS SG_ 505 PTOEngTrqLmtRchd "False";
BA_REL_ "GenSigRxStartValue" BU_SG_REL_ ECM_HS SG_ 505 PTOEngTrqLmtValER "2040 Nm";
BA_REL_ "GenSigTimeoutTime" BU_SG_REL_ EBCM_OBD_HS SG_ 505 PltfrmEngSpdCmdMdAct 250;
BA_REL_ "GenSigTimeoutMsg" BU_SG_REL_ EBCM_OBD_HS SG_ 505 PltfrmEngSpdCmdMdAct 505;
BA_REL_ "GenSigSuprvResp" BU_SG_REL_ EBCM_OBD_HS SG_ 505 PltfrmEngSpdCmdMdAct 1;
BA_REL_ "GenSigRxStartValue" BU_SG_REL_ TCM_HS SG_ 505 PltfrmEngSpdCmdMdAct "False";
BA_REL_ "GenSigTimeoutTime" BU_SG_REL_ EBCM_HS SG_ 505 PltfrmEngSpdCmdMdAct 250;
BA_REL_ "GenSigTimeoutMsg" BU_SG_REL_ EBCM_HS SG_ 505 PltfrmEngSpdCmdMdAct 505;
BA_REL_ "GenSigSuprvResp" BU_SG_REL_ EBCM_HS SG_ 505 PltfrmEngSpdCmdMdAct 1;
BA_REL_ "GenSigRxStartValue" BU_SG_REL_ ECM_HS SG_ 505 PltfrmEngSpdCmdMdAct "False";
BA_REL_ "GenSigTimeoutTime" BU_SG_REL_ EBCM_OBD_HS SG_ 505 PltfrmEngSpdReq 250;
BA_REL_ "GenSigTimeoutMsg" BU_SG_REL_ EBCM_OBD_HS SG_ 505 PltfrmEngSpdReq 505;
BA_REL_ "GenSigSuprvResp" BU_SG_REL_ EBCM_OBD_HS SG_ 505 PltfrmEngSpdReq 1;
BA_REL_ "GenSigRxStartValue" BU_SG_REL_ TCM_HS SG_ 505 PltfrmEngSpdReq "0 RPM";
BA_REL_ "GenSigTimeoutTime" BU_SG_REL_ EBCM_HS SG_ 505 PltfrmEngSpdReq 250;
BA_REL_ "GenSigTimeoutMsg" BU_SG_REL_ EBCM_HS SG_ 505 PltfrmEngSpdReq 505;
BA_REL_ "GenSigSuprvResp" BU_SG_REL_ EBCM_HS SG_ 505 PltfrmEngSpdReq 1;
BA_REL_ "GenSigRxStartValue" BU_SG_REL_ ECM_HS SG_ 505 PltfrmEngSpdReq "0 RPM";
BA_REL_ "GenSigRxStartValue" BU_SG_REL_ ECM_HS SG_ 505 PFESpdCmdOnSwAct "False";
BA_REL_ "GenSigRxStartValue" BU_SG_REL_ ECM_HS SG_ 505 PFESpdCmdDeSwAct "False";
BA_REL_ "GenSigRxStartValue" BU_SG_REL_ ECM_HS SG_ 505 PFESpdCmdInSwAct "False";
BA_REL_ "GenSigRxStartValue" BU_SG_REL_ ECM_HS SG_ 505 PFESpdCmdSwDIntg "$1 - Data Invalid";
BA_REL_ "GenSigTimeoutTime" BU_SG_REL_ EBCM_OBD_HS SG_ 505 PFEngSpdCmdAlvRlgCnt 250;
BA_REL_ "GenSigTimeoutMsg" BU_SG_REL_ EBCM_OBD_HS SG_ 505 PFEngSpdCmdAlvRlgCnt 505;
BA_REL_ "GenSigSuprvResp" BU_SG_REL_ EBCM_OBD_HS SG_ 505 PFEngSpdCmdAlvRlgCnt 1;
BA_REL_ "GenSigTimeoutTime" BU_SG_REL_ EBCM_HS SG_ 505 PFEngSpdCmdAlvRlgCnt 250;
BA_REL_ "GenSigTimeoutMsg" BU_SG_REL_ EBCM_HS SG_ 505 PFEngSpdCmdAlvRlgCnt 505;
BA_REL_ "GenSigSuprvResp" BU_SG_REL_ EBCM_HS SG_ 505 PFEngSpdCmdAlvRlgCnt 1;
BA_REL_ "GenSigTimeoutTime" BU_SG_REL_ EBCM_OBD_HS SG_ 505 PltfrmEngSpdCmdProtVal 250;
BA_REL_ "GenSigTimeoutMsg" BU_SG_REL_ EBCM_OBD_HS SG_ 505 PltfrmEngSpdCmdProtVal 505;
BA_REL_ "GenSigSuprvResp" BU_SG_REL_ EBCM_OBD_HS SG_ 505 PltfrmEngSpdCmdProtVal 1;
BA_REL_ "GenSigTimeoutTime" BU_SG_REL_ EBCM_HS SG_ 505 PltfrmEngSpdCmdProtVal 250;
BA_REL_ "GenSigTimeoutMsg" BU_SG_REL_ EBCM_HS SG_ 505 PltfrmEngSpdCmdProtVal 505;
BA_REL_ "GenSigSuprvResp" BU_SG_REL_ EBCM_HS SG_ 505 PltfrmEngSpdCmdProtVal 1;
BA_REL_ "GenSigTimeoutTime" BU_SG_REL_ BCM_HS SG_ 505 PTORmtEngShtdwnReqd 250;
BA_REL_ "GenSigTimeoutMsg" BU_SG_REL_ BCM_HS SG_ 505 PTORmtEngShtdwnReqd 505;
BA_REL_ "GenSigSuprvRespSubValue" BU_SG_REL_ BCM_HS SG_ 505 PTORmtEngShtdwnReqd 1;
BA_REL_ "GenSigSuprvResp" BU_SG_REL_ BCM_HS SG_ 505 PTORmtEngShtdwnReqd 2;
BA_REL_ "GenSigTimeoutTime" BU_SG_REL_ ECM_HS SG_ 505 PTORmtEngShtdwnReqd 75;
BA_REL_ "GenSigTimeoutMsg" BU_SG_REL_ ECM_HS SG_ 505 PTORmtEngShtdwnReqd 505;
BA_REL_ "GenSigRxStartValue" BU_SG_REL_ ECM_HS SG_ 505 PTORmtEngShtdwnReqd "False";
BA_REL_ "GenSigSuprvResp" BU_SG_REL_ ECM_HS SG_ 505 PTORmtEngShtdwnReqd 1;
BA_REL_ "GenSigTimeoutTime" BU_SG_REL_ EBCM_OBD_HS SG_ 497 BkupPwrModeMstrVDA 250;
BA_REL_ "GenSigTimeoutMsg" BU_SG_REL_ EBCM_OBD_HS SG_ 497 BkupPwrModeMstrVDA 497;
BA_REL_ "GenSigSuprvResp" BU_SG_REL_ EBCM_OBD_HS SG_ 497 BkupPwrModeMstrVDA 2;
BA_REL_ "GenSigTimeoutTime" BU_SG_REL_ EBCM_HS SG_ 497 BkupPwrModeMstrVDA 250;
BA_REL_ "GenSigTimeoutMsg" BU_SG_REL_ EBCM_HS SG_ 497 BkupPwrModeMstrVDA 497;
BA_REL_ "GenSigSuprvResp" BU_SG_REL_ EBCM_HS SG_ 497 BkupPwrModeMstrVDA 2;
BA_REL_ "GenSigTimeoutTime" BU_SG_REL_ ECM_HS SG_ 497 ElvtdIdlCstStReq 250;
BA_REL_ "GenSigTimeoutMsg" BU_SG_REL_ ECM_HS SG_ 497 ElvtdIdlCstStReq 497;
BA_REL_ "GenSigSuprvResp" BU_SG_REL_ ECM_HS SG_ 497 ElvtdIdlCstStReq 1;
BA_REL_ "GenSigRxStartValue" BU_SG_REL_ BCP_HS SG_ 497 AirbgVDA "$1 - Virtual Device Available";
BA_REL_ "GenSigTimeoutTime" BU_SG_REL_ EPB_HS SG_ 497 SysBkupPwrMdEn 250;
BA_REL_ "GenSigTimeoutMsg" BU_SG_REL_ EPB_HS SG_ 497 SysBkupPwrMdEn 497;
BA_REL_ "GenSigVDAFailComment" BU_SG_REL_ EPB_HS SG_ 497 SysBkupPwrMdEn "Backup Power Mode Master Virtual Device Availability";
BA_REL_ "GenSigVDAFailResp" BU_SG_REL_ EPB_HS SG_ 497 SysBkupPwrMdEn 1;
BA_REL_ "GenSigSuprvResp" BU_SG_REL_ EPB_HS SG_ 497 SysBkupPwrMdEn 1;
BA_REL_ "GenSigTimeoutTime" BU_SG_REL_ EPB_HS SG_ 497 SysBkUpPwrMd 250;
BA_REL_ "GenSigTimeoutMsg" BU_SG_REL_ EPB_HS SG_ 497 SysBkUpPwrMd 497;
BA_REL_ "GenSigSuprvResp" BU_SG_REL_ EPB_HS SG_ 497 SysBkUpPwrMd 1;
BA_REL_ "GenSigTimeoutTime" BU_SG_REL_ ICCM_OBD_HS SG_ 497 SysPwrMd 250;
BA_REL_ "GenSigTimeoutMsg" BU_SG_REL_ ICCM_OBD_HS SG_ 497 SysPwrMd 497;
BA_REL_ "GenSigSuprvResp" BU_SG_REL_ ICCM_OBD_HS SG_ 497 SysPwrMd 1;
BA_REL_ "GenSigTimeoutTime" BU_SG_REL_ SAS_HS SG_ 497 SysPwrMd 250;
BA_REL_ "GenSigTimeoutMsg" BU_SG_REL_ SAS_HS SG_ 497 SysPwrMd 497;
BA_REL_ "GenSigSuprvResp" BU_SG_REL_ SAS_HS SG_ 497 SysPwrMd 1;
BA_REL_ "GenSigTimeoutTime" BU_SG_REL_ ICCM_HS SG_ 497 SysPwrMd 250;
BA_REL_ "GenSigTimeoutMsg" BU_SG_REL_ ICCM_HS SG_ 497 SysPwrMd 497;
BA_REL_ "GenSigSuprvResp" BU_SG_REL_ ICCM_HS SG_ 497 SysPwrMd 1;
BA_REL_ "GenSigTimeoutTime" BU_SG_REL_ HMIM_HS SG_ 497 SysPwrMd 250;
BA_REL_ "GenSigTimeoutMsg" BU_SG_REL_ HMIM_HS SG_ 497 SysPwrMd 497;
BA_REL_ "GenSigSuprvResp" BU_SG_REL_ HMIM_HS SG_ 497 SysPwrMd 1;
BA_REL_ "GenSigTimeoutTime" BU_SG_REL_ EPS_HS SG_ 497 SysPwrMd 250;
BA_REL_ "GenSigTimeoutMsg" BU_SG_REL_ EPS_HS SG_ 497 SysPwrMd 497;
BA_REL_ "GenSigSuprvResp" BU_SG_REL_ EPS_HS SG_ 497 SysPwrMd 1;
BA_REL_ "GenSigTimeoutTime" BU_SG_REL_ BCP_HS SG_ 497 SysPwrMd 250;
BA_REL_ "GenSigTimeoutMsg" BU_SG_REL_ BCP_HS SG_ 497 SysPwrMd 497;
BA_REL_ "GenSigSuprvResp" BU_SG_REL_ BCP_HS SG_ 497 SysPwrMd 1;
BA_REL_ "GenSigTimeoutTime" BU_SG_REL_ EBCM_OBD_HS SG_ 497 SysPwrMd 250;
BA_REL_ "GenSigTimeoutMsg" BU_SG_REL_ EBCM_OBD_HS SG_ 497 SysPwrMd 497;
BA_REL_ "GenSigSuprvResp" BU_SG_REL_ EBCM_OBD_HS SG_ 497 SysPwrMd 1;
BA_REL_ "GenSigTimeoutTime" BU_SG_REL_ EPB_HS SG_ 497 SysPwrMd 250;
BA_REL_ "GenSigTimeoutMsg" BU_SG_REL_ EPB_HS SG_ 497 SysPwrMd 497;
BA_REL_ "GenSigSuprvResp" BU_SG_REL_ EPB_HS SG_ 497 SysPwrMd 1;
BA_REL_ "GenSigTimeoutTime" BU_SG_REL_ TCCM_HS SG_ 497 SysPwrMd 250;
BA_REL_ "GenSigTimeoutMsg" BU_SG_REL_ TCCM_HS SG_ 497 SysPwrMd 497;
BA_REL_ "GenSigSuprvResp" BU_SG_REL_ TCCM_HS SG_ 497 SysPwrMd 1;
BA_REL_ "GenSigTimeoutTime" BU_SG_REL_ TCM_HS SG_ 497 SysPwrMd 250;
BA_REL_ "GenSigTimeoutMsg" BU_SG_REL_ TCM_HS SG_ 497 SysPwrMd 497;
BA_REL_ "GenSigSuprvResp" BU_SG_REL_ TCM_HS SG_ 497 SysPwrMd 1;
BA_REL_ "GenSigTimeoutTime" BU_SG_REL_ EBCM_HS SG_ 497 SysPwrMd 250;
BA_REL_ "GenSigTimeoutMsg" BU_SG_REL_ EBCM_HS SG_ 497 SysPwrMd 497;
BA_REL_ "GenSigSuprvResp" BU_SG_REL_ EBCM_HS SG_ 497 SysPwrMd 1;
BA_REL_ "GenSigTimeoutTime" BU_SG_REL_ ECM_HS SG_ 497 SysPwrMd 250;
BA_REL_ "GenSigTimeoutMsg" BU_SG_REL_ ECM_HS SG_ 497 SysPwrMd 497;
BA_REL_ "GenSigSuprvResp" BU_SG_REL_ ECM_HS SG_ 497 SysPwrMd 1;
BA_REL_ "GenSigTimeoutTime" BU_SG_REL_ EBCM_OBD_HS SG_ 497 TrStLgMdAtv 250;
BA_REL_ "GenSigTimeoutMsg" BU_SG_REL_ EBCM_OBD_HS SG_ 497 TrStLgMdAtv 497;
BA_REL_ "GenSigSuprvResp" BU_SG_REL_ EBCM_OBD_HS SG_ 497 TrStLgMdAtv 1;
BA_REL_ "GenSigTimeoutTime" BU_SG_REL_ EBCM_HS SG_ 497 TrStLgMdAtv 250;
BA_REL_ "GenSigTimeoutMsg" BU_SG_REL_ EBCM_HS SG_ 497 TrStLgMdAtv 497;
BA_REL_ "GenSigSuprvResp" BU_SG_REL_ EBCM_HS SG_ 497 TrStLgMdAtv 1;
BA_REL_ "GenSigVBitResp" BU_SG_REL_ ECM_HS SG_ 497 ACCompNormLd 1;
BA_REL_ "GenSigVDAFailComment" BU_SG_REL_ ECM_HS SG_ 497 ACCompNormLd "Air Conditioning Compressor System VDA";
BA_REL_ "GenSigVDAFailResp" BU_SG_REL_ ECM_HS SG_ 497 ACCompNormLd 1;
BA_REL_ "GenSigRxStartValue" BU_SG_REL_ TCCM_HS SG_ 497 PTORSMstrEngShtReq "False";
BA_REL_ "GenSigTimeoutTime" BU_SG_REL_ ECM_HS SG_ 497 PTORSMstrEngShtReq 250;
BA_REL_ "GenSigTimeoutMsg" BU_SG_REL_ ECM_HS SG_ 497 PTORSMstrEngShtReq 497;
BA_REL_ "GenSigRxStartValue" BU_SG_REL_ ECM_HS SG_ 497 PTORSMstrEngShtReq "False";
BA_REL_ "GenSigSuprvResp" BU_SG_REL_ ECM_HS SG_ 497 PTORSMstrEngShtReq 1;
BA_REL_ "GenSigTimeoutTime" BU_SG_REL_ ICCM_OBD_HS SG_ 497 SIRDpl 250;
BA_REL_ "GenSigTimeoutMsg" BU_SG_REL_ ICCM_OBD_HS SG_ 497 SIRDpl 497;
BA_REL_ "GenSigRxStartValue" BU_SG_REL_ ICCM_OBD_HS SG_ 497 SIRDpl "False";
BA_REL_ "GenSigSuprvResp" BU_SG_REL_ ICCM_OBD_HS SG_ 497 SIRDpl 1;
BA_REL_ "GenSigTimeoutTime" BU_SG_REL_ ICCM_HS SG_ 497 SIRDpl 250;
BA_REL_ "GenSigTimeoutMsg" BU_SG_REL_ ICCM_HS SG_ 497 SIRDpl 497;
BA_REL_ "GenSigRxStartValue" BU_SG_REL_ ICCM_HS SG_ 497 SIRDpl "False";
BA_REL_ "GenSigSuprvResp" BU_SG_REL_ ICCM_HS SG_ 497 SIRDpl 1;
BA_REL_ "GenSigRxStartValue" BU_SG_REL_ BCP_HS SG_ 497 SIRDpl "False";
BA_REL_ "GenSigRxStartValue" BU_SG_REL_ TCCM_HS SG_ 497 SIRDpl "False";
BA_REL_ "GenSigRxStartValue" BU_SG_REL_ ECM_HS SG_ 497 SIRDpl "False";
BA_REL_ "GenSigTimeoutTime" BU_SG_REL_ TCM_HS SG_ 497 PTORmStMsEngStRq 250;
BA_REL_ "GenSigTimeoutMsg" BU_SG_REL_ TCM_HS SG_ 497 PTORmStMsEngStRq 497;
BA_REL_ "GenSigSuprvResp" BU_SG_REL_ TCM_HS SG_ 497 PTORmStMsEngStRq 1;
BA_REL_ "GenSigTimeoutTime" BU_SG_REL_ EPB_HS SG_ 497 RmVehStrRq 250;
BA_REL_ "GenSigTimeoutMsg" BU_SG_REL_ EPB_HS SG_ 497 RmVehStrRq 497;
BA_REL_ "GenSigSuprvResp" BU_SG_REL_ EPB_HS SG_ 497 RmVehStrRq 1;
BA_REL_ "GenSigRxStartValue" BU_SG_REL_ TCCM_HS SG_ 497 ThrtlPrgrsnReq "$0 - Map A";
BA_REL_ "GenSigTimeoutTime" BU_SG_REL_ ECM_HS SG_ 497 ThrtlPrgrsnReq 250;
BA_REL_ "GenSigTimeoutMsg" BU_SG_REL_ ECM_HS SG_ 497 ThrtlPrgrsnReq 497;
BA_REL_ "GenSigRxStartValue" BU_SG_REL_ ECM_HS SG_ 497 ThrtlPrgrsnReq "$0 - Map A";
BA_REL_ "GenSigSuprvResp" BU_SG_REL_ ECM_HS SG_ 497 ThrtlPrgrsnReq 1;
BA_REL_ "GenSigRxStartValue" BU_SG_REL_ TCCM_HS SG_ 497 ImmblzrPreRelPswdStat "$0 - No Information";
BA_REL_ "GenSigRxStartValue" BU_SG_REL_ ECM_HS SG_ 497 ImmblzrPreRelPswdStat "$0 - No Information";
BA_REL_ "GenSigTimeoutTime" BU_SG_REL_ CGM_HS SG_ 1249 VehIdNmDig10_17 2500;
BA_REL_ "GenSigTimeoutMsg" BU_SG_REL_ CGM_HS SG_ 1249 VehIdNmDig10_17 1249;
BA_REL_ "GenSigSuprvResp" BU_SG_REL_ CGM_HS SG_ 1249 VehIdNmDig10_17 1;
BA_REL_ "GenSigTimeoutTime" BU_SG_REL_ EBCM_OBD_HS SG_ 1249 VehIdNmDig10_17 2500;
BA_REL_ "GenSigTimeoutMsg" BU_SG_REL_ EBCM_OBD_HS SG_ 1249 VehIdNmDig10_17 1249;
BA_REL_ "GenSigSuprvResp" BU_SG_REL_ EBCM_OBD_HS SG_ 1249 VehIdNmDig10_17 1;
BA_REL_ "GenSigTimeoutTime" BU_SG_REL_ TCCM_HS SG_ 1249 VehIdNmDig10_17 2500;
BA_REL_ "GenSigTimeoutMsg" BU_SG_REL_ TCCM_HS SG_ 1249 VehIdNmDig10_17 1249;
BA_REL_ "GenSigSuprvResp" BU_SG_REL_ TCCM_HS SG_ 1249 VehIdNmDig10_17 1;
BA_REL_ "GenSigTimeoutTime" BU_SG_REL_ EBCM_HS SG_ 1249 VehIdNmDig10_17 2500;
BA_REL_ "GenSigTimeoutMsg" BU_SG_REL_ EBCM_HS SG_ 1249 VehIdNmDig10_17 1249;
BA_REL_ "GenSigSuprvResp" BU_SG_REL_ EBCM_HS SG_ 1249 VehIdNmDig10_17 1;
BA_REL_ "GenSigTimeoutTime" BU_SG_REL_ CGM_HS SG_ 193 WRSLDWhlDisTpRC 250;
BA_REL_ "GenSigTimeoutMsg" BU_SG_REL_ CGM_HS SG_ 193 WRSLDWhlDisTpRC 193;
BA_REL_ "GenSigSuprvResp" BU_SG_REL_ CGM_HS SG_ 193 WRSLDWhlDisTpRC 1;
BA_REL_ "GenSigTimeoutTime" BU_SG_REL_ TCCM_HS SG_ 193 WRSLDWhlDisTpRC 25;
BA_REL_ "GenSigTimeoutMsg" BU_SG_REL_ TCCM_HS SG_ 193 WRSLDWhlDisTpRC 193;
BA_REL_ "GenSigSuprvResp" BU_SG_REL_ TCCM_HS SG_ 193 WRSLDWhlDisTpRC 1;
BA_REL_ "GenSigTimeoutTime" BU_SG_REL_ BCM_HS SG_ 193 WRSLDWhlDisTpRC 250;
BA_REL_ "GenSigTimeoutMsg" BU_SG_REL_ BCM_HS SG_ 193 WRSLDWhlDisTpRC 193;
BA_REL_ "GenSigSuprvResp" BU_SG_REL_ BCM_HS SG_ 193 WRSLDWhlDisTpRC 1;
BA_REL_ "GenSigTimeoutTime" BU_SG_REL_ CGM_HS SG_ 193 WRSLDSeqNum 250;
BA_REL_ "GenSigTimeoutMsg" BU_SG_REL_ CGM_HS SG_ 193 WRSLDSeqNum 193;
BA_REL_ "GenSigSuprvResp" BU_SG_REL_ CGM_HS SG_ 193 WRSLDSeqNum 1;
BA_REL_ "GenSigTimeoutTime" BU_SG_REL_ TCCM_HS SG_ 193 WRSLDSeqNum 25;
BA_REL_ "GenSigTimeoutMsg" BU_SG_REL_ TCCM_HS SG_ 193 WRSLDSeqNum 193;
BA_REL_ "GenSigSuprvResp" BU_SG_REL_ TCCM_HS SG_ 193 WRSLDSeqNum 1;
BA_REL_ "GenSigTimeoutTime" BU_SG_REL_ BCM_HS SG_ 193 WRSLDSeqNum 250;
BA_REL_ "GenSigTimeoutMsg" BU_SG_REL_ BCM_HS SG_ 193 WRSLDSeqNum 193;
BA_REL_ "GenSigSuprvResp" BU_SG_REL_ BCM_HS SG_ 193 WRSLDSeqNum 1;
BA_REL_ "GenSigTimeoutTime" BU_SG_REL_ CGM_HS SG_ 193 WRSLDWhlDistVal 250;
BA_REL_ "GenSigTimeoutMsg" BU_SG_REL_ CGM_HS SG_ 193 WRSLDWhlDistVal 193;
BA_REL_ "GenSigSuprvResp" BU_SG_REL_ CGM_HS SG_ 193 WRSLDWhlDistVal 1;
BA_REL_ "GenSigTimeoutTime" BU_SG_REL_ TCCM_HS SG_ 193 WRSLDWhlDistVal 25;
BA_REL_ "GenSigTimeoutMsg" BU_SG_REL_ TCCM_HS SG_ 193 WRSLDWhlDistVal 193;
BA_REL_ "GenSigSuprvResp" BU_SG_REL_ TCCM_HS SG_ 193 WRSLDWhlDistVal 1;
BA_REL_ "GenSigTimeoutTime" BU_SG_REL_ BCM_HS SG_ 193 WRSLDWhlDistVal 250;
BA_REL_ "GenSigTimeoutMsg" BU_SG_REL_ BCM_HS SG_ 193 WRSLDWhlDistVal 193;
BA_REL_ "GenSigSuprvResp" BU_SG_REL_ BCM_HS SG_ 193 WRSLDWhlDistVal 1;
BA_REL_ "GenSigTimeoutTime" BU_SG_REL_ CGM_HS SG_ 193 WRSLDWhlRotStatRst 250;
BA_REL_ "GenSigTimeoutMsg" BU_SG_REL_ CGM_HS SG_ 193 WRSLDWhlRotStatRst 193;
BA_REL_ "GenSigSuprvResp" BU_SG_REL_ CGM_HS SG_ 193 WRSLDWhlRotStatRst 1;
BA_REL_ "GenSigTimeoutTime" BU_SG_REL_ TCCM_HS SG_ 193 WRSLDWhlRotStatRst 25;
BA_REL_ "GenSigTimeoutMsg" BU_SG_REL_ TCCM_HS SG_ 193 WRSLDWhlRotStatRst 193;
BA_REL_ "GenSigSuprvResp" BU_SG_REL_ TCCM_HS SG_ 193 WRSLDWhlRotStatRst 1;
BA_REL_ "GenSigTimeoutTime" BU_SG_REL_ BCM_HS SG_ 193 WRSLDWhlRotStatRst 250;
BA_REL_ "GenSigTimeoutMsg" BU_SG_REL_ BCM_HS SG_ 193 WRSLDWhlRotStatRst 193;
BA_REL_ "GenSigSuprvResp" BU_SG_REL_ BCM_HS SG_ 193 WRSLDWhlRotStatRst 1;
BA_REL_ "GenSigTimeoutTime" BU_SG_REL_ CGM_HS SG_ 193 WRSLDWhlDistTmstm 250;
BA_REL_ "GenSigTimeoutMsg" BU_SG_REL_ CGM_HS SG_ 193 WRSLDWhlDistTmstm 193;
BA_REL_ "GenSigSuprvResp" BU_SG_REL_ CGM_HS SG_ 193 WRSLDWhlDistTmstm 1;
BA_REL_ "GenSigTimeoutTime" BU_SG_REL_ TCCM_HS SG_ 193 WRSLDWhlDistTmstm 25;
BA_REL_ "GenSigTimeoutMsg" BU_SG_REL_ TCCM_HS SG_ 193 WRSLDWhlDistTmstm 193;
BA_REL_ "GenSigSuprvResp" BU_SG_REL_ TCCM_HS SG_ 193 WRSLDWhlDistTmstm 1;
BA_REL_ "GenSigTimeoutTime" BU_SG_REL_ BCM_HS SG_ 193 WRSLDWhlDistTmstm 250;
BA_REL_ "GenSigTimeoutMsg" BU_SG_REL_ BCM_HS SG_ 193 WRSLDWhlDistTmstm 193;
BA_REL_ "GenSigSuprvResp" BU_SG_REL_ BCM_HS SG_ 193 WRSLDWhlDistTmstm 1;
BA_REL_ "GenSigTimeoutTime" BU_SG_REL_ CGM_HS SG_ 193 WRSLDWhlDistPlsCntr 250;
BA_REL_ "GenSigTimeoutMsg" BU_SG_REL_ CGM_HS SG_ 193 WRSLDWhlDistPlsCntr 193;
BA_REL_ "GenSigSuprvResp" BU_SG_REL_ CGM_HS SG_ 193 WRSLDWhlDistPlsCntr 1;
BA_REL_ "GenSigTimeoutTime" BU_SG_REL_ TCCM_HS SG_ 193 WRSLDWhlDistPlsCntr 25;
BA_REL_ "GenSigTimeoutMsg" BU_SG_REL_ TCCM_HS SG_ 193 WRSLDWhlDistPlsCntr 193;
BA_REL_ "GenSigSuprvResp" BU_SG_REL_ TCCM_HS SG_ 193 WRSLDWhlDistPlsCntr 1;
BA_REL_ "GenSigTimeoutTime" BU_SG_REL_ BCM_HS SG_ 193 WRSLDWhlDistPlsCntr 250;
BA_REL_ "GenSigTimeoutMsg" BU_SG_REL_ BCM_HS SG_ 193 WRSLDWhlDistPlsCntr 193;
BA_REL_ "GenSigSuprvResp" BU_SG_REL_ BCM_HS SG_ 193 WRSLDWhlDistPlsCntr 1;
BA_REL_ "GenSigTimeoutTime" BU_SG_REL_ CGM_HS SG_ 193 WRSRDWhlDisTpRC 250;
BA_REL_ "GenSigTimeoutMsg" BU_SG_REL_ CGM_HS SG_ 193 WRSRDWhlDisTpRC 193;
BA_REL_ "GenSigSuprvResp" BU_SG_REL_ CGM_HS SG_ 193 WRSRDWhlDisTpRC 1;
BA_REL_ "GenSigTimeoutTime" BU_SG_REL_ BCP_HS SG_ 193 WRSRDWhlDisTpRC 250;
BA_REL_ "GenSigTimeoutMsg" BU_SG_REL_ BCP_HS SG_ 193 WRSRDWhlDisTpRC 193;
BA_REL_ "GenSigSuprvResp" BU_SG_REL_ BCP_HS SG_ 193 WRSRDWhlDisTpRC 1;
BA_REL_ "GenSigTimeoutTime" BU_SG_REL_ TCCM_HS SG_ 193 WRSRDWhlDisTpRC 25;
BA_REL_ "GenSigTimeoutMsg" BU_SG_REL_ TCCM_HS SG_ 193 WRSRDWhlDisTpRC 193;
BA_REL_ "GenSigSuprvResp" BU_SG_REL_ TCCM_HS SG_ 193 WRSRDWhlDisTpRC 1;
BA_REL_ "GenSigTimeoutTime" BU_SG_REL_ BCM_HS SG_ 193 WRSRDWhlDisTpRC 250;
BA_REL_ "GenSigTimeoutMsg" BU_SG_REL_ BCM_HS SG_ 193 WRSRDWhlDisTpRC 193;
BA_REL_ "GenSigSuprvResp" BU_SG_REL_ BCM_HS SG_ 193 WRSRDWhlDisTpRC 1;
BA_REL_ "GenSigTimeoutTime" BU_SG_REL_ CGM_HS SG_ 193 WRSRDSeqNum 250;
BA_REL_ "GenSigTimeoutMsg" BU_SG_REL_ CGM_HS SG_ 193 WRSRDSeqNum 193;
BA_REL_ "GenSigSuprvResp" BU_SG_REL_ CGM_HS SG_ 193 WRSRDSeqNum 1;
BA_REL_ "GenSigTimeoutTime" BU_SG_REL_ BCP_HS SG_ 193 WRSRDSeqNum 250;
BA_REL_ "GenSigTimeoutMsg" BU_SG_REL_ BCP_HS SG_ 193 WRSRDSeqNum 193;
BA_REL_ "GenSigSuprvResp" BU_SG_REL_ BCP_HS SG_ 193 WRSRDSeqNum 1;
BA_REL_ "GenSigTimeoutTime" BU_SG_REL_ TCCM_HS SG_ 193 WRSRDSeqNum 25;
BA_REL_ "GenSigTimeoutMsg" BU_SG_REL_ TCCM_HS SG_ 193 WRSRDSeqNum 193;
BA_REL_ "GenSigSuprvResp" BU_SG_REL_ TCCM_HS SG_ 193 WRSRDSeqNum 1;
BA_REL_ "GenSigTimeoutTime" BU_SG_REL_ BCM_HS SG_ 193 WRSRDSeqNum 250;
BA_REL_ "GenSigTimeoutMsg" BU_SG_REL_ BCM_HS SG_ 193 WRSRDSeqNum 193;
BA_REL_ "GenSigSuprvResp" BU_SG_REL_ BCM_HS SG_ 193 WRSRDSeqNum 1;
BA_REL_ "GenSigTimeoutTime" BU_SG_REL_ CGM_HS SG_ 193 WRSRDWhlRotStatRst 250;
BA_REL_ "GenSigTimeoutMsg" BU_SG_REL_ CGM_HS SG_ 193 WRSRDWhlRotStatRst 193;
BA_REL_ "GenSigSuprvResp" BU_SG_REL_ CGM_HS SG_ 193 WRSRDWhlRotStatRst 1;
BA_REL_ "GenSigTimeoutTime" BU_SG_REL_ BCP_HS SG_ 193 WRSRDWhlRotStatRst 250;
BA_REL_ "GenSigTimeoutMsg" BU_SG_REL_ BCP_HS SG_ 193 WRSRDWhlRotStatRst 193;
BA_REL_ "GenSigSuprvResp" BU_SG_REL_ BCP_HS SG_ 193 WRSRDWhlRotStatRst 1;
BA_REL_ "GenSigTimeoutTime" BU_SG_REL_ TCCM_HS SG_ 193 WRSRDWhlRotStatRst 25;
BA_REL_ "GenSigTimeoutMsg" BU_SG_REL_ TCCM_HS SG_ 193 WRSRDWhlRotStatRst 193;
BA_REL_ "GenSigSuprvResp" BU_SG_REL_ TCCM_HS SG_ 193 WRSRDWhlRotStatRst 1;
BA_REL_ "GenSigTimeoutTime" BU_SG_REL_ BCM_HS SG_ 193 WRSRDWhlRotStatRst 250;
BA_REL_ "GenSigTimeoutMsg" BU_SG_REL_ BCM_HS SG_ 193 WRSRDWhlRotStatRst 193;
BA_REL_ "GenSigSuprvResp" BU_SG_REL_ BCM_HS SG_ 193 WRSRDWhlRotStatRst 1;
BA_REL_ "GenSigTimeoutTime" BU_SG_REL_ CGM_HS SG_ 193 WRSRDWhlDistVal 250;
BA_REL_ "GenSigTimeoutMsg" BU_SG_REL_ CGM_HS SG_ 193 WRSRDWhlDistVal 193;
BA_REL_ "GenSigSuprvResp" BU_SG_REL_ CGM_HS SG_ 193 WRSRDWhlDistVal 1;
BA_REL_ "GenSigTimeoutTime" BU_SG_REL_ BCP_HS SG_ 193 WRSRDWhlDistVal 250;
BA_REL_ "GenSigTimeoutMsg" BU_SG_REL_ BCP_HS SG_ 193 WRSRDWhlDistVal 193;
BA_REL_ "GenSigSuprvResp" BU_SG_REL_ BCP_HS SG_ 193 WRSRDWhlDistVal 1;
BA_REL_ "GenSigTimeoutTime" BU_SG_REL_ TCCM_HS SG_ 193 WRSRDWhlDistVal 25;
BA_REL_ "GenSigTimeoutMsg" BU_SG_REL_ TCCM_HS SG_ 193 WRSRDWhlDistVal 193;
BA_REL_ "GenSigSuprvResp" BU_SG_REL_ TCCM_HS SG_ 193 WRSRDWhlDistVal 1;
BA_REL_ "GenSigTimeoutTime" BU_SG_REL_ BCM_HS SG_ 193 WRSRDWhlDistVal 250;
BA_REL_ "GenSigTimeoutMsg" BU_SG_REL_ BCM_HS SG_ 193 WRSRDWhlDistVal 193;
BA_REL_ "GenSigSuprvResp" BU_SG_REL_ BCM_HS SG_ 193 WRSRDWhlDistVal 1;
BA_REL_ "GenSigTimeoutTime" BU_SG_REL_ CGM_HS SG_ 193 WRSRDWhlDistTmstm 250;
BA_REL_ "GenSigTimeoutMsg" BU_SG_REL_ CGM_HS SG_ 193 WRSRDWhlDistTmstm 193;
BA_REL_ "GenSigSuprvResp" BU_SG_REL_ CGM_HS SG_ 193 WRSRDWhlDistTmstm 1;
BA_REL_ "GenSigTimeoutTime" BU_SG_REL_ BCP_HS SG_ 193 WRSRDWhlDistTmstm 250;
BA_REL_ "GenSigTimeoutMsg" BU_SG_REL_ BCP_HS SG_ 193 WRSRDWhlDistTmstm 193;
BA_REL_ "GenSigSuprvResp" BU_SG_REL_ BCP_HS SG_ 193 WRSRDWhlDistTmstm 1;
BA_REL_ "GenSigTimeoutTime" BU_SG_REL_ TCCM_HS SG_ 193 WRSRDWhlDistTmstm 25;
BA_REL_ "GenSigTimeoutMsg" BU_SG_REL_ TCCM_HS SG_ 193 WRSRDWhlDistTmstm 193;
BA_REL_ "GenSigSuprvResp" BU_SG_REL_ TCCM_HS SG_ 193 WRSRDWhlDistTmstm 1;
BA_REL_ "GenSigTimeoutTime" BU_SG_REL_ BCM_HS SG_ 193 WRSRDWhlDistTmstm 250;
BA_REL_ "GenSigTimeoutMsg" BU_SG_REL_ BCM_HS SG_ 193 WRSRDWhlDistTmstm 193;
BA_REL_ "GenSigSuprvResp" BU_SG_REL_ BCM_HS SG_ 193 WRSRDWhlDistTmstm 1;
BA_REL_ "GenSigTimeoutTime" BU_SG_REL_ CGM_HS SG_ 193 WRSRDWhlDistPlsCntr 250;
BA_REL_ "GenSigTimeoutMsg" BU_SG_REL_ CGM_HS SG_ 193 WRSRDWhlDistPlsCntr 193;
BA_REL_ "GenSigSuprvResp" BU_SG_REL_ CGM_HS SG_ 193 WRSRDWhlDistPlsCntr 1;
BA_REL_ "GenSigTimeoutTime" BU_SG_REL_ BCP_HS SG_ 193 WRSRDWhlDistPlsCntr 250;
BA_REL_ "GenSigTimeoutMsg" BU_SG_REL_ BCP_HS SG_ 193 WRSRDWhlDistPlsCntr 193;
BA_REL_ "GenSigSuprvResp" BU_SG_REL_ BCP_HS SG_ 193 WRSRDWhlDistPlsCntr 1;
BA_REL_ "GenSigTimeoutTime" BU_SG_REL_ TCCM_HS SG_ 193 WRSRDWhlDistPlsCntr 25;
BA_REL_ "GenSigTimeoutMsg" BU_SG_REL_ TCCM_HS SG_ 193 WRSRDWhlDistPlsCntr 193;
BA_REL_ "GenSigSuprvResp" BU_SG_REL_ TCCM_HS SG_ 193 WRSRDWhlDistPlsCntr 1;
BA_REL_ "GenSigTimeoutTime" BU_SG_REL_ BCM_HS SG_ 193 WRSRDWhlDistPlsCntr 250;
BA_REL_ "GenSigTimeoutMsg" BU_SG_REL_ BCM_HS SG_ 193 WRSRDWhlDistPlsCntr 193;
BA_REL_ "GenSigSuprvResp" BU_SG_REL_ BCM_HS SG_ 193 WRSRDWhlDistPlsCntr 1;
BA_REL_ "GenSigTimeoutTime" BU_SG_REL_ ICCM_OBD_HS SG_ 455 CSETRER_TorqReqVal 250;
BA_REL_ "GenSigTimeoutMsg" BU_SG_REL_ ICCM_OBD_HS SG_ 455 CSETRER_TorqReqVal 455;
BA_REL_ "GenSigSuprvResp" BU_SG_REL_ ICCM_OBD_HS SG_ 455 CSETRER_TorqReqVal 1;
BA_REL_ "GenSigTimeoutTime" BU_SG_REL_ ICCM_HS SG_ 455 CSETRER_TorqReqVal 250;
BA_REL_ "GenSigTimeoutMsg" BU_SG_REL_ ICCM_HS SG_ 455 CSETRER_TorqReqVal 455;
BA_REL_ "GenSigSuprvResp" BU_SG_REL_ ICCM_HS SG_ 455 CSETRER_TorqReqVal 1;
BA_REL_ "GenSigTimeoutTime" BU_SG_REL_ ICCM_OBD_HS SG_ 455 CSETRER_TqIntvnTyp 250;
BA_REL_ "GenSigTimeoutMsg" BU_SG_REL_ ICCM_OBD_HS SG_ 455 CSETRER_TqIntvnTyp 455;
BA_REL_ "GenSigSuprvResp" BU_SG_REL_ ICCM_OBD_HS SG_ 455 CSETRER_TqIntvnTyp 1;
BA_REL_ "GenSigTimeoutTime" BU_SG_REL_ ICCM_HS SG_ 455 CSETRER_TqIntvnTyp 250;
BA_REL_ "GenSigTimeoutMsg" BU_SG_REL_ ICCM_HS SG_ 455 CSETRER_TqIntvnTyp 455;
BA_REL_ "GenSigSuprvResp" BU_SG_REL_ ICCM_HS SG_ 455 CSETRER_TqIntvnTyp 1;
BA_REL_ "GenSigRxStartValue" BU_SG_REL_ ECM_HS SG_ 455 CSETRER_TqIntvnTyp "$0 - No intervention";
BA_REL_ "GenSigTimeoutTime" BU_SG_REL_ EPS_HS SG_ 761 SprTireSt 250;
BA_REL_ "GenSigTimeoutMsg" BU_SG_REL_ EPS_HS SG_ 761 SprTireSt 761;
BA_REL_ "GenSigSuprvResp" BU_SG_REL_ EPS_HS SG_ 761 SprTireSt 1;
BA_REL_ "GenSigTimeoutTime" BU_SG_REL_ TCCM_HS SG_ 761 SprTireSt 250;
BA_REL_ "GenSigTimeoutMsg" BU_SG_REL_ TCCM_HS SG_ 761 SprTireSt 761;
BA_REL_ "GenSigSuprvResp" BU_SG_REL_ TCCM_HS SG_ 761 SprTireSt 1;
BA_REL_ "GenSigTimeoutTime" BU_SG_REL_ TCM_HS SG_ 761 BrkSysHRBkCtrlAvail 250;
BA_REL_ "GenSigTimeoutMsg" BU_SG_REL_ TCM_HS SG_ 761 BrkSysHRBkCtrlAvail 761;
BA_REL_ "GenSigSuprvResp" BU_SG_REL_ TCM_HS SG_ 761 BrkSysHRBkCtrlAvail 1;
BA_REL_ "GenSigTimeoutTime" BU_SG_REL_ TCM_HS SG_ 761 BrkSysHRBkCtrlStat 250;
BA_REL_ "GenSigTimeoutMsg" BU_SG_REL_ TCM_HS SG_ 761 BrkSysHRBkCtrlStat 761;
BA_REL_ "GenSigSuprvResp" BU_SG_REL_ TCM_HS SG_ 761 BrkSysHRBkCtrlStat 1;
BA_REL_ "GenSigTimeoutTime" BU_SG_REL_ TCM_HS SG_ 761 BrkSysHSAAval 250;
BA_REL_ "GenSigTimeoutMsg" BU_SG_REL_ TCM_HS SG_ 761 BrkSysHSAAval 761;
BA_REL_ "GenSigSuprvResp" BU_SG_REL_ TCM_HS SG_ 761 BrkSysHSAAval 1;
BA_REL_ "GenSigTimeoutTime" BU_SG_REL_ TCM_HS SG_ 761 BrkSysHSAStat 250;
BA_REL_ "GenSigTimeoutMsg" BU_SG_REL_ TCM_HS SG_ 761 BrkSysHSAStat 761;
BA_REL_ "GenSigSuprvResp" BU_SG_REL_ TCM_HS SG_ 761 BrkSysHSAStat 1;
BA_REL_ "GenSigTimeoutTime" BU_SG_REL_ ECM_HS SG_ 761 HillDscntCtrlStatPVal 250;
BA_REL_ "GenSigTimeoutMsg" BU_SG_REL_ ECM_HS SG_ 761 HillDscntCtrlStatPVal 761;
BA_REL_ "GenSigSuprvResp" BU_SG_REL_ ECM_HS SG_ 761 HillDscntCtrlStatPVal 1;
BA_REL_ "GenSigTimeoutTime" BU_SG_REL_ ECM_HS SG_ 761 HillDscntCtrlStatARC 250;
BA_REL_ "GenSigTimeoutMsg" BU_SG_REL_ ECM_HS SG_ 761 HillDscntCtrlStatARC 761;
BA_REL_ "GenSigSuprvResp" BU_SG_REL_ ECM_HS SG_ 761 HillDscntCtrlStatARC 1;
BA_REL_ "GenSigTimeoutTime" BU_SG_REL_ ECM_HS SG_ 761 HillDscntCtrlStat 250;
BA_REL_ "GenSigTimeoutMsg" BU_SG_REL_ ECM_HS SG_ 761 HillDscntCtrlStat 761;
BA_REL_ "GenSigSuprvResp" BU_SG_REL_ ECM_HS SG_ 761 HillDscntCtrlStat 1;
BA_REL_ "GenSigTimeoutTime" BU_SG_REL_ EPS_HS SG_ 761 BrkPdlDrvApplPres 250;
BA_REL_ "GenSigTimeoutMsg" BU_SG_REL_ EPS_HS SG_ 761 BrkPdlDrvApplPres 761;
BA_REL_ "GenSigSuprvResp" BU_SG_REL_ EPS_HS SG_ 761 BrkPdlDrvApplPres 1;
BA_REL_ "GenSigTimeoutTime" BU_SG_REL_ BCP_HS SG_ 761 BrkPdlDrvApplPres 250;
BA_REL_ "GenSigTimeoutMsg" BU_SG_REL_ BCP_HS SG_ 761 BrkPdlDrvApplPres 761;
BA_REL_ "GenSigSuprvResp" BU_SG_REL_ BCP_HS SG_ 761 BrkPdlDrvApplPres 1;
BA_REL_ "GenSigTimeoutTime" BU_SG_REL_ BCM_HS SG_ 489 VehDynYawRateV 250;
BA_REL_ "GenSigTimeoutMsg" BU_SG_REL_ BCM_HS SG_ 489 VehDynYawRateV 489;
BA_REL_ "GenSigSuprvRespSubValue" BU_SG_REL_ BCM_HS SG_ 489 VehDynYawRateV 1;
BA_REL_ "GenSigSuprvResp" BU_SG_REL_ BCM_HS SG_ 489 VehDynYawRateV 2;
BA_REL_ "GenSigTimeoutTime" BU_SG_REL_ ICCM_OBD_HS SG_ 489 VehDynYawRate 250;
BA_REL_ "GenSigTimeoutMsg" BU_SG_REL_ ICCM_OBD_HS SG_ 489 VehDynYawRate 489;
BA_REL_ "GenSigSuprvResp" BU_SG_REL_ ICCM_OBD_HS SG_ 489 VehDynYawRate 1;
BA_REL_ "GenSigTimeoutTime" BU_SG_REL_ ICCM_HS SG_ 489 VehDynYawRate 250;
BA_REL_ "GenSigTimeoutMsg" BU_SG_REL_ ICCM_HS SG_ 489 VehDynYawRate 489;
BA_REL_ "GenSigSuprvResp" BU_SG_REL_ ICCM_HS SG_ 489 VehDynYawRate 1;
BA_REL_ "GenSigTimeoutTime" BU_SG_REL_ HMIM_HS SG_ 489 VehDynYawRate 250;
BA_REL_ "GenSigTimeoutMsg" BU_SG_REL_ HMIM_HS SG_ 489 VehDynYawRate 489;
BA_REL_ "GenSigSuprvResp" BU_SG_REL_ HMIM_HS SG_ 489 VehDynYawRate 1;
BA_REL_ "GenSigTimeoutTime" BU_SG_REL_ BCM_HS SG_ 489 VehDynYawRate 250;
BA_REL_ "GenSigTimeoutMsg" BU_SG_REL_ BCM_HS SG_ 489 VehDynYawRate 489;
BA_REL_ "GenSigVBitResp" BU_SG_REL_ BCM_HS SG_ 489 VehDynYawRate 1;
BA_REL_ "GenSigSuprvResp" BU_SG_REL_ BCM_HS SG_ 489 VehDynYawRate 1;
BA_REL_ "GenSigRxStartValue" BU_SG_REL_ TCM_HS SG_ 489 BSTGRReqdGear "$0 - No Action";
BA_REL_ "GenSigRxStartValue" BU_SG_REL_ TCM_HS SG_ 489 BSTGRReqType "$0 - No Action";
BA_REL_ "GenSigRxStartValue" BU_SG_REL_ TCCM_HS SG_ 489 TrnsBrkSysCltchRelRqd "False";
BA_REL_ "GenSigTimeoutTime" BU_SG_REL_ TCM_HS SG_ 489 TrnsBrkSysCltchRelRqd 50;
BA_REL_ "GenSigTimeoutMsg" BU_SG_REL_ TCM_HS SG_ 489 TrnsBrkSysCltchRelRqd 489;
BA_REL_ "GenSigRxStartValue" BU_SG_REL_ TCM_HS SG_ 489 TrnsBrkSysCltchRelRqd "False";
BA_REL_ "GenSigSuprvResp" BU_SG_REL_ TCM_HS SG_ 489 TrnsBrkSysCltchRelRqd 1;
BA_REL_ "GenSigTimeoutTime" BU_SG_REL_ ECM_HS SG_ 489 EnhDrvMdSwChUseRq 250;
BA_REL_ "GenSigTimeoutMsg" BU_SG_REL_ ECM_HS SG_ 489 EnhDrvMdSwChUseRq 489;
BA_REL_ "GenSigSuprvResp" BU_SG_REL_ ECM_HS SG_ 489 EnhDrvMdSwChUseRq 1;
BA_REL_ "GenSigTimeoutTime" BU_SG_REL_ TCM_HS SG_ 489 DrvIndpntBrkAppAct 50;
BA_REL_ "GenSigTimeoutMsg" BU_SG_REL_ TCM_HS SG_ 489 DrvIndpntBrkAppAct 489;
BA_REL_ "GenSigSuprvResp" BU_SG_REL_ TCM_HS SG_ 489 DrvIndpntBrkAppAct 1;
BA_REL_ "GenSigTimeoutTime" BU_SG_REL_ ECM_HS SG_ 489 DrvIndpntBrkAppAct 50;
BA_REL_ "GenSigTimeoutMsg" BU_SG_REL_ ECM_HS SG_ 489 DrvIndpntBrkAppAct 489;
BA_REL_ "GenSigSuprvResp" BU_SG_REL_ ECM_HS SG_ 489 DrvIndpntBrkAppAct 1;
BA_REL_ "GenSigTimeoutTime" BU_SG_REL_ ECM_HS SG_ 489 WhlSlpSt 250;
BA_REL_ "GenSigTimeoutMsg" BU_SG_REL_ ECM_HS SG_ 489 WhlSlpSt 489;
BA_REL_ "GenSigSuprvResp" BU_SG_REL_ ECM_HS SG_ 489 WhlSlpSt 1;
BA_REL_ "GenSigTimeoutTime" BU_SG_REL_ EPS_HS SG_ 489 VSELatAcc 250;
BA_REL_ "GenSigTimeoutMsg" BU_SG_REL_ EPS_HS SG_ 489 VSELatAcc 489;
BA_REL_ "GenSigSuprvResp" BU_SG_REL_ EPS_HS SG_ 489 VSELatAcc 1;
BA_REL_ "GenSigTimeoutTime" BU_SG_REL_ ICCM_OBD_HS SG_ 489 VSEAct 250;
BA_REL_ "GenSigTimeoutMsg" BU_SG_REL_ ICCM_OBD_HS SG_ 489 VSEAct 489;
BA_REL_ "GenSigSuprvResp" BU_SG_REL_ ICCM_OBD_HS SG_ 489 VSEAct 1;
BA_REL_ "GenSigTimeoutTime" BU_SG_REL_ ICCM_HS SG_ 489 VSEAct 250;
BA_REL_ "GenSigTimeoutMsg" BU_SG_REL_ ICCM_HS SG_ 489 VSEAct 489;
BA_REL_ "GenSigSuprvResp" BU_SG_REL_ ICCM_HS SG_ 489 VSEAct 1;
BA_REL_ "GenSigTimeoutTime" BU_SG_REL_ EPS_HS SG_ 489 TracCntrlSysDrIntnt 250;
BA_REL_ "GenSigTimeoutMsg" BU_SG_REL_ EPS_HS SG_ 489 TracCntrlSysDrIntnt 489;
BA_REL_ "GenSigSuprvResp" BU_SG_REL_ EPS_HS SG_ 489 TracCntrlSysDrIntnt 1;
BA_REL_ "GenSigTimeoutTime" BU_SG_REL_ EPS_HS SG_ 489 BrkPdlDrvAppPrsDetcd 250;
BA_REL_ "GenSigTimeoutMsg" BU_SG_REL_ EPS_HS SG_ 489 BrkPdlDrvAppPrsDetcd 489;
BA_REL_ "GenSigSuprvResp" BU_SG_REL_ EPS_HS SG_ 489 BrkPdlDrvAppPrsDetcd 1;
BA_REL_ "GenSigVBitResp" BU_SG_REL_ ECM_HS SG_ 489 BrkPdlDrvAppPrsDetcd 1;
BA_REL_ "GenSigTimeoutTime" BU_SG_REL_ ICCM_OBD_HS SG_ 489 ABSFld 250;
BA_REL_ "GenSigTimeoutMsg" BU_SG_REL_ ICCM_OBD_HS SG_ 489 ABSFld 489;
BA_REL_ "GenSigSuprvResp" BU_SG_REL_ ICCM_OBD_HS SG_ 489 ABSFld 1;
BA_REL_ "GenSigTimeoutTime" BU_SG_REL_ ICCM_HS SG_ 489 ABSFld 250;
BA_REL_ "GenSigTimeoutMsg" BU_SG_REL_ ICCM_HS SG_ 489 ABSFld 489;
BA_REL_ "GenSigSuprvResp" BU_SG_REL_ ICCM_HS SG_ 489 ABSFld 1;
BA_REL_ "GenSigTimeoutTime" BU_SG_REL_ EPB_HS SG_ 489 ABSFld 50;
BA_REL_ "GenSigTimeoutMsg" BU_SG_REL_ EPB_HS SG_ 489 ABSFld 489;
BA_REL_ "GenSigSuprvResp" BU_SG_REL_ EPB_HS SG_ 489 ABSFld 1;
BA_REL_ "GenSigTimeoutTime" BU_SG_REL_ TCCM_HS SG_ 489 ABSAtv 250;
BA_REL_ "GenSigTimeoutMsg" BU_SG_REL_ TCCM_HS SG_ 489 ABSAtv 489;
BA_REL_ "GenSigSuprvResp" BU_SG_REL_ TCCM_HS SG_ 489 ABSAtv 1;
BA_REL_ "GenSigTimeoutTime" BU_SG_REL_ BCM_HS SG_ 489 ABSAtv 250;
BA_REL_ "GenSigTimeoutMsg" BU_SG_REL_ BCM_HS SG_ 489 ABSAtv 489;
BA_REL_ "GenSigSuprvResp" BU_SG_REL_ BCM_HS SG_ 489 ABSAtv 1;
BA_REL_ "GenSigTimeoutTime" BU_SG_REL_ EPS_HS SG_ 489 VehDynOvrUndrStr 250;
BA_REL_ "GenSigTimeoutMsg" BU_SG_REL_ EPS_HS SG_ 489 VehDynOvrUndrStr 489;
BA_REL_ "GenSigSuprvResp" BU_SG_REL_ EPS_HS SG_ 489 VehDynOvrUndrStr 1;
BA_REL_ "GenSigTimeoutTime" BU_SG_REL_ BCM_HS SG_ 381 HillDesCtrlRedVehSpIO 250;
BA_REL_ "GenSigTimeoutMsg" BU_SG_REL_ BCM_HS SG_ 381 HillDesCtrlRedVehSpIO 381;
BA_REL_ "GenSigSuprvResp" BU_SG_REL_ BCM_HS SG_ 381 HillDesCtrlRedVehSpIO 1;
BA_REL_ "GenSigSuprvResp" BU_SG_REL_ ONSTAR_HS SG_ 381 StWhAnVDA 1;
BA_REL_ "GenSigSuprvResp" BU_SG_REL_ EPB_HS SG_ 381 StWhAnVDA 1;
BA_REL_ "GenSigTimeoutTime" BU_SG_REL_ BCM_HS SG_ 381 StWhAnVDA 250;
BA_REL_ "GenSigTimeoutMsg" BU_SG_REL_ BCM_HS SG_ 381 StWhAnVDA 381;
BA_REL_ "GenSigSuprvResp" BU_SG_REL_ BCM_HS SG_ 381 StWhAnVDA 2;
BA_REL_ "GenSigTimeoutTime" BU_SG_REL_ BCM_HS SG_ 381 TirePrsLowIO 250;
BA_REL_ "GenSigTimeoutMsg" BU_SG_REL_ BCM_HS SG_ 381 TirePrsLowIO 381;
BA_REL_ "GenSigSuprvResp" BU_SG_REL_ BCM_HS SG_ 381 TirePrsLowIO 1;
BA_REL_ "GenSigTimeoutTime" BU_SG_REL_ BCM_HS SG_ 381 TreInfMonSysRstPrfmd 250;
BA_REL_ "GenSigTimeoutMsg" BU_SG_REL_ BCM_HS SG_ 381 TreInfMonSysRstPrfmd 381;
BA_REL_ "GenSigSuprvResp" BU_SG_REL_ BCM_HS SG_ 381 TreInfMonSysRstPrfmd 1;
BA_REL_ "GenSigTimeoutTime" BU_SG_REL_ BCM_HS SG_ 381 ABSIO 250;
BA_REL_ "GenSigTimeoutMsg" BU_SG_REL_ BCM_HS SG_ 381 ABSIO 381;
BA_REL_ "GenSigSuprvResp" BU_SG_REL_ BCM_HS SG_ 381 ABSIO 1;
BA_REL_ "GenSigTimeoutTime" BU_SG_REL_ BCM_HS SG_ 381 BrkPadWrnIO 250;
BA_REL_ "GenSigTimeoutMsg" BU_SG_REL_ BCM_HS SG_ 381 BrkPadWrnIO 381;
BA_REL_ "GenSigSuprvResp" BU_SG_REL_ BCM_HS SG_ 381 BrkPadWrnIO 1;
BA_REL_ "GenSigTimeoutTime" BU_SG_REL_ TCCM_HS SG_ 381 VehStabEnhmntMd 250;
BA_REL_ "GenSigTimeoutMsg" BU_SG_REL_ TCCM_HS SG_ 381 VehStabEnhmntMd 381;
BA_REL_ "GenSigSuprvResp" BU_SG_REL_ TCCM_HS SG_ 381 VehStabEnhmntMd 1;
BA_REL_ "GenSigTimeoutTime" BU_SG_REL_ BCM_HS SG_ 381 VehStabEnhmntMd 250;
BA_REL_ "GenSigTimeoutMsg" BU_SG_REL_ BCM_HS SG_ 381 VehStabEnhmntMd 381;
BA_REL_ "GenSigRxStartValue" BU_SG_REL_ BCM_HS SG_ 381 VehStabEnhmntMd "$1 - Normal";
BA_REL_ "GenSigSuprvResp" BU_SG_REL_ BCM_HS SG_ 381 VehStabEnhmntMd 1;
BA_REL_ "GenSigTimeoutTime" BU_SG_REL_ EPS_HS SG_ 381 VehStabEnhmntStat 250;
BA_REL_ "GenSigTimeoutMsg" BU_SG_REL_ EPS_HS SG_ 381 VehStabEnhmntStat 381;
BA_REL_ "GenSigSuprvResp" BU_SG_REL_ EPS_HS SG_ 381 VehStabEnhmntStat 1;
BA_REL_ "GenSigTimeoutTime" BU_SG_REL_ BCM_HS SG_ 381 VehStabEnhmntStat 250;
BA_REL_ "GenSigTimeoutMsg" BU_SG_REL_ BCM_HS SG_ 381 VehStabEnhmntStat 381;
BA_REL_ "GenSigSuprvResp" BU_SG_REL_ BCM_HS SG_ 381 VehStabEnhmntStat 1;
BA_REL_ "GenSigTimeoutTime" BU_SG_REL_ EPS_HS SG_ 381 TCSysOpMd 250;
BA_REL_ "GenSigTimeoutMsg" BU_SG_REL_ EPS_HS SG_ 381 TCSysOpMd 381;
BA_REL_ "GenSigSuprvResp" BU_SG_REL_ EPS_HS SG_ 381 TCSysOpMd 1;
BA_REL_ "GenSigTimeoutTime" BU_SG_REL_ BCM_HS SG_ 381 TCSysOpMd 250;
BA_REL_ "GenSigTimeoutMsg" BU_SG_REL_ BCM_HS SG_ 381 TCSysOpMd 381;
BA_REL_ "GenSigRxStartValue" BU_SG_REL_ BCM_HS SG_ 381 TCSysOpMd "$1 - Normal";
BA_REL_ "GenSigSuprvResp" BU_SG_REL_ BCM_HS SG_ 381 TCSysOpMd 1;
BA_REL_ "GenSigTimeoutTime" BU_SG_REL_ BCM_HS SG_ 381 TCSysOpStat 250;
BA_REL_ "GenSigTimeoutMsg" BU_SG_REL_ BCM_HS SG_ 381 TCSysOpStat 381;
BA_REL_ "GenSigSuprvResp" BU_SG_REL_ BCM_HS SG_ 381 TCSysOpStat 1;
BA_REL_ "GenSigTimeoutTime" BU_SG_REL_ BCM_HS SG_ 381 BrkSysVTopSpdLimVal 250;
BA_REL_ "GenSigTimeoutMsg" BU_SG_REL_ BCM_HS SG_ 381 BrkSysVTopSpdLimVal 381;
BA_REL_ "GenSigSuprvRespSubValue" BU_SG_REL_ BCM_HS SG_ 381 BrkSysVTopSpdLimVal 255;
BA_REL_ "GenSigSuprvResp" BU_SG_REL_ BCM_HS SG_ 381 BrkSysVTopSpdLimVal 2;
BA_REL_ "GenSigTimeoutTime" BU_SG_REL_ BCM_HS SG_ 381 BrkSysBrkLtsReqd 250;
BA_REL_ "GenSigTimeoutMsg" BU_SG_REL_ BCM_HS SG_ 381 BrkSysBrkLtsReqd 381;
BA_REL_ "GenSigSuprvResp" BU_SG_REL_ BCM_HS SG_ 381 BrkSysBrkLtsReqd 2;
BA_REL_ "GenSigTimeoutTime" BU_SG_REL_ ECM_HS SG_ 381 ActVehAccel 250;
BA_REL_ "GenSigTimeoutMsg" BU_SG_REL_ ECM_HS SG_ 381 ActVehAccel 381;
BA_REL_ "GenSigSuprvResp" BU_SG_REL_ ECM_HS SG_ 381 ActVehAccel 1;
BA_REL_ "GenSigTimeoutTime" BU_SG_REL_ CGM_HS SG_ 241 BrkPdlChkData 250;
BA_REL_ "GenSigTimeoutMsg" BU_SG_REL_ CGM_HS SG_ 241 BrkPdlChkData 241;
BA_REL_ "GenSigSuprvResp" BU_SG_REL_ CGM_HS SG_ 241 BrkPdlChkData 1;
BA_REL_ "GenSigTimeoutTime" BU_SG_REL_ CGM_HS SG_ 241 BrkPdlPosGrad 250;
BA_REL_ "GenSigTimeoutMsg" BU_SG_REL_ CGM_HS SG_ 241 BrkPdlPosGrad 241;
BA_REL_ "GenSigSuprvResp" BU_SG_REL_ CGM_HS SG_ 241 BrkPdlPosGrad 1;
BA_REL_ "GenSigTimeoutTime" BU_SG_REL_ EPS_HS SG_ 241 BrkPdlPosGrad 250;
BA_REL_ "GenSigTimeoutMsg" BU_SG_REL_ EPS_HS SG_ 241 BrkPdlPosGrad 241;
BA_REL_ "GenSigSuprvResp" BU_SG_REL_ EPS_HS SG_ 241 BrkPdlPosGrad 1;
BA_REL_ "GenSigTimeoutTime" BU_SG_REL_ EPS_HS SG_ 241 NotEventStat 250;
BA_REL_ "GenSigTimeoutMsg" BU_SG_REL_ EPS_HS SG_ 241 NotEventStat 241;
BA_REL_ "GenSigSuprvResp" BU_SG_REL_ EPS_HS SG_ 241 NotEventStat 1;
BA_REL_ "GenSigTimeoutTime" BU_SG_REL_ EBCM_OBD_HS SG_ 241 NotEventStat 250;
BA_REL_ "GenSigTimeoutMsg" BU_SG_REL_ EBCM_OBD_HS SG_ 241 NotEventStat 241;
BA_REL_ "GenSigSuprvResp" BU_SG_REL_ EBCM_OBD_HS SG_ 241 NotEventStat 1;
BA_REL_ "GenSigTimeoutTime" BU_SG_REL_ EBCM_HS SG_ 241 NotEventStat 250;
BA_REL_ "GenSigTimeoutMsg" BU_SG_REL_ EBCM_HS SG_ 241 NotEventStat 241;
BA_REL_ "GenSigSuprvResp" BU_SG_REL_ EBCM_HS SG_ 241 NotEventStat 1;
BA_REL_ "GenSigTimeoutTime" BU_SG_REL_ CGM_HS SG_ 241 BrkAppSnsrHmPosLrnd 250;
BA_REL_ "GenSigTimeoutMsg" BU_SG_REL_ CGM_HS SG_ 241 BrkAppSnsrHmPosLrnd 241;
BA_REL_ "GenSigSuprvResp" BU_SG_REL_ CGM_HS SG_ 241 BrkAppSnsrHmPosLrnd 1;
BA_REL_ "GenSigTimeoutTime" BU_SG_REL_ EPS_HS SG_ 241 BrkAppSnsrHmPosLrnd 250;
BA_REL_ "GenSigTimeoutMsg" BU_SG_REL_ EPS_HS SG_ 241 BrkAppSnsrHmPosLrnd 241;
BA_REL_ "GenSigSuprvResp" BU_SG_REL_ EPS_HS SG_ 241 BrkAppSnsrHmPosLrnd 1;
BA_REL_ "GenSigTimeoutTime" BU_SG_REL_ EBCM_OBD_HS SG_ 241 BrkAppSnsrHmPosLrnd 250;
BA_REL_ "GenSigTimeoutMsg" BU_SG_REL_ EBCM_OBD_HS SG_ 241 BrkAppSnsrHmPosLrnd 241;
BA_REL_ "GenSigSuprvResp" BU_SG_REL_ EBCM_OBD_HS SG_ 241 BrkAppSnsrHmPosLrnd 1;
BA_REL_ "GenSigTimeoutTime" BU_SG_REL_ EBCM_HS SG_ 241 BrkAppSnsrHmPosLrnd 250;
BA_REL_ "GenSigTimeoutMsg" BU_SG_REL_ EBCM_HS SG_ 241 BrkAppSnsrHmPosLrnd 241;
BA_REL_ "GenSigSuprvResp" BU_SG_REL_ EBCM_HS SG_ 241 BrkAppSnsrHmPosLrnd 1;
BA_REL_ "GenSigTimeoutTime" BU_SG_REL_ CGM_HS SG_ 241 BrkPedTrvlAchvd 250;
BA_REL_ "GenSigTimeoutMsg" BU_SG_REL_ CGM_HS SG_ 241 BrkPedTrvlAchvd 241;
BA_REL_ "GenSigSuprvResp" BU_SG_REL_ CGM_HS SG_ 241 BrkPedTrvlAchvd 1;
BA_REL_ "GenSigTimeoutTime" BU_SG_REL_ EPS_HS SG_ 241 BrkPedTrvlAchvd 250;
BA_REL_ "GenSigTimeoutMsg" BU_SG_REL_ EPS_HS SG_ 241 BrkPedTrvlAchvd 241;
BA_REL_ "GenSigSuprvResp" BU_SG_REL_ EPS_HS SG_ 241 BrkPedTrvlAchvd 1;
BA_REL_ "GenSigTimeoutTime" BU_SG_REL_ EPB_HS SG_ 241 BrkPedTrvlAchvd 25;
BA_REL_ "GenSigTimeoutMsg" BU_SG_REL_ EPB_HS SG_ 241 BrkPedTrvlAchvd 241;
BA_REL_ "GenSigSuprvResp" BU_SG_REL_ EPB_HS SG_ 241 BrkPedTrvlAchvd 1;
BA_REL_ "GenSigTimeoutTime" BU_SG_REL_ CGM_HS SG_ 241 BrkPedTrvlAchvdV 250;
BA_REL_ "GenSigTimeoutMsg" BU_SG_REL_ CGM_HS SG_ 241 BrkPedTrvlAchvdV 241;
BA_REL_ "GenSigSuprvResp" BU_SG_REL_ CGM_HS SG_ 241 BrkPedTrvlAchvdV 1;
BA_REL_ "GenSigTimeoutTime" BU_SG_REL_ EPS_HS SG_ 241 BrkPedTrvlAchvdV 250;
BA_REL_ "GenSigTimeoutMsg" BU_SG_REL_ EPS_HS SG_ 241 BrkPedTrvlAchvdV 241;
BA_REL_ "GenSigSuprvResp" BU_SG_REL_ EPS_HS SG_ 241 BrkPedTrvlAchvdV 1;
BA_REL_ "GenSigTimeoutTime" BU_SG_REL_ EPB_HS SG_ 241 BrkPedTrvlAchvdV 25;
BA_REL_ "GenSigTimeoutMsg" BU_SG_REL_ EPB_HS SG_ 241 BrkPedTrvlAchvdV 241;
BA_REL_ "GenSigSuprvResp" BU_SG_REL_ EPB_HS SG_ 241 BrkPedTrvlAchvdV 1;
BA_REL_ "GenSigTimeoutTime" BU_SG_REL_ CGM_HS SG_ 241 BrkPdlPos 250;
BA_REL_ "GenSigTimeoutMsg" BU_SG_REL_ CGM_HS SG_ 241 BrkPdlPos 241;
BA_REL_ "GenSigSuprvResp" BU_SG_REL_ CGM_HS SG_ 241 BrkPdlPos 1;
BA_REL_ "GenSigTimeoutTime" BU_SG_REL_ EPS_HS SG_ 241 BrkPdlPos 250;
BA_REL_ "GenSigTimeoutMsg" BU_SG_REL_ EPS_HS SG_ 241 BrkPdlPos 241;
BA_REL_ "GenSigSuprvResp" BU_SG_REL_ EPS_HS SG_ 241 BrkPdlPos 1;
BA_REL_ "GenSigTimeoutTime" BU_SG_REL_ TCCM_HS SG_ 241 BrkPdlPos 250;
BA_REL_ "GenSigTimeoutMsg" BU_SG_REL_ TCCM_HS SG_ 241 BrkPdlPos 241;
BA_REL_ "GenSigSuprvResp" BU_SG_REL_ TCCM_HS SG_ 241 BrkPdlPos 1;
BA_REL_ "GenSigTimeoutTime" BU_SG_REL_ ECM_HS SG_ 241 BrkPdlPos 250;
BA_REL_ "GenSigTimeoutMsg" BU_SG_REL_ ECM_HS SG_ 241 BrkPdlPos 241;
BA_REL_ "GenSigSuprvResp" BU_SG_REL_ ECM_HS SG_ 241 BrkPdlPos 1;
BA_REL_ "GenSigTimeoutTime" BU_SG_REL_ ICCM_OBD_HS SG_ 241 BrkPedPosAlvRolngCnt 250;
BA_REL_ "GenSigTimeoutMsg" BU_SG_REL_ ICCM_OBD_HS SG_ 241 BrkPedPosAlvRolngCnt 241;
BA_REL_ "GenSigSuprvResp" BU_SG_REL_ ICCM_OBD_HS SG_ 241 BrkPedPosAlvRolngCnt 1;
BA_REL_ "GenSigTimeoutTime" BU_SG_REL_ ICCM_HS SG_ 241 BrkPedPosAlvRolngCnt 250;
BA_REL_ "GenSigTimeoutMsg" BU_SG_REL_ ICCM_HS SG_ 241 BrkPedPosAlvRolngCnt 241;
BA_REL_ "GenSigSuprvResp" BU_SG_REL_ ICCM_HS SG_ 241 BrkPedPosAlvRolngCnt 1;
BA_REL_ "GenSigTimeoutTime" BU_SG_REL_ EPS_HS SG_ 241 BrkPedPosAlvRolngCnt 250;
BA_REL_ "GenSigTimeoutMsg" BU_SG_REL_ EPS_HS SG_ 241 BrkPedPosAlvRolngCnt 241;
BA_REL_ "GenSigSuprvResp" BU_SG_REL_ EPS_HS SG_ 241 BrkPedPosAlvRolngCnt 1;
BA_REL_ "GenSigTimeoutTime" BU_SG_REL_ EBCM_OBD_HS SG_ 241 BrkPedPosAlvRolngCnt 250;
BA_REL_ "GenSigTimeoutMsg" BU_SG_REL_ EBCM_OBD_HS SG_ 241 BrkPedPosAlvRolngCnt 241;
BA_REL_ "GenSigSuprvResp" BU_SG_REL_ EBCM_OBD_HS SG_ 241 BrkPedPosAlvRolngCnt 1;
BA_REL_ "GenSigTimeoutTime" BU_SG_REL_ EBCM_HS SG_ 241 BrkPedPosAlvRolngCnt 250;
BA_REL_ "GenSigTimeoutMsg" BU_SG_REL_ EBCM_HS SG_ 241 BrkPedPosAlvRolngCnt 241;
BA_REL_ "GenSigSuprvResp" BU_SG_REL_ EBCM_HS SG_ 241 BrkPedPosAlvRolngCnt 1;
BA_REL_ "GenSigTimeoutTime" BU_SG_REL_ CGM_HS SG_ 241 BrkPdlModTrvl 250;
BA_REL_ "GenSigTimeoutMsg" BU_SG_REL_ CGM_HS SG_ 241 BrkPdlModTrvl 241;
BA_REL_ "GenSigSuprvResp" BU_SG_REL_ CGM_HS SG_ 241 BrkPdlModTrvl 1;
BA_REL_ "GenSigTimeoutTime" BU_SG_REL_ EPS_HS SG_ 241 BrkPdlModTrvl 250;
BA_REL_ "GenSigTimeoutMsg" BU_SG_REL_ EPS_HS SG_ 241 BrkPdlModTrvl 241;
BA_REL_ "GenSigSuprvResp" BU_SG_REL_ EPS_HS SG_ 241 BrkPdlModTrvl 1;
BA_REL_ "GenSigTimeoutTime" BU_SG_REL_ EBCM_OBD_HS SG_ 241 BrkPdlModTrvl 250;
BA_REL_ "GenSigTimeoutMsg" BU_SG_REL_ EBCM_OBD_HS SG_ 241 BrkPdlModTrvl 241;
BA_REL_ "GenSigSuprvResp" BU_SG_REL_ EBCM_OBD_HS SG_ 241 BrkPdlModTrvl 1;
BA_REL_ "GenSigTimeoutTime" BU_SG_REL_ EBCM_HS SG_ 241 BrkPdlModTrvl 250;
BA_REL_ "GenSigTimeoutMsg" BU_SG_REL_ EBCM_HS SG_ 241 BrkPdlModTrvl 241;
BA_REL_ "GenSigSuprvResp" BU_SG_REL_ EBCM_HS SG_ 241 BrkPdlModTrvl 1;
BA_REL_ "GenSigVBitResp" BU_SG_REL_ ECM_HS SG_ 241 BrkPdlModTrvl 1;
BA_REL_ "GenSigTimeoutTime" BU_SG_REL_ CGM_HS SG_ 241 BrkPdlInTrvPrt 250;
BA_REL_ "GenSigTimeoutMsg" BU_SG_REL_ CGM_HS SG_ 241 BrkPdlInTrvPrt 241;
BA_REL_ "GenSigSuprvResp" BU_SG_REL_ CGM_HS SG_ 241 BrkPdlInTrvPrt 1;
BA_REL_ "GenSigTimeoutTime" BU_SG_REL_ EPS_HS SG_ 241 BrkPdlInTrvPrt 250;
BA_REL_ "GenSigTimeoutMsg" BU_SG_REL_ EPS_HS SG_ 241 BrkPdlInTrvPrt 241;
BA_REL_ "GenSigSuprvResp" BU_SG_REL_ EPS_HS SG_ 241 BrkPdlInTrvPrt 1;
BA_REL_ "GenSigTimeoutMsg" BU_SG_REL_ BCM_HS SG_ 1271 BatSvrMdLvl7Act 1271;
BA_REL_ "GenSigSuprvResp" BU_SG_REL_ BCM_HS SG_ 1271 BatSvrMdLvl7Act 1;
BA_REL_ "GenSigTimeoutMsg" BU_SG_REL_ BCM_HS SG_ 1271 BatSvrMdNetAmpHr 1271;
BA_REL_ "GenSigSuprvResp" BU_SG_REL_ BCM_HS SG_ 1271 BatSvrMdNetAmpHr 1;
BA_REL_ "GenSigTimeoutMsg" BU_SG_REL_ BCM_HS SG_ 1271 BatSvrMdWkUpCtr 1271;
BA_REL_ "GenSigSuprvResp" BU_SG_REL_ BCM_HS SG_ 1271 BatSvrMdWkUpCtr 1;
BA_REL_ "GenSigTimeoutMsg" BU_SG_REL_ BCM_HS SG_ 1271 BSMCT_RawVal 1271;
BA_REL_ "GenSigSuprvResp" BU_SG_REL_ BCM_HS SG_ 1271 BSMCT_RawVal 1;
BA_REL_ "GenSigTimeoutMsg" BU_SG_REL_ BCM_HS SG_ 1271 BSMCT_Mult 1271;
BA_REL_ "GenSigSuprvResp" BU_SG_REL_ BCM_HS SG_ 1271 BSMCT_Mult 1;
BA_REL_ "GenSigTimeoutMsg" BU_SG_REL_ BCM_HS SG_ 1271 BatSvrMdVltTrg 1271;
BA_REL_ "GenSigSuprvResp" BU_SG_REL_ BCM_HS SG_ 1271 BatSvrMdVltTrg 1;
BA_REL_ "GenSigTimeoutMsg" BU_SG_REL_ BCM_HS SG_ 1271 BatSvrMdLvl6Act 1271;
BA_REL_ "GenSigSuprvResp" BU_SG_REL_ BCM_HS SG_ 1271 BatSvrMdLvl6Act 1;
BA_REL_ "GenSigTimeoutMsg" BU_SG_REL_ BCM_HS SG_ 1271 BatSvrMdLvl5Act 1271;
BA_REL_ "GenSigSuprvResp" BU_SG_REL_ BCM_HS SG_ 1271 BatSvrMdLvl5Act 1;
BA_REL_ "GenSigTimeoutMsg" BU_SG_REL_ BCM_HS SG_ 1271 BatSvrMdLvl4Act 1271;
BA_REL_ "GenSigSuprvResp" BU_SG_REL_ BCM_HS SG_ 1271 BatSvrMdLvl4Act 1;
BA_REL_ "GenSigTimeoutTime" BU_SG_REL_ BCM_HS SG_ 1263 BatSOFVolt 2500;
BA_REL_ "GenSigTimeoutMsg" BU_SG_REL_ BCM_HS SG_ 1263 BatSOFVolt 1263;
BA_REL_ "GenSigSuprvResp" BU_SG_REL_ BCM_HS SG_ 1263 BatSOFVolt 1;
BA_REL_ "GenSigTimeoutTime" BU_SG_REL_ BCM_HS SG_ 1263 BatSOH 2500;
BA_REL_ "GenSigTimeoutMsg" BU_SG_REL_ BCM_HS SG_ 1263 BatSOH 1263;
BA_REL_ "GenSigSuprvResp" BU_SG_REL_ BCM_HS SG_ 1263 BatSOH 1;
BA_REL_ "GenSigTimeoutTime" BU_SG_REL_ BCM_HS SG_ 1263 IBSBatSOC 2500;
BA_REL_ "GenSigTimeoutMsg" BU_SG_REL_ BCM_HS SG_ 1263 IBSBatSOC 1263;
BA_REL_ "GenSigSuprvResp" BU_SG_REL_ BCM_HS SG_ 1263 IBSBatSOC 1;
BA_REL_ "GenSigTimeoutTime" BU_SG_REL_ BCM_HS SG_ 1263 BattSOXStat 2500;
BA_REL_ "GenSigTimeoutMsg" BU_SG_REL_ BCM_HS SG_ 1263 BattSOXStat 1263;
BA_REL_ "GenSigSuprvResp" BU_SG_REL_ BCM_HS SG_ 1263 BattSOXStat 1;
BA_REL_ "GenSigTimeoutTime" BU_SG_REL_ BCM_HS SG_ 1261 MinCrnkCrnt 2500;
BA_REL_ "GenSigTimeoutMsg" BU_SG_REL_ BCM_HS SG_ 1261 MinCrnkCrnt 1261;
BA_REL_ "GenSigSuprvResp" BU_SG_REL_ BCM_HS SG_ 1261 MinCrnkCrnt 1;
BA_REL_ "GenSigTimeoutTime" BU_SG_REL_ BCM_HS SG_ 1261 MinCrnkVlt 2500;
BA_REL_ "GenSigTimeoutMsg" BU_SG_REL_ BCM_HS SG_ 1261 MinCrnkVlt 1261;
BA_REL_ "GenSigSuprvResp" BU_SG_REL_ BCM_HS SG_ 1261 MinCrnkVlt 1;
BA_REL_ "GenSigTimeoutTime" BU_SG_REL_ BCM_HS SG_ 1261 BattTemp 2500;
BA_REL_ "GenSigTimeoutMsg" BU_SG_REL_ BCM_HS SG_ 1261 BattTemp 1261;
BA_REL_ "GenSigSuprvResp" BU_SG_REL_ BCM_HS SG_ 1261 BattTemp 1;
BA_REL_ "GenSigTimeoutTime" BU_SG_REL_ BCM_HS SG_ 1259 AllNodesVNA 1250;
BA_REL_ "GenSigTimeoutMsg" BU_SG_REL_ BCM_HS SG_ 1259 AllNodesVNA 1259;
BA_REL_ "GenSigSuprvResp" BU_SG_REL_ BCM_HS SG_ 1259 AllNodesVNA 1;
BA_REL_ "GenSigTimeoutTime" BU_SG_REL_ BCM_HS SG_ 1259 NAHrDisChrg 1250;
BA_REL_ "GenSigTimeoutMsg" BU_SG_REL_ BCM_HS SG_ 1259 NAHrDisChrg 1259;
BA_REL_ "GenSigSuprvResp" BU_SG_REL_ BCM_HS SG_ 1259 NAHrDisChrg 1;
BA_REL_ "GenSigTimeoutTime" BU_SG_REL_ BCM_HS SG_ 1259 NAHrChg 1250;
BA_REL_ "GenSigTimeoutMsg" BU_SG_REL_ BCM_HS SG_ 1259 NAHrChg 1259;
BA_REL_ "GenSigSuprvResp" BU_SG_REL_ BCM_HS SG_ 1259 NAHrChg 1;
BA_REL_ "GenSigTimeoutTime" BU_SG_REL_ TCM_HS SG_ 426 AuxTransPrsCmndOn 250;
BA_REL_ "GenSigTimeoutMsg" BU_SG_REL_ TCM_HS SG_ 426 AuxTransPrsCmndOn 426;
BA_REL_ "GenSigSuprvResp" BU_SG_REL_ TCM_HS SG_ 426 AuxTransPrsCmndOn 1;
BA_REL_ "GenSigTimeoutTime" BU_SG_REL_ TCM_HS SG_ 426 EVTCS_CmdTrqCapMd 250;
BA_REL_ "GenSigTimeoutMsg" BU_SG_REL_ TCM_HS SG_ 426 EVTCS_CmdTrqCapMd 426;
BA_REL_ "GenSigSuprvResp" BU_SG_REL_ TCM_HS SG_ 426 EVTCS_CmdTrqCapMd 1;
BA_REL_ "GenSigTimeoutTime" BU_SG_REL_ TCM_HS SG_ 426 EVTCS_CrntTrqCapMd 250;
BA_REL_ "GenSigTimeoutMsg" BU_SG_REL_ TCM_HS SG_ 426 EVTCS_CrntTrqCapMd 426;
BA_REL_ "GenSigSuprvResp" BU_SG_REL_ TCM_HS SG_ 426 EVTCS_CrntTrqCapMd 1;
BA_REL_ "GenSigTimeoutTime" BU_SG_REL_ TCM_HS SG_ 426 EngPrdctStdyStTorq 250;
BA_REL_ "GenSigTimeoutMsg" BU_SG_REL_ TCM_HS SG_ 426 EngPrdctStdyStTorq 426;
BA_REL_ "GenSigSuprvResp" BU_SG_REL_ TCM_HS SG_ 426 EngPrdctStdyStTorq 1;
BA_REL_ "GenSigTimeoutTime" BU_SG_REL_ TCM_HS SG_ 426 CrnkShftTrqMinOffCap 250;
BA_REL_ "GenSigTimeoutMsg" BU_SG_REL_ TCM_HS SG_ 426 CrnkShftTrqMinOffCap 426;
BA_REL_ "GenSigSuprvResp" BU_SG_REL_ TCM_HS SG_ 426 CrnkShftTrqMinOffCap 1;
BA_REL_ "GenSigTimeoutTime" BU_SG_REL_ TCM_HS SG_ 426 CrksftTqMinRunImCap 250;
BA_REL_ "GenSigTimeoutMsg" BU_SG_REL_ TCM_HS SG_ 426 CrksftTqMinRunImCap 426;
BA_REL_ "GenSigSuprvResp" BU_SG_REL_ TCM_HS SG_ 426 CrksftTqMinRunImCap 1;
BA_REL_ "GenSigTimeoutTime" BU_SG_REL_ BCM_HS SG_ 1231 DslExhFluidDistTIndcmt 2500;
BA_REL_ "GenSigTimeoutMsg" BU_SG_REL_ BCM_HS SG_ 1231 DslExhFluidDistTIndcmt 1231;
BA_REL_ "GenSigSuprvResp" BU_SG_REL_ BCM_HS SG_ 1231 DslExhFluidDistTIndcmt 1;
BA_REL_ "GenSigTimeoutTime" BU_SG_REL_ BCM_HS SG_ 1231 DslExhFluidLvlPrcnt 2500;
BA_REL_ "GenSigTimeoutMsg" BU_SG_REL_ BCM_HS SG_ 1231 DslExhFluidLvlPrcnt 1231;
BA_REL_ "GenSigSuprvResp" BU_SG_REL_ BCM_HS SG_ 1231 DslExhFluidLvlPrcnt 1;
BA_REL_ "GenSigTimeoutTime" BU_SG_REL_ TCCM_HS SG_ 419 EngRunng 250;
BA_REL_ "GenSigTimeoutMsg" BU_SG_REL_ TCCM_HS SG_ 419 EngRunng 419;
BA_REL_ "GenSigSuprvResp" BU_SG_REL_ TCCM_HS SG_ 419 EngRunng 1;
BA_REL_ "GenSigTimeoutTime" BU_SG_REL_ BCM_HS SG_ 419 EngRunng 250;
BA_REL_ "GenSigTimeoutMsg" BU_SG_REL_ BCM_HS SG_ 419 EngRunng 419;
BA_REL_ "GenSigSuprvResp" BU_SG_REL_ BCM_HS SG_ 419 EngRunng 1;
BA_REL_ "GenSigTimeoutTime" BU_SG_REL_ EBCM_OBD_HS SG_ 1223 PropSysOffTme 1250;
BA_REL_ "GenSigTimeoutMsg" BU_SG_REL_ EBCM_OBD_HS SG_ 1223 PropSysOffTme 1223;
BA_REL_ "GenSigSuprvResp" BU_SG_REL_ EBCM_OBD_HS SG_ 1223 PropSysOffTme 1;
BA_REL_ "GenSigTimeoutTime" BU_SG_REL_ EBCM_HS SG_ 1223 PropSysOffTme 1250;
BA_REL_ "GenSigTimeoutMsg" BU_SG_REL_ EBCM_HS SG_ 1223 PropSysOffTme 1223;
BA_REL_ "GenSigSuprvResp" BU_SG_REL_ EBCM_HS SG_ 1223 PropSysOffTme 1;
BA_REL_ "GenSigTimeoutTime" BU_SG_REL_ TCM_HS SG_ 479 EngAutoStpNotProb 250;
BA_REL_ "GenSigTimeoutMsg" BU_SG_REL_ TCM_HS SG_ 479 EngAutoStpNotProb 479;
BA_REL_ "GenSigSuprvResp" BU_SG_REL_ TCM_HS SG_ 479 EngAutoStpNotProb 1;
BA_REL_ "GenSigTimeoutTime" BU_SG_REL_ BCM_HS SG_ 479 EngAutoStpNotProb 250;
BA_REL_ "GenSigTimeoutMsg" BU_SG_REL_ BCM_HS SG_ 479 EngAutoStpNotProb 479;
BA_REL_ "GenSigSuprvResp" BU_SG_REL_ BCM_HS SG_ 479 EngAutoStpNotProb 1;
BA_REL_ "GenSigTimeoutTime" BU_SG_REL_ ECM_HS SG_ 479 EngAutoStpNotProb 250;
BA_REL_ "GenSigTimeoutMsg" BU_SG_REL_ ECM_HS SG_ 479 EngAutoStpNotProb 479;
BA_REL_ "GenSigSuprvResp" BU_SG_REL_ ECM_HS SG_ 479 EngAutoStpNotProb 1;
BA_REL_ "GenSigTimeoutTime" BU_SG_REL_ EBCM_OBD_HS SG_ 479 EASSI_UnsdRsrvd2 250;
BA_REL_ "GenSigTimeoutMsg" BU_SG_REL_ EBCM_OBD_HS SG_ 479 EASSI_UnsdRsrvd2 479;
BA_REL_ "GenSigSuprvResp" BU_SG_REL_ EBCM_OBD_HS SG_ 479 EASSI_UnsdRsrvd2 1;
BA_REL_ "GenSigTimeoutTime" BU_SG_REL_ TCCM_HS SG_ 479 EASSI_UnsdRsrvd2 250;
BA_REL_ "GenSigTimeoutMsg" BU_SG_REL_ TCCM_HS SG_ 479 EASSI_UnsdRsrvd2 479;
BA_REL_ "GenSigSuprvResp" BU_SG_REL_ TCCM_HS SG_ 479 EASSI_UnsdRsrvd2 1;
BA_REL_ "GenSigTimeoutTime" BU_SG_REL_ EBCM_HS SG_ 479 EASSI_UnsdRsrvd2 250;
BA_REL_ "GenSigTimeoutMsg" BU_SG_REL_ EBCM_HS SG_ 479 EASSI_UnsdRsrvd2 479;
BA_REL_ "GenSigSuprvResp" BU_SG_REL_ EBCM_HS SG_ 479 EASSI_UnsdRsrvd2 1;
BA_REL_ "GenSigTimeoutTime" BU_SG_REL_ TCM_HS SG_ 479 EASSI_UnsdRsrvd2 250;
BA_REL_ "GenSigTimeoutMsg" BU_SG_REL_ TCM_HS SG_ 479 EASSI_UnsdRsrvd2 479;
BA_REL_ "GenSigSuprvResp" BU_SG_REL_ TCM_HS SG_ 479 EASSI_UnsdRsrvd2 1;
BA_REL_ "GenSigTimeoutTime" BU_SG_REL_ BCM_HS SG_ 479 EASSI_UnsdRsrvd2 250;
BA_REL_ "GenSigTimeoutMsg" BU_SG_REL_ BCM_HS SG_ 479 EASSI_UnsdRsrvd2 479;
BA_REL_ "GenSigSuprvResp" BU_SG_REL_ BCM_HS SG_ 479 EASSI_UnsdRsrvd2 1;
BA_REL_ "GenSigTimeoutTime" BU_SG_REL_ ECM_HS SG_ 479 EASSI_UnsdRsrvd2 250;
BA_REL_ "GenSigTimeoutMsg" BU_SG_REL_ ECM_HS SG_ 479 EASSI_UnsdRsrvd2 479;
BA_REL_ "GenSigSuprvResp" BU_SG_REL_ ECM_HS SG_ 479 EASSI_UnsdRsrvd2 1;
BA_REL_ "GenSigTimeoutTime" BU_SG_REL_ EBCM_OBD_HS SG_ 479 EASSI_StlDetd 250;
BA_REL_ "GenSigTimeoutMsg" BU_SG_REL_ EBCM_OBD_HS SG_ 479 EASSI_StlDetd 479;
BA_REL_ "GenSigSuprvResp" BU_SG_REL_ EBCM_OBD_HS SG_ 479 EASSI_StlDetd 1;
BA_REL_ "GenSigTimeoutTime" BU_SG_REL_ TCCM_HS SG_ 479 EASSI_StlDetd 250;
BA_REL_ "GenSigTimeoutMsg" BU_SG_REL_ TCCM_HS SG_ 479 EASSI_StlDetd 479;
BA_REL_ "GenSigSuprvResp" BU_SG_REL_ TCCM_HS SG_ 479 EASSI_StlDetd 1;
BA_REL_ "GenSigTimeoutTime" BU_SG_REL_ EBCM_HS SG_ 479 EASSI_StlDetd 250;
BA_REL_ "GenSigTimeoutMsg" BU_SG_REL_ EBCM_HS SG_ 479 EASSI_StlDetd 479;
BA_REL_ "GenSigSuprvResp" BU_SG_REL_ EBCM_HS SG_ 479 EASSI_StlDetd 1;
BA_REL_ "GenSigTimeoutTime" BU_SG_REL_ TCM_HS SG_ 479 EASSI_StlDetd 250;
BA_REL_ "GenSigTimeoutMsg" BU_SG_REL_ TCM_HS SG_ 479 EASSI_StlDetd 479;
BA_REL_ "GenSigSuprvResp" BU_SG_REL_ TCM_HS SG_ 479 EASSI_StlDetd 1;
BA_REL_ "GenSigTimeoutTime" BU_SG_REL_ BCM_HS SG_ 479 EASSI_StlDetd 250;
BA_REL_ "GenSigTimeoutMsg" BU_SG_REL_ BCM_HS SG_ 479 EASSI_StlDetd 479;
BA_REL_ "GenSigSuprvResp" BU_SG_REL_ BCM_HS SG_ 479 EASSI_StlDetd 1;
BA_REL_ "GenSigTimeoutTime" BU_SG_REL_ ECM_HS SG_ 479 EASSI_StlDetd 250;
BA_REL_ "GenSigTimeoutMsg" BU_SG_REL_ ECM_HS SG_ 479 EASSI_StlDetd 479;
BA_REL_ "GenSigSuprvResp" BU_SG_REL_ ECM_HS SG_ 479 EASSI_StlDetd 1;
BA_REL_ "GenSigTimeoutTime" BU_SG_REL_ EBCM_OBD_HS SG_ 479 EASSI_TrqDetd 250;
BA_REL_ "GenSigTimeoutMsg" BU_SG_REL_ EBCM_OBD_HS SG_ 479 EASSI_TrqDetd 479;
BA_REL_ "GenSigSuprvResp" BU_SG_REL_ EBCM_OBD_HS SG_ 479 EASSI_TrqDetd 1;
BA_REL_ "GenSigTimeoutTime" BU_SG_REL_ TCCM_HS SG_ 479 EASSI_TrqDetd 250;
BA_REL_ "GenSigTimeoutMsg" BU_SG_REL_ TCCM_HS SG_ 479 EASSI_TrqDetd 479;
BA_REL_ "GenSigSuprvResp" BU_SG_REL_ TCCM_HS SG_ 479 EASSI_TrqDetd 1;
BA_REL_ "GenSigTimeoutTime" BU_SG_REL_ EBCM_HS SG_ 479 EASSI_TrqDetd 250;
BA_REL_ "GenSigTimeoutMsg" BU_SG_REL_ EBCM_HS SG_ 479 EASSI_TrqDetd 479;
BA_REL_ "GenSigSuprvResp" BU_SG_REL_ EBCM_HS SG_ 479 EASSI_TrqDetd 1;
BA_REL_ "GenSigTimeoutTime" BU_SG_REL_ TCM_HS SG_ 479 EASSI_TrqDetd 250;
BA_REL_ "GenSigTimeoutMsg" BU_SG_REL_ TCM_HS SG_ 479 EASSI_TrqDetd 479;
BA_REL_ "GenSigSuprvResp" BU_SG_REL_ TCM_HS SG_ 479 EASSI_TrqDetd 1;
BA_REL_ "GenSigTimeoutTime" BU_SG_REL_ BCM_HS SG_ 479 EASSI_TrqDetd 250;
BA_REL_ "GenSigTimeoutMsg" BU_SG_REL_ BCM_HS SG_ 479 EASSI_TrqDetd 479;
BA_REL_ "GenSigSuprvResp" BU_SG_REL_ BCM_HS SG_ 479 EASSI_TrqDetd 1;
BA_REL_ "GenSigTimeoutTime" BU_SG_REL_ ECM_HS SG_ 479 EASSI_TrqDetd 250;
BA_REL_ "GenSigTimeoutMsg" BU_SG_REL_ ECM_HS SG_ 479 EASSI_TrqDetd 479;
BA_REL_ "GenSigSuprvResp" BU_SG_REL_ ECM_HS SG_ 479 EASSI_TrqDetd 1;
BA_REL_ "GenSigTimeoutTime" BU_SG_REL_ EBCM_OBD_HS SG_ 479 EASSI_FuelReqOn 250;
BA_REL_ "GenSigTimeoutMsg" BU_SG_REL_ EBCM_OBD_HS SG_ 479 EASSI_FuelReqOn 479;
BA_REL_ "GenSigSuprvResp" BU_SG_REL_ EBCM_OBD_HS SG_ 479 EASSI_FuelReqOn 1;
BA_REL_ "GenSigTimeoutTime" BU_SG_REL_ TCCM_HS SG_ 479 EASSI_FuelReqOn 250;
BA_REL_ "GenSigTimeoutMsg" BU_SG_REL_ TCCM_HS SG_ 479 EASSI_FuelReqOn 479;
BA_REL_ "GenSigSuprvResp" BU_SG_REL_ TCCM_HS SG_ 479 EASSI_FuelReqOn 1;
BA_REL_ "GenSigTimeoutTime" BU_SG_REL_ EBCM_HS SG_ 479 EASSI_FuelReqOn 250;
BA_REL_ "GenSigTimeoutMsg" BU_SG_REL_ EBCM_HS SG_ 479 EASSI_FuelReqOn 479;
BA_REL_ "GenSigSuprvResp" BU_SG_REL_ EBCM_HS SG_ 479 EASSI_FuelReqOn 1;
BA_REL_ "GenSigTimeoutTime" BU_SG_REL_ TCM_HS SG_ 479 EASSI_FuelReqOn 250;
BA_REL_ "GenSigTimeoutMsg" BU_SG_REL_ TCM_HS SG_ 479 EASSI_FuelReqOn 479;
BA_REL_ "GenSigSuprvResp" BU_SG_REL_ TCM_HS SG_ 479 EASSI_FuelReqOn 1;
BA_REL_ "GenSigTimeoutTime" BU_SG_REL_ BCM_HS SG_ 479 EASSI_FuelReqOn 250;
BA_REL_ "GenSigTimeoutMsg" BU_SG_REL_ BCM_HS SG_ 479 EASSI_FuelReqOn 479;
BA_REL_ "GenSigSuprvResp" BU_SG_REL_ BCM_HS SG_ 479 EASSI_FuelReqOn 1;
BA_REL_ "GenSigTimeoutTime" BU_SG_REL_ ECM_HS SG_ 479 EASSI_FuelReqOn 250;
BA_REL_ "GenSigTimeoutMsg" BU_SG_REL_ ECM_HS SG_ 479 EASSI_FuelReqOn 479;
BA_REL_ "GenSigSuprvResp" BU_SG_REL_ ECM_HS SG_ 479 EASSI_FuelReqOn 1;
BA_REL_ "GenSigTimeoutTime" BU_SG_REL_ EBCM_OBD_HS SG_ 479 EASSI_StrtTyp 250;
BA_REL_ "GenSigTimeoutMsg" BU_SG_REL_ EBCM_OBD_HS SG_ 479 EASSI_StrtTyp 479;
BA_REL_ "GenSigSuprvResp" BU_SG_REL_ EBCM_OBD_HS SG_ 479 EASSI_StrtTyp 1;
BA_REL_ "GenSigTimeoutTime" BU_SG_REL_ TCCM_HS SG_ 479 EASSI_StrtTyp 250;
BA_REL_ "GenSigTimeoutMsg" BU_SG_REL_ TCCM_HS SG_ 479 EASSI_StrtTyp 479;
BA_REL_ "GenSigSuprvResp" BU_SG_REL_ TCCM_HS SG_ 479 EASSI_StrtTyp 1;
BA_REL_ "GenSigTimeoutTime" BU_SG_REL_ EBCM_HS SG_ 479 EASSI_StrtTyp 250;
BA_REL_ "GenSigTimeoutMsg" BU_SG_REL_ EBCM_HS SG_ 479 EASSI_StrtTyp 479;
BA_REL_ "GenSigSuprvResp" BU_SG_REL_ EBCM_HS SG_ 479 EASSI_StrtTyp 1;
BA_REL_ "GenSigTimeoutTime" BU_SG_REL_ TCM_HS SG_ 479 EASSI_StrtTyp 250;
BA_REL_ "GenSigTimeoutMsg" BU_SG_REL_ TCM_HS SG_ 479 EASSI_StrtTyp 479;
BA_REL_ "GenSigSuprvResp" BU_SG_REL_ TCM_HS SG_ 479 EASSI_StrtTyp 1;
BA_REL_ "GenSigTimeoutTime" BU_SG_REL_ BCM_HS SG_ 479 EASSI_StrtTyp 250;
BA_REL_ "GenSigTimeoutMsg" BU_SG_REL_ BCM_HS SG_ 479 EASSI_StrtTyp 479;
BA_REL_ "GenSigSuprvResp" BU_SG_REL_ BCM_HS SG_ 479 EASSI_StrtTyp 1;
BA_REL_ "GenSigTimeoutTime" BU_SG_REL_ ECM_HS SG_ 479 EASSI_StrtTyp 250;
BA_REL_ "GenSigTimeoutMsg" BU_SG_REL_ ECM_HS SG_ 479 EASSI_StrtTyp 479;
BA_REL_ "GenSigSuprvResp" BU_SG_REL_ ECM_HS SG_ 479 EASSI_StrtTyp 1;
BA_REL_ "GenSigTimeoutTime" BU_SG_REL_ EBCM_OBD_HS SG_ 479 EASSI_StrtStpSt 250;
BA_REL_ "GenSigTimeoutMsg" BU_SG_REL_ EBCM_OBD_HS SG_ 479 EASSI_StrtStpSt 479;
BA_REL_ "GenSigSuprvResp" BU_SG_REL_ EBCM_OBD_HS SG_ 479 EASSI_StrtStpSt 1;
BA_REL_ "GenSigTimeoutTime" BU_SG_REL_ TCCM_HS SG_ 479 EASSI_StrtStpSt 250;
BA_REL_ "GenSigTimeoutMsg" BU_SG_REL_ TCCM_HS SG_ 479 EASSI_StrtStpSt 479;
BA_REL_ "GenSigSuprvResp" BU_SG_REL_ TCCM_HS SG_ 479 EASSI_StrtStpSt 1;
BA_REL_ "GenSigTimeoutTime" BU_SG_REL_ EBCM_HS SG_ 479 EASSI_StrtStpSt 250;
BA_REL_ "GenSigTimeoutMsg" BU_SG_REL_ EBCM_HS SG_ 479 EASSI_StrtStpSt 479;
BA_REL_ "GenSigSuprvResp" BU_SG_REL_ EBCM_HS SG_ 479 EASSI_StrtStpSt 1;
BA_REL_ "GenSigTimeoutTime" BU_SG_REL_ TCM_HS SG_ 479 EASSI_StrtStpSt 250;
BA_REL_ "GenSigTimeoutMsg" BU_SG_REL_ TCM_HS SG_ 479 EASSI_StrtStpSt 479;
BA_REL_ "GenSigSuprvResp" BU_SG_REL_ TCM_HS SG_ 479 EASSI_StrtStpSt 1;
BA_REL_ "GenSigTimeoutTime" BU_SG_REL_ BCM_HS SG_ 479 EASSI_StrtStpSt 250;
BA_REL_ "GenSigTimeoutMsg" BU_SG_REL_ BCM_HS SG_ 479 EASSI_StrtStpSt 479;
BA_REL_ "GenSigSuprvResp" BU_SG_REL_ BCM_HS SG_ 479 EASSI_StrtStpSt 1;
BA_REL_ "GenSigTimeoutTime" BU_SG_REL_ ECM_HS SG_ 479 EASSI_StrtStpSt 250;
BA_REL_ "GenSigTimeoutMsg" BU_SG_REL_ ECM_HS SG_ 479 EASSI_StrtStpSt 479;
BA_REL_ "GenSigSuprvResp" BU_SG_REL_ ECM_HS SG_ 479 EASSI_StrtStpSt 1;
BA_REL_ "GenSigTimeoutTime" BU_SG_REL_ EBCM_OBD_HS SG_ 479 EASSI_TorqDetdIndet 250;
BA_REL_ "GenSigTimeoutMsg" BU_SG_REL_ EBCM_OBD_HS SG_ 479 EASSI_TorqDetdIndet 479;
BA_REL_ "GenSigSuprvResp" BU_SG_REL_ EBCM_OBD_HS SG_ 479 EASSI_TorqDetdIndet 1;
BA_REL_ "GenSigTimeoutTime" BU_SG_REL_ TCCM_HS SG_ 479 EASSI_TorqDetdIndet 250;
BA_REL_ "GenSigTimeoutMsg" BU_SG_REL_ TCCM_HS SG_ 479 EASSI_TorqDetdIndet 479;
BA_REL_ "GenSigSuprvResp" BU_SG_REL_ TCCM_HS SG_ 479 EASSI_TorqDetdIndet 1;
BA_REL_ "GenSigTimeoutTime" BU_SG_REL_ EBCM_HS SG_ 479 EASSI_TorqDetdIndet 250;
BA_REL_ "GenSigTimeoutMsg" BU_SG_REL_ EBCM_HS SG_ 479 EASSI_TorqDetdIndet 479;
BA_REL_ "GenSigSuprvResp" BU_SG_REL_ EBCM_HS SG_ 479 EASSI_TorqDetdIndet 1;
BA_REL_ "GenSigTimeoutTime" BU_SG_REL_ TCM_HS SG_ 479 EASSI_TorqDetdIndet 250;
BA_REL_ "GenSigTimeoutMsg" BU_SG_REL_ TCM_HS SG_ 479 EASSI_TorqDetdIndet 479;
BA_REL_ "GenSigSuprvResp" BU_SG_REL_ TCM_HS SG_ 479 EASSI_TorqDetdIndet 1;
BA_REL_ "GenSigTimeoutTime" BU_SG_REL_ BCM_HS SG_ 479 EASSI_TorqDetdIndet 250;
BA_REL_ "GenSigTimeoutMsg" BU_SG_REL_ BCM_HS SG_ 479 EASSI_TorqDetdIndet 479;
BA_REL_ "GenSigSuprvResp" BU_SG_REL_ BCM_HS SG_ 479 EASSI_TorqDetdIndet 1;
BA_REL_ "GenSigTimeoutTime" BU_SG_REL_ ECM_HS SG_ 479 EASSI_TorqDetdIndet 250;
BA_REL_ "GenSigTimeoutMsg" BU_SG_REL_ ECM_HS SG_ 479 EASSI_TorqDetdIndet 479;
BA_REL_ "GenSigSuprvResp" BU_SG_REL_ ECM_HS SG_ 479 EASSI_TorqDetdIndet 1;
BA_REL_ "GenSigTimeoutTime" BU_SG_REL_ BCM_HS SG_ 479 ASIRI_Indication08 62;
BA_REL_ "GenSigTimeoutMsg" BU_SG_REL_ BCM_HS SG_ 479 ASIRI_Indication08 479;
BA_REL_ "GenSigSuprvResp" BU_SG_REL_ BCM_HS SG_ 479 ASIRI_Indication08 1;
BA_REL_ "GenSigTimeoutTime" BU_SG_REL_ BCM_HS SG_ 479 ASIRI_Indication07 62;
BA_REL_ "GenSigTimeoutMsg" BU_SG_REL_ BCM_HS SG_ 479 ASIRI_Indication07 479;
BA_REL_ "GenSigSuprvResp" BU_SG_REL_ BCM_HS SG_ 479 ASIRI_Indication07 1;
BA_REL_ "GenSigTimeoutTime" BU_SG_REL_ BCM_HS SG_ 479 ASIRI_Indication06 62;
BA_REL_ "GenSigTimeoutMsg" BU_SG_REL_ BCM_HS SG_ 479 ASIRI_Indication06 479;
BA_REL_ "GenSigSuprvResp" BU_SG_REL_ BCM_HS SG_ 479 ASIRI_Indication06 1;
BA_REL_ "GenSigTimeoutTime" BU_SG_REL_ BCM_HS SG_ 479 ASIRI_Indication05 62;
BA_REL_ "GenSigTimeoutMsg" BU_SG_REL_ BCM_HS SG_ 479 ASIRI_Indication05 479;
BA_REL_ "GenSigSuprvResp" BU_SG_REL_ BCM_HS SG_ 479 ASIRI_Indication05 1;
BA_REL_ "GenSigTimeoutTime" BU_SG_REL_ BCM_HS SG_ 479 ASIRI_Indication04 62;
BA_REL_ "GenSigTimeoutMsg" BU_SG_REL_ BCM_HS SG_ 479 ASIRI_Indication04 479;
BA_REL_ "GenSigSuprvResp" BU_SG_REL_ BCM_HS SG_ 479 ASIRI_Indication04 1;
BA_REL_ "GenSigTimeoutTime" BU_SG_REL_ BCM_HS SG_ 479 ASIRI_Indication03 62;
BA_REL_ "GenSigTimeoutMsg" BU_SG_REL_ BCM_HS SG_ 479 ASIRI_Indication03 479;
BA_REL_ "GenSigSuprvResp" BU_SG_REL_ BCM_HS SG_ 479 ASIRI_Indication03 1;
BA_REL_ "GenSigTimeoutTime" BU_SG_REL_ BCM_HS SG_ 479 ASIRI_Indication02 62;
BA_REL_ "GenSigTimeoutMsg" BU_SG_REL_ BCM_HS SG_ 479 ASIRI_Indication02 479;
BA_REL_ "GenSigSuprvResp" BU_SG_REL_ BCM_HS SG_ 479 ASIRI_Indication02 1;
BA_REL_ "GenSigTimeoutTime" BU_SG_REL_ BCM_HS SG_ 479 ASIRI_Indication01 62;
BA_REL_ "GenSigTimeoutMsg" BU_SG_REL_ BCM_HS SG_ 479 ASIRI_Indication01 479;
BA_REL_ "GenSigSuprvResp" BU_SG_REL_ BCM_HS SG_ 479 ASIRI_Indication01 1;
BA_REL_ "GenSigTimeoutTime" BU_SG_REL_ BCM_HS SG_ 479 PTWrmgWtToShftIO 250;
BA_REL_ "GenSigTimeoutMsg" BU_SG_REL_ BCM_HS SG_ 479 PTWrmgWtToShftIO 479;
BA_REL_ "GenSigSuprvResp" BU_SG_REL_ BCM_HS SG_ 479 PTWrmgWtToShftIO 1;
BA_REL_ "GenSigTimeoutTime" BU_SG_REL_ ICCM_OBD_HS SG_ 479 PrplsnSysAtv 250;
BA_REL_ "GenSigTimeoutMsg" BU_SG_REL_ ICCM_OBD_HS SG_ 479 PrplsnSysAtv 479;
BA_REL_ "GenSigSuprvResp" BU_SG_REL_ ICCM_OBD_HS SG_ 479 PrplsnSysAtv 1;
BA_REL_ "GenSigTimeoutTime" BU_SG_REL_ ICCM_HS SG_ 479 PrplsnSysAtv 250;
BA_REL_ "GenSigTimeoutMsg" BU_SG_REL_ ICCM_HS SG_ 479 PrplsnSysAtv 479;
BA_REL_ "GenSigSuprvResp" BU_SG_REL_ ICCM_HS SG_ 479 PrplsnSysAtv 1;
BA_REL_ "GenSigTimeoutTime" BU_SG_REL_ EPB_HS SG_ 479 PrplsnSysAtv 250;
BA_REL_ "GenSigTimeoutMsg" BU_SG_REL_ EPB_HS SG_ 479 PrplsnSysAtv 479;
BA_REL_ "GenSigSuprvResp" BU_SG_REL_ EPB_HS SG_ 479 PrplsnSysAtv 1;
BA_REL_ "GenSigTimeoutTime" BU_SG_REL_ BCM_HS SG_ 479 PTShftLvrLckRqd 250;
BA_REL_ "GenSigTimeoutMsg" BU_SG_REL_ BCM_HS SG_ 479 PTShftLvrLckRqd 479;
BA_REL_ "GenSigSuprvResp" BU_SG_REL_ BCM_HS SG_ 479 PTShftLvrLckRqd 1;
BA_REL_ "GenSigTimeoutTime" BU_SG_REL_ CGM_HS SG_ 211 ActAxleTrq 250;
BA_REL_ "GenSigTimeoutMsg" BU_SG_REL_ CGM_HS SG_ 211 ActAxleTrq 211;
BA_REL_ "GenSigSuprvResp" BU_SG_REL_ CGM_HS SG_ 211 ActAxleTrq 1;
BA_REL_ "GenSigTimeoutTime" BU_SG_REL_ EPS_HS SG_ 211 ActAxleTrq 250;
BA_REL_ "GenSigTimeoutMsg" BU_SG_REL_ EPS_HS SG_ 211 ActAxleTrq 211;
BA_REL_ "GenSigSuprvResp" BU_SG_REL_ EPS_HS SG_ 211 ActAxleTrq 1;
BA_REL_ "GenSigTimeoutTime" BU_SG_REL_ TCM_HS SG_ 1020 OtsAirTmpCrVal 625;
BA_REL_ "GenSigTimeoutMsg" BU_SG_REL_ TCM_HS SG_ 1020 OtsAirTmpCrVal 1020;
BA_REL_ "GenSigSuprvResp" BU_SG_REL_ TCM_HS SG_ 1020 OtsAirTmpCrVal 1;
VAL_ 197 WRSLNDWhlRotStRst 1 "true" 0 "false" ;
VAL_ 197 WRSLNDWhlDistVal 1 "Invalid" 0 "Valid" ;
VAL_ 197 WRSRNDWhlRotStRst 1 "true" 0 "false" ;
VAL_ 197 WRSRNDWhlDistVal 1 "Invalid" 0 "Valid" ;
VAL_ 1009 EngOffTmVDA 1 "VirtualDeviceAvailable" 0 "VirtualDeviceUnavailable" ;
VAL_ 1009 EngOffTmExtRngV 1 "Invalid" 0 "Valid" ;
VAL_ 1009 RstrctdPTOpModeReqd 1 "true" 0 "false" ;
VAL_ 1009 ClmtCtrlHtrEngRunRq 1 "Engine Run Requested" 0 "No Action" ;
VAL_ 1009 OtsAirTmpCrValMsk 0 "Don't Use Data" 1 "Use Data" ;
VAL_ 1009 ACCmEngRunReq 1 "Engine Run Requested" 0 "No Action" ;
VAL_ 1009 OutAirTempVDA 1 "VirtualDeviceAvailable" 0 "VirtualDeviceUnavailable" ;
VAL_ 1009 OtsAirTmpCrValV 1 "Invalid" 0 "Valid" ;
VAL_ 1009 ClntCircPmpRq 1 "On" 0 "Off" ;
VAL_ 1009 PF_MinIdlBstLvlReq 3 "Boost Level 3" 2 "Boost Level 2" 1 "Boost Level 1" 0 "No Boost Requested" ;
VAL_ 1257 ElpsdTimeCntRstOcc 1 "true" 0 "false" ;
VAL_ 1257 VSESysPrs 1 "true" 0 "false" ;
VAL_ 1257 ABSPr 1 "true" 0 "false" ;
VAL_ 1257 TCSysPr 1 "true" 0 "false" ;
VAL_ 1257 VehSpdCntlSystmType 2 "Adaptive Cruise Control" 1 "Conventional Cruise Control" 0 "No Vehicle Speed Control" ;
VAL_ 1257 PltfrmEngSpdCmdSysTp 6 "Auto Elevated Idle" 5 "Enhanced Fast Idle" 4 "Fast Idle" 3 "Mobile Variable PTO" 2 "Stationary Variable PTO" 1 "Stationary PTO" 0 "No Platform Eng. Speed Command Sys." ;
VAL_ 505 AllNodesVNA_1F9 1 "Activate Virtual Network" 0 "No Activation" ;
VAL_ 505 PTORmtEngStrtReq 1 "PTO Remote Start Requested" 0 "PTO Remote Start Not Requested" ;
VAL_ 505 PTOTGRReqdGear 8 "Eighth Gear" 7 "Seventh Gear" 6 "Sixth Gear" 5 "Fifth Gear" 4 "Fourth Gear" 3 "Third Gear" 2 "Second Gear" 1 "First Gear" 0 "No Action" ;
VAL_ 505 PTOTGRReqType 3 "Hold Gear" 2 "Min Gear Request" 1 "Max Gear Request" 0 "No Action" ;
VAL_ 505 TrnsPTOCltchRelRqd 1 "true" 0 "false" ;
VAL_ 505 AccPdlPwrTkOffOvrAct 1 "true" 0 "false" ;
VAL_ 505 FstIdlMdAct 1 "true" 0 "false" ;
VAL_ 505 PTOMdAct 1 "true" 0 "false" ;
VAL_ 505 PTOEngTrqLmtRchd 1 "true" 0 "false" ;
VAL_ 505 PltfrmEngSpdCmdMdAct 1 "true" 0 "false" ;
VAL_ 505 PFESpdCmdOnSwAct 1 "true" 0 "false" ;
VAL_ 505 PFESpdCmdDeSwAct 1 "true" 0 "false" ;
VAL_ 505 PFESpdCmdInSwAct 1 "true" 0 "false" ;
VAL_ 505 PFESpdCmdSwDIntg 2 "Failure Detected" 1 "Data Invalid" 0 "Data Valid" ;
VAL_ 505 PTORmtEngShtdwnReqd 1 "true" 0 "false" ;
VAL_ 497 BkupPwrModeMstrVDA 1 "VirtualDeviceAvailable" 0 "VirtualDeviceUnavailable" ;
VAL_ 497 PrkBrkVDA 1 "VirtualDeviceAvailable" 0 "VirtualDeviceUnavailable" ;
VAL_ 497 PrkBrkVDM 1 "Use Data" 0 "Don't Use Data" ;
VAL_ 497 BkupPwrModeMstrVDM 1 "Use Data" 0 "Don't Use Data" ;
VAL_ 497 ACCompSysVDM 1 "Use Data" 0 "Don't Use Data" ;
VAL_ 497 ElvtdIdlCstStReq 0 "No Action" 1 "Off" 2 "On" ;
VAL_ 497 FuelFltLfRstRqd 1 "true" 0 "false" ;
VAL_ 497 ACCompSysVDA 1 "VirtualDeviceAvailable" 0 "VirtualDeviceUnavailable" ;
VAL_ 497 AirbgVDA 1 "VirtualDeviceAvailable" 0 "VirtualDeviceUnavailable" ;
VAL_ 497 SysBkupPwrMdEn 1 "true" 0 "false" ;
VAL_ 497 SysBkUpPwrMd 3 "Crank Request" 2 "Run" 1 "Accessory" 0 "Off" ;
VAL_ 497 SysPwrMd 3 "Crank Request" 2 "Run" 1 "Accessory" 0 "Off" ;
VAL_ 497 TrStLgMdAtv 1 "true" 0 "false" ;
VAL_ 497 DispMeasSys 1 "English" 0 "Metric" ;
VAL_ 497 ACCmpsrFldOn 1 "true" 0 "false" ;
VAL_ 497 ACCompModReq 3 "No Action" 2 "Engage" 1 "Disengage" 0 "Disengage Immediately" ;
VAL_ 497 ACCompNormLdV 1 "Invalid" 0 "Valid" ;
VAL_ 497 PTORSMstrEngShtReq 1 "true" 0 "false" ;
VAL_ 497 EngOilLfRstRq 1 "true" 0 "false" ;
VAL_ 497 SIRDpl 1 "true" 0 "false" ;
VAL_ 497 PTORmStMsEngStRq 1 "PTO Remote Start Requested" 0 "PTO Remote Start Not Requested" ;
VAL_ 497 RmVehStrRq 1 "Remote Start Requested" 0 "Remote Start Not Requested" ;
VAL_ 497 ThrtlPrgrsnReq 2 "Map C" 1 "Map B" 0 "Map A" ;
VAL_ 497 PrkBrkSwAtv 1 "true" 0 "false" ;
VAL_ 497 PMMAccTrmSt 1 "Active" 0 "Inactive" ;
VAL_ 497 PMMRunCrkTrmSt 1 "Active" 0 "Inactive" ;
VAL_ 497 ImmblzrPreRelPswdStat 1 "Information Valid" 0 "No Information" ;
VAL_ 193 WRSLDWhlDistVal 1 "Invalid" 0 "Valid" ;
VAL_ 193 WRSLDWhlRotStatRst 1 "true" 0 "false" ;
VAL_ 193 WRSRDWhlRotStatRst 1 "true" 0 "false" ;
VAL_ 193 WRSRDWhlDistVal 1 "Invalid" 0 "Valid" ;
VAL_ 481 AdptCrsGapSwAct 2 "Increase Gap" 1 "Decrease Gap" 0 "No Activation" ;
VAL_ 481 CrsSecSwStat 15 "Unused and Reserved 7" 14 "Unused and Reserved 6" 13 "Unused and Reserved 5" 12 "Unused and Reserved 4" 11 "Unused and Reserved 3" 10 "Unused and Reserved 2" 9 "Between Ranges" 8 "Short to Power" 7 "Open/Short to Ground" 6 "Speed Decrease High" 5 "Speed Increase High" 4 "Gap Up" 3 "Gap Down" 2 "Unused and Reserved 1" 1 "No Activation" 0 "state0805" ;
VAL_ 481 DrvSelMdSw3Sta 1 "Active" 0 "Inactive" ;
VAL_ 481 DrvSelMdSw2Sta 1 "Active" 0 "Inactive" ;
VAL_ 481 AuxHtrRq 1 "On" 0 "Off" ;
VAL_ 481 AuxHtrAtv 1 "true" 0 "false" ;
VAL_ 481 DrvSelMdSw1Sta 1 "Active" 0 "Inactive" ;
VAL_ 481 FuelMdSwActV 1 "Invalid" 0 "Valid" ;
VAL_ 481 FuelMdSwAct 1 "True" 0 "False" ;
VAL_ 481 CrsSpdLmtrSwStat 2 "Resume" 1 "No Activation" 9 "Between Ranges" 8 "Short to Power" 7 "Open/Short to Ground" 6 "Cancel" 5 "Cruise On/Off" 4 "SL/SW On/Off/GAP" 3 "Set" 0 "state0805" ;
VAL_ 481 CrsCntrlSwStCanSwAct 1 "true" 0 "false" ;
VAL_ 481 CrsCntrlSwStSwDataIntgty 3 "Illegal Range" 2 "Failure Detected" 1 "Data Invalid" 0 "Data Valid" ;
VAL_ 481 CrsCntrlSwStSpdInSwAct 1 "true" 0 "false" ;
VAL_ 481 CrsCntrlSwStSpDcSwAct 1 "true" 0 "false" ;
VAL_ 481 CrsCntrlSwStSetSwAct 1 "true" 0 "false" ;
VAL_ 481 CrsCntrlSwStResSwAct 1 "true" 0 "false" ;
VAL_ 481 CrsCntrlSwStOnSwAct 1 "true" 0 "false" ;
VAL_ 481 CrsCntCncRq 1 "Cancel" 0 "Do Not Cancel" ;
VAL_ 455 CSETRER_TqIntvnTyp 2 "Increase Torque" 1 "Reduce Torque" 0 "No Intervention" ;
VAL_ 761 SprTireSt 2 "Spare Detected" 1 "No Spare Detected" 0 "Undetermined" ;
VAL_ 761 BrkSysHRBkCtrlAvail 1 "true" 0 "false" ;
VAL_ 761 BrkSysHRBkCtrlStat 0 "Inactive" 1 "Control Target Vehicle Speed" 2 "Unused and Reserved 1" 3 "Unused and Reserved 2" ;
VAL_ 761 BrkSysHSAAval 1 "true" 0 "false" ;
VAL_ 761 BrkSysHSAStat 0 "Inactive" 1 "Brake Pressure Hold" 2 "Normal Pressure Decay" 3 "Drive-off Pressure Decay" ;
VAL_ 761 HillDscntCtrlStat 0 "Not Enabled" 1 "Enabled" 2 "Active" 3 "Unused" ;
VAL_ 761 ABFI_CollPrepSysInhbt 1 "true" 0 "false" ;
VAL_ 761 ABFI_RrVirtlBmprInh 1 "true" 0 "false" ;
VAL_ 761 BrkPdlDrvApplPresV 1 "Invalid" 0 "Valid" ;
VAL_ 761 AutoBrkPTReqStat 0 "Inactive" 1 "Active" 2 "Failed" 3 "Serial Communication Failure" 4 "Unused and Reserved 1" 5 "Unused and Reserved 2" 6 "Unused and Reserved 3" 7 "Unused and Reserved 4" ;
VAL_ 761 WhlSpdSnsgDTCStat 4 "Diagnostic Failed" 3 "Diagnostic Passed" 2 "No Status to Report" 1 "Critically Disabled" 0 "Not Supported" ;
VAL_ 489 VehDynYawRateV 1 "Invalid" 0 "Valid" ;
VAL_ 489 BSTGRReqdGear 8 "Eighth Gear" 7 "Seventh Gear" 6 "Sixth Gear" 5 "Fifth Gear" 4 "Fourth Gear" 3 "Third Gear" 2 "Second Gear" 1 "First Gear" 0 "No Action" ;
VAL_ 489 BSTGRReqType 3 "Hold Gear" 2 "Min Gear Request" 1 "Max Gear Request" 0 "No Action" ;
VAL_ 489 TrnsBrkSysCltchRelRqd 1 "true" 0 "false" ;
VAL_ 489 EnhDrvMdSwChUseRq 1 "true" 0 "false" ;
VAL_ 489 DrvIndpntBrkAppAct 1 "true" 0 "false" ;
VAL_ 489 WhlSlpSt 3 "Slip Detection Fault" 2 "Positive Slip Detected" 1 "Negative Slip Detected" 0 "No Slip Detected" ;
VAL_ 489 VSELatAccV 1 "Invalid" 0 "Valid" ;
VAL_ 489 VSEAct 1 "true" 0 "false" ;
VAL_ 489 VhDynCntlSysSt 7 "Driver Disabled" 6 "Enhanced Operation" 5 "Calibrating" 4 "Warming Up" 3 "Permanently Failed" 2 "Temporarily Inhibited" 1 "Reduced Function" 0 "Normal Operation" ;
VAL_ 489 TracCntrlSysDrIntnt 1 "Enabled" 0 "Disabled" ;
VAL_ 489 TCSysEnbld 1 "true" 0 "false" ;
VAL_ 489 TCSysAtv 1 "true" 0 "false" ;
VAL_ 489 BrkPdlDrvAppPrsDetcdV 1 "Invalid" 0 "Valid" ;
VAL_ 489 BrkPdlDrvAppPrsDetcd 1 "true" 0 "false" ;
VAL_ 489 ACCBrkngAct 1 "true" 0 "false" ;
VAL_ 489 ABSFld 1 "true" 0 "false" ;
VAL_ 489 ABSAtv 1 "true" 0 "false" ;
VAL_ 489 IMUDataMsk 1 "true" 0 "false" ;
VAL_ 489 VehDynOvrUndrStrV 1 "Invalid" 0 "Valid" ;
VAL_ 381 HillDesCtrlRedVehSpIO 1 "true" 0 "false" ;
VAL_ 381 EBDFailed 1 "true" 0 "false" ;
VAL_ 381 StWhAnVDA 1 "VirtualDeviceAvailable" 0 "VirtualDeviceUnavailable" ;
VAL_ 381 TirePrsLowIO 1 "true" 0 "false" ;
VAL_ 381 VaccBoostFailure 1 "true" 0 "false" ;
VAL_ 381 VSESysPrs 1 "true" 0 "false" ;
VAL_ 381 HalfSysFail 1 "true" 0 "false" ;
VAL_ 381 BksOvht 1 "true" 0 "false" ;
VAL_ 381 TCSysPr 1 "true" 0 "false" ;
VAL_ 381 ABSPr 1 "true" 0 "false" ;
VAL_ 381 TreInfMonSysRstPrfmd 1 "true" 0 "false" ;
VAL_ 381 ABSIO 1 "true" 0 "false" ;
VAL_ 381 BrkPadWrnIO 1 "true" 0 "false" ;
VAL_ 381 VehStabEnhmntMd 2 "Competitive" 1 "Normal" 0 "Off" ;
VAL_ 381 VehStabEnhmntStat 4 "Not Ready" 3 "Warming Up" 2 "Fault" 1 "Active" 0 "Inactive" ;
VAL_ 381 TCSysOpMd 2 "state0624" 1 "Normal" 0 "Off" ;
VAL_ 381 TCSysOpStat 2 "Fault" 1 "Active" 0 "Inactive" ;
VAL_ 381 BrkSysRedBrkTlltlReq 1 "true" 0 "false" ;
VAL_ 381 BrkSysBrkLtsReqd 1 "true" 0 "false" ;
VAL_ 381 ActVehAccelV 1 "Invalid" 0 "Valid" ;
VAL_ 241 NotEventStat 2 "Pretensioner Deployment Event" 1 "Near Deployment Event" 0 "No Event" 3 "Airbag Deployment Event" ;
VAL_ 241 BrkAppSnsrHmPosLrnd 1 "true" 0 "false" ;
VAL_ 241 BrkPedTrvlAchvd 1 "true" 0 "false" ;
VAL_ 241 BrkPedTrvlAchvdV 1 "Invalid" 0 "Valid" ;
VAL_ 241 BrkPdlModTrvlV 1 "Invalid" 0 "Valid" ;
VAL_ 241 BrkPdlModTrvl 1 "true" 0 "false" ;
VAL_ 1271 BatSvrMdLvl7Act 1 "true" 0 "false" ;
VAL_ 1271 BSMCT_Mult 3 "Multiplier Factor 256" 2 "Multiplier Factor 64" 1 "Multiplier Factor 8" 0 "Multiplier Factor 1" ;
VAL_ 1271 BatSvrMdLvl6Act 1 "true" 0 "false" ;
VAL_ 1271 BatSvrMdLvl5Act 1 "true" 0 "false" ;
VAL_ 1271 BatSvrMdLvl4Act 1 "true" 0 "false" ;
VAL_ 1263 BattSOXStat 1 "Use SOC,SOH, & SOF" 0 "Don't Use SOC,SOH, & SOF" ;
VAL_ 1261 MinCrnkCrntVltStat 1 "Use Data" 0 "Don't Use Data" ;
VAL_ 1261 BattTempV 1 "Invalid" 0 "Valid" ;
VAL_ 1261 BattTempM 1 "Use Data" 0 "Don't Use Data" ;
VAL_ 1259 AllNodesVNA 1 "Activate Virtual Network" 0 "No Activation" ;
VAL_ 1259 NAHrDisChrgM 1 "Use Data" 0 "Don't Use Data" ;
VAL_ 1259 NAHrChgM 1 "Use Data" 0 "Don't Use Data" ;
VAL_ 426 EngPstnSnsngOpMode 2 "CAM Failed" 1 "Crank Failed" 0 "Normal" ;
VAL_ 426 AuxTransPrsCmndOn 1 "true" 0 "false" ;
VAL_ 426 EVTCS_CmdTrqCapMd 0 "Full Torque Capacity" 1 "Reduced Capacity 1" 2 "Reserved 1" 3 "Reserved 2" 4 "Reserved 3" 5 "Reserved 4" 6 "Reserved 5" 7 "Reserved 6" ;
VAL_ 426 EVTCS_CrntTrqCapMd 0 "Full Torque Capacity" 1 "Reduced Capacity 1" 2 "Reserved 1" 3 "Reserved 2" 4 "Reserved 3" 5 "Reserved 4" 6 "Reserved 5" 7 "Reserved 6" ;
VAL_ 426 EngPrdctStdyStTorqV 1 "Invalid" 0 "Valid" ;
VAL_ 426 CrnkShftTrqMinOffCapV 1 "Invalid" 0 "Valid" ;
VAL_ 426 CrksftTqMinRunImCapV 1 "Invalid" 0 "Valid" ;
VAL_ 1231 DslExhFluidLvlPrcntV 1 "Invalid" 0 "Valid" ;
VAL_ 723 PerfTrcEngSpdRqStat 6 "Control System Failure Permanent" 5 "Control System Failure Temporary" 4 "Serial Data Failure Permanent" 3 "Serial Data Failure Temporary" 2 "Lost Arbitration" 1 "Request Honored" 0 "No Request" ;
VAL_ 723 PerfTrcEngSpdLmtStat 3 "Rate & Value Limited" 2 "Value Limited" 1 "Rate Limited" 0 "Not Limited" ;
VAL_ 723 PerfTrcTrqRqStat 6 "Control System Failure Permanent" 5 "Control System Failure Temporary" 4 "Serial Data Failure Permanent" 3 "Serial Data Failure Temporary" 2 "Lost Arbitration" 1 "Request Honored" 0 "No Request" ;
VAL_ 723 PerfTrcTrqLmtStat 3 "Rate & Value Limited" 2 "Value Limited" 1 "Rate Limited" 0 "Not Limited" ;
VAL_ 405 EngDistFuelMdDefltd 1 "true" 0 "false" ;
VAL_ 405 EngInjEnbldD 1 "true" 0 "false" ;
VAL_ 405 EngInjEnbldC 1 "true" 0 "false" ;
VAL_ 405 EngInjEnbldB 1 "true" 0 "false" ;
VAL_ 405 EngInjEnbldA 1 "true" 0 "false" ;
VAL_ 405 ThrPosV 1 "Invalid" 0 "Valid" ;
VAL_ 405 MassAirFloV 1 "Invalid" 0 "Valid" ;
VAL_ 405 EngManfldAbsPrsERV 1 "Invalid" 0 "Valid" ;
VAL_ 419 EngRunng 1 "true" 0 "false" ;
VAL_ 1223 PropSysOffTmeV 1 "Invalid" 0 "Valid" ;
VAL_ 1223 PropSysOffTmeM 1 "Use Data" 0 "Don't Use Data" ;
VAL_ 479 EngAutoStpNotProb 1 "true" 0 "false" ;
VAL_ 479 EASSI_UnsdRsrvd2 1 "true" 0 "false" ;
VAL_ 479 EASSI_StlDetd 1 "true" 0 "false" ;
VAL_ 479 EASSI_TrqDetd 1 "true" 0 "false" ;
VAL_ 479 EASSI_FuelReqOn 1 "true" 0 "false" ;
VAL_ 479 EASSI_StrtTyp 7 "Type G" 6 "Type F" 5 "Type E" 4 "Type D" 3 "Type C" 2 "Type B" 1 "Type A" 0 "No Start" ;
VAL_ 479 EASSI_StrtStpSt 3 "Engine Stopping" 2 "Engine Starting" 1 "Engine Running" 0 "Engine Off" ;
VAL_ 479 EASSI_TorqDetdIndet 1 "true" 0 "false" ;
VAL_ 479 ASIRI_Indication08 1 "true" 0 "false" ;
VAL_ 479 ASIRI_Indication07 1 "true" 0 "false" ;
VAL_ 479 ASIRI_Indication06 1 "true" 0 "false" ;
VAL_ 479 ASIRI_Indication05 1 "true" 0 "false" ;
VAL_ 479 ASIRI_Indication04 1 "true" 0 "false" ;
VAL_ 479 ASIRI_Indication03 1 "true" 0 "false" ;
VAL_ 479 ASIRI_Indication02 1 "true" 0 "false" ;
VAL_ 479 ASIRI_Indication01 1 "true" 0 "false" ;
VAL_ 479 PTWrmgWtToShftIO 1 "true" 0 "false" ;
VAL_ 479 PrplsnSysAtv 1 "true" 0 "false" ;
VAL_ 479 PTShftLvrLckRqd 1 "true" 0 "false" ;
VAL_ 211 ActAxleTrqV 1 "Invalid" 0 "Valid" ;
VAL_ 1020 OtsAirTmpEmsnsRelV 1 "Invalid" 0 "Valid" ;
VAL_ 1020 OATEmsnsRelCrValV 1 "Invalid" 0 "Valid" ;
VAL_ 1020 OATEmsnsRelCrValM 0 "Don't Use Data" 1 "Use Data" ;
VAL_ 1020 CatlystOutGasTempEstV 1 "Invalid" 0 "Valid" ;
VAL_ 1020 OtsAirTmpCrValMsk 0 "Don't Use Data" 1 "Use Data" ;
VAL_ 1020 OtsAirTmpV 1 "Invalid" 0 "Valid" ;
VAL_ 1020 OtsAirTmpCrValV 1 "Invalid" 0 "Valid" ;
VAL_ 1020 EngInltSpcfcHmdtyV 1 "Invalid" 0 "Valid" ;
VAL_ 1020 EngInltSpcfcHmdtyM 0 "Don't Use Data" 1 "Use Data" ;
SIG_GROUP_ 197 WhlRotStatLftNDrvn 1 : WRSLNDWhlDisTpRC WRSLNDWhlRotStRst WRSLNDWhlDistVal WRSLNDWhlDistTstm WRSLNDWhlDistPCntr WRSLNDSeqNum;
SIG_GROUP_ 197 WhlRotStatRghtNDrvn 1 : WRSRNDWhlDisTpRC WRSRNDWhlRotStRst WRSRNDWhlDistVal WRSRNDWhlDistTstm WRSRNDWhlDistPCntr WRSRNDSeqNum;
SIG_GROUP_ 505 PTOTransGearReq 1 : PTOTGRReqdGear PTOTGRReqType;
SIG_GROUP_ 505 PltfrmEngSpdCmmnd 1 : PltfrmEngSpdCmdMdAct PltfrmEngSpdReq;
SIG_GROUP_ 193 WhlRotatStatLftDrvn 1 : WRSLDWhlDisTpRC WRSLDSeqNum WRSLDWhlDistVal WRSLDWhlRotStatRst WRSLDWhlDistTmstm WRSLDWhlDistPlsCntr;
SIG_GROUP_ 193 WhlRotatStatRtDrvn 1 : WRSRDWhlDisTpRC WRSRDSeqNum WRSRDWhlRotStatRst WRSRDWhlDistVal WRSRDWhlDistTmstm WRSRDWhlDistPlsCntr;
SIG_GROUP_ 481 CrsCntrlSwStat 1 : CrsCntrlSwStCanSwAct CrsCntrlSwStSwDataIntgty CrsCntrlSwStSpdInSwAct CrsCntrlSwStSpDcSwAct CrsCntrlSwStSetSwAct CrsCntrlSwStResSwAct CrsCntrlSwStOnSwAct;
SIG_GROUP_ 455 ChsSysEngTorqReqER 1 : CSETRER_TorqReqVal CSETRER_TqIntvnTyp;
SIG_GROUP_ 761 AutoBrkFeatInhbt 1 : ABFI_CollPrepSysInhbt ABFI_RrVirtlBmprInh;
SIG_GROUP_ 761 WhlSpdSnsLgsDiagStat 1 : WhlSpdSnsgDTCIndex WhlSpdSnsgDTCStat;
SIG_GROUP_ 489 BrkSysTransGearReq 1 : BSTGRReqdGear BSTGRReqType;
SIG_GROUP_ 241 BrkPedInitTrvlAchvdStat 1 : BrkPedTrvlAchvd BrkPedTrvlAchvdV;
SIG_GROUP_ 1271 BatSvrMdCurrTrgr 1 : BSMCT_RawVal BSMCT_Mult;
SIG_GROUP_ 426 EngVarTrqCapStat 1 : EVTCS_CmdTrqCapMd EVTCS_CrntTrqCapMd;
SIG_GROUP_ 479 EngAutoStrtStpInfo 1 : EASSI_UnsdRsrvd2 EASSI_StlDetd EASSI_TrqDetd EASSI_FuelReqOn EASSI_StrtTyp EASSI_StrtStpSt EASSI_TorqDetdIndet;
SIG_GROUP_ 479 AutoStpInhbtRsnInd 1 : ASIRI_Indication08 ASIRI_Indication07 ASIRI_Indication06 ASIRI_Indication05 ASIRI_Indication04 ASIRI_Indication03 ASIRI_Indication02 ASIRI_Indication01;
